VERSION ""

NS_ :

BS_:

BU_: VCM TCM ECM EBS ACM

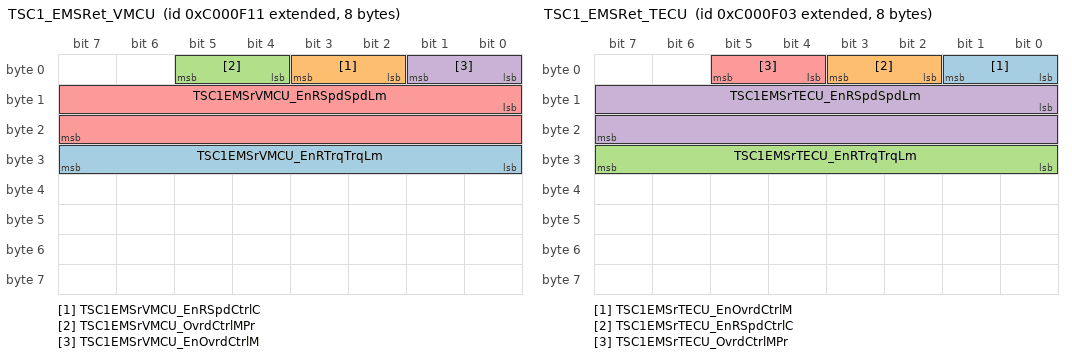
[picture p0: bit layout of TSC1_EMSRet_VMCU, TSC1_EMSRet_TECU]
BO_ 2348814097 TSC1_EMSRet_VMCU: 8 VCM
 SG_ TSC1EMSrVMCU_EnRTrqTrqLm : 24|8@1+ (1,-125) [-125|130] "Percent"  EBS,ECM
 SG_ TSC1EMSrVMCU_EnRSpdCtrlC : 2|2@1+ (1,0) [0|0] ""  EBS,ECM
 SG_ TSC1EMSrVMCU_OvrdCtrlMPr : 4|2@1+ (1,0) [0|0] ""  EBS,ECM
 SG_ TSC1EMSrVMCU_EnOvrdCtrlM : 0|2@1+ (1,0) [0|0] ""  EBS,ECM
 SG_ TSC1EMSrVMCU_EnRSpdSpdLm : 8|16@1+ (0.125,0) [0|8191.875] "rpm"  EBS,ECM

BO_ 2348814083 TSC1_EMSRet_TECU: 8 TCM
 SG_ TSC1EMSrTECU_EnOvrdCtrlM : 0|2@1+ (1,0) [0|0] ""  VCM,ECM
 SG_ TSC1EMSrTECU_EnRSpdCtrlC : 2|2@1+ (1,0) [0|0] ""  VCM,ECM
 SG_ TSC1EMSrTECU_EnRTrqTrqLm : 24|8@1+ (1,-125) [-125|130] "Percent"  VCM,ECM
 SG_ TSC1EMSrTECU_EnRSpdSpdLm : 8|16@1+ (0.125,0) [0|8191.875] "rpm"  ECM,VCM
 SG_ TSC1EMSrTECU_OvrdCtrlMPr : 4|2@1+ (1,0) [0|0] ""  VCM,ECM

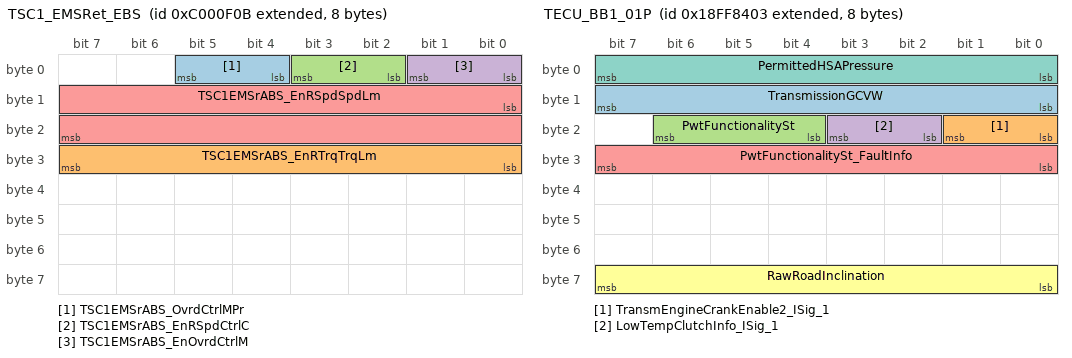
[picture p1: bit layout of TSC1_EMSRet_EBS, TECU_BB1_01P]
BO_ 2348814091 TSC1_EMSRet_EBS: 8 EBS
 SG_ TSC1EMSrABS_OvrdCtrlMPr : 4|2@1+ (1,0) [0|0] ""  TCM,ECM
 SG_ TSC1EMSrABS_EnRTrqTrqLm : 24|8@1+ (1,-125) [-125|130] "Percent"  ECM,TCM
 SG_ TSC1EMSrABS_EnRSpdCtrlC : 2|2@1+ (1,0) [0|0] ""  ECM,TCM
 SG_ TSC1EMSrABS_EnOvrdCtrlM : 0|2@1+ (1,0) [0|0] ""  TCM,ECM
 SG_ TSC1EMSrABS_EnRSpdSpdLm : 8|16@1+ (0.125,0) [0|8191.875] "rpm"  TCM,ECM

BO_ 2566846467 TRF1_X_TECU: 8 TCM
 SG_ TransmissionOilLevel_ISig_1 : 8|8@1+ (0.4,0) [0|102] "Percent"  VCM
 SG_ TransmissionOilTemp_ISig_1 : 32|16@1+ (0.03125,-273) [-273|1774.96875] "DegreeC"  ECM,VCM

BO_ 2565603075 TPDT_X_TCM: 8 TCM
 SG_ TPDT_SeqNo_TCM : 0|8@1+ (1,0) [0|0] ""  VCM

BO_ 2565603088 TPDT_X_RECU: 8 ACM
 SG_ TPDT_SeqNo_RECU : 0|8@1+ (1,0) [0|0] ""  VCM,ECM,EBS,TCM

BO_ 2565603087 TPDT_X_ECMRet: 8 ECM
 SG_ TPDT_SeqNo_ECMret : 0|8@1+ (1,0) [0|0] ""  VCM,EBS,TCM,ACM

BO_ 2565603072 TPDT_X_ECM: 8 ECM
 SG_ TPDT_SeqNo_ECM : 0|8@1+ (1,0) [0|0] ""  EBS,VCM,TCM,ACM

BO_ 2565603083 TPDT_X_EBS: 8 EBS
 SG_ TPDT_SeqNo_EBS : 0|8@1+ (1,0) [0|0] ""  VCM

BO_ 2565603133 TPDT_X_ACM: 8 ACM
 SG_ TPDT_SeqNo_ACM : 0|8@1+ (1,0) [0|0] ""  VCM

BO_ 2565668611 TPCM_X_TCM: 8 TCM
 SG_ TPCM_ControlByte_TCM : 0|8@1+ (1,0) [0|0] ""  VCM

BO_ 2565668624 TPCM_X_RECU: 8 ACM
 SG_ TPCM_ControlByte_RECU : 0|8@1+ (1,0) [0|0] ""  VCM,EBS,ECM,TCM

BO_ 2565668623 TPCM_X_ECMRet: 8 ECM
 SG_ TPCM_ControlByte_ECMret : 0|8@1+ (1,0) [0|0] ""  VCM,EBS,ACM,TCM

BO_ 2565668608 TPCM_X_ECM: 8 ECM
 SG_ TPCM_ControlByte_ECM : 0|8@1+ (1,0) [0|0] ""  VCM,EBS,TCM,ACM

BO_ 2565668619 TPCM_X_EBS: 8 EBS
 SG_ TPCM_ControlByte_EBS : 0|8@1+ (1,0) [0|0] ""  VCM

BO_ 2565668669 TPCM_X_ACM: 8 ACM
 SG_ TPCM_ControlByte_ACM : 0|8@1+ (1,0) [0|0] ""  VCM

BO_ 2566882307 TECU_BB1_01P: 8 TCM
 SG_ TransmissionGCVW : 8|8@1+ (1000,0) [0|255000] "kg"  ECM,VCM
 SG_ TransmEngineCrankEnable2_ISig_1 : 16|2@1+ (1,0) [0|0] ""  VCM
 SG_ PwtFunctionalitySt : 20|3@1+ (1,0) [0|0] ""  VCM
 SG_ LowTempClutchInfo_ISig_1 : 18|2@1+ (1,0) [0|0] ""  VCM
 SG_ PwtFunctionalitySt_FaultInfo : 24|8@1+ (1,0) [0|0] ""  VCM
 SG_ RawRoadInclination : 56|8@1+ (0.2,-25) [-25|26] "Percent"  VCM
 SG_ PermittedHSAPressure : 0|8@1+ (0.4,0) [0|102] "Percent"  EBS,VCM

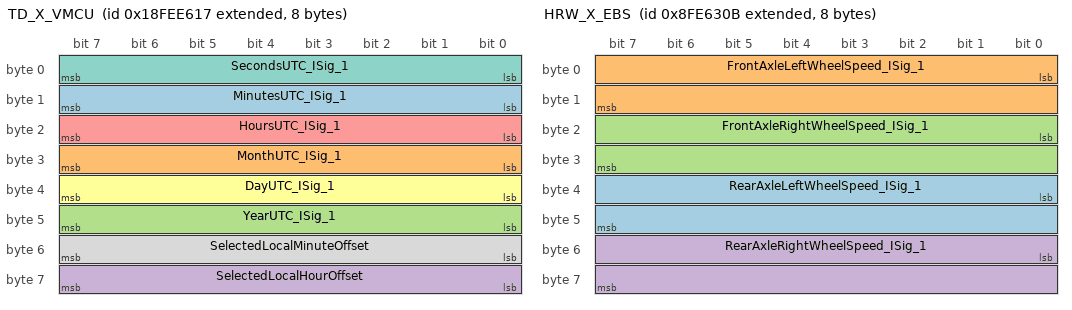
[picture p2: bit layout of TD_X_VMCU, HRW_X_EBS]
BO_ 2566841879 TD_X_VMCU: 8 VCM
 SG_ MinutesUTC_ISig_1 : 8|8@1+ (1,0) [0|255] "min"  ACM,EBS,ECM,TCM
 SG_ MonthUTC_ISig_1 : 24|8@1+ (1,0) [0|255] "Months"  ACM,ECM,EBS,TCM
 SG_ YearUTC_ISig_1 : 40|8@1+ (1,1985) [1985|2240] "Years"  ACM,TCM,ECM,EBS
 SG_ SelectedLocalHourOffset : 56|8@1+ (1,-125) [-125|130] "h"  EBS
 SG_ HoursUTC_ISig_1 : 16|8@1+ (1,0) [0|255] "h"  ECM,TCM,ACM,EBS
 SG_ DayUTC_ISig_1 : 32|8@1+ (0.25,0) [0|63.75] "Days"  EBS,ECM,TCM,ACM
 SG_ SecondsUTC_ISig_1 : 0|8@1+ (0.25,0) [0|63.75] "s"  ECM,ACM,TCM,EBS
 SG_ SelectedLocalMinuteOffset : 48|8@1+ (1,-125) [-125|130] "min"  EBS

BO_ 2365528579 TCM_02P_C01: 8 TCM
 SG_ RoadInclination_ISig_1 : 16|8@1+ (0.2,-25) [-25|26] "Percent"  ECM,VCM,EBS
 SG_ TransmOutputShaftSpeedSigned : 0|16@1+ (0.125,-4000) [-4000|4191.875] "rpm"  EBS,VCM

BO_ 2499792656 RECU_BB1_01P: 8 ACM
 SG_ DrivelineRetarderStat_ISig_1 : 0|2@1+ (1,0) [0|0] ""  VCM

BO_ 2566840592 RC_X_RECU: 19 ACM
 SG_ DrivelineRetarderLocation : 4|4@1+ (1,0) [0|0] ""  EBS,ECM,VCM
 SG_ DrivelineRetarderType : 0|4@1+ (1,0) [0|0] ""  EBS
 SG_ DrivelineRetarderRefTorque : 128|16@1+ (1,0) [0|65535] "Nm"  EBS,ECM,VCM,TCM

BO_ 2566840591 RC_X_EMSRet: 19 ECM
 SG_ EngRetConf_PerTrqAtP3 : 80|8@1+ (1,-125) [-125|130] "Percent"  TCM,EBS,VCM
 SG_ EngRetConf_RetSpeedAtP5 : 112|16@1+ (0.125,0) [0|8191.875] "rpm"  VCM,EBS,TCM
 SG_ EngRetConf_MaxRetSpeedP2 : 40|16@1+ (0.125,0) [0|8191.875] "rpm"  EBS,VCM,TCM
 SG_ EngRetConf_RetSpeedAtP3 : 64|16@1+ (0.125,0) [0|8191.875] "rpm"  TCM,VCM,EBS
 SG_ EngRetConf_PerTrqAtP4 : 104|8@1+ (1,-125) [-125|130] "Percent"  EBS,VCM,TCM
 SG_ EngRetConf_PerTrqAtP5 : 144|8@1+ (1,-125) [-125|130] "Percent"  EBS,TCM,VCM
 SG_ EngRetConf_RetCtrlMethod : 8|8@1+ (1,0) [0|255] "Step"  TCM,VCM,EBS
 SG_ ReferenceEngineRetarderTorque : 128|16@1+ (1,0) [0|65535] "Nm"  EBS,ACM,VCM,TCM
 SG_ EngRetConf_RetSpeedAtP4 : 88|16@1+ (0.125,0) [0|8191.875] "rpm"  VCM,TCM,EBS
 SG_ EngRetConf_PerTrqAtMaxSpeedP2 : 56|8@1+ (1,-125) [-125|130] "Percent"  VCM,EBS,TCM
 SG_ EngRetConf_speedAtIdleP1 : 16|16@1+ (0.125,0) [0|8191.875] "rpm"  VCM,TCM,EBS
 SG_ EngRetConf_PerTrqAtIdleP1 : 32|8@1+ (1,-125) [-125|130] "Percent"  TCM,VCM,EBS

BO_ 2671833640 PhysDiagRespMsg_F2_28_C01: 8 EBS
 SG_ PhysDiagRespSig_F2_28_ISig_1 : 0|64@1+ (1,0) [0|0] ""  VCM

BO_ 2671833617 PhysDiagRespMsg_F2_11_C01: 8 ACM
 SG_ PhysDiagRespSig_F2_11_ISig_1 : 0|64@1+ (1,0) [0|0] ""  VCM

BO_ 2671833361 PhysDiagRespMsg_F1_11_C01: 8 ACM
 SG_ PhysDiagRespSig_F1_11_ISig_1 : 0|64@1+ (1,0) [0|0] ""  VCM

BO_ 2671782130 PhysDiagReqMsg_28_F2_C01: 8 VCM
 SG_ PhysDiagReqSig_28_F2_ISig_1 : 0|64@1+ (1,0) [0|0] ""  EBS

BO_ 2671776242 PhysDiagReqMsg_11_F2_C01: 8 VCM
 SG_ PhysDiagReqSig_11_F2_ISig_1 : 0|64@1+ (1,0) [0|0] ""  ACM

BO_ 2671776241 PhysDiagReqMsg_11_F1_C01: 8 VCM
 SG_ PhysDiagReqSig_11_F1_ISig_1 : 0|64@1+ (1,0) [0|0] ""  ACM

BO_ 2566759457 PTODE_X_VMCU: 8 VCM
 SG_ Pto1EnableSwitch : 6|2@1+ (1,0) [0|0] ""  TCM
 SG_ Pto2EnableSwitch : 4|2@1+ (1,0) [0|0] ""  TCM

BO_ 2566759427 PTODE_X_TECU: 8 TCM
 SG_ Pto2EngagementConsent : 20|2@1+ (1,0) [0|0] ""  VCM
 SG_ Pto1EngagementConsent : 22|2@1+ (1,0) [0|0] ""  VCM

BO_ 2671850481 OBDFuncDiagMsg_C01: 8 VCM
 SG_ FuncDiagDataOBD_ISig_1 : 0|64@1+ (1,0) [0|0] ""  ACM

BO_ 2566844928 LFE_X_EMS: 8 ECM
 SG_ InstantaneousFuelEconomy : 16|16@1+ (0.001953125,0) [0|127.998046875] "km_per_l"  VCM
 SG_ EngineFuelRate_ISig_1 : 0|16@1+ (0.05,0) [0|3276.75] "l_per_h"  VCM

BO_ 2566825472 IMT1_X_EMS: 8 ECM
 SG_ EngineTurbo1BoostPressure_ISig_1 : 0|16@1+ (0.125,0) [0|8191.875] "kPa"  VCM,ACM

BO_ 2298372875 HRW_X_EBS: 8 EBS
 SG_ RearAxleLeftWheelSpeed_ISig_1 : 32|16@1+ (0.00390625,0) [0|255.99609375] "Km_per_h"  VCM,TCM,ECM
 SG_ FrontAxleLeftWheelSpeed_ISig_1 : 0|16@1+ (0.00390625,0) [0|255.99609375] "Km_per_h"  ECM,VCM,TCM
 SG_ FrontAxleRightWheelSpeed_ISig_1 : 16|16@1+ (0.00390625,0) [0|255.99609375] "Km_per_h"  TCM,ECM,VCM
 SG_ RearAxleRightWheelSpeed_ISig_1 : 48|16@1+ (0.00390625,0) [0|255.99609375] "Km_per_h"  VCM,TCM,ECM

BO_ 2566719744 HRLFC_X_EMS: 8 ECM
 SG_ HighResEngineTotalFuelUsed : 32|32@1+ (0.001,0) [0|4294967.295] "l"  VCM

BO_ 2566841600 HOURS_X_EMS: 8 ECM
 SG_ EngineRevolutions : 32|32@1+ (1000,0) [0|4294967295000] "r"  VCM

BO_ 2566801923 ETC7_X_TECU: 8 TCM
 SG_ TransmEngineCrankEnable_ISig_1 : 12|2@1+ (1,0) [0|0] ""  VCM

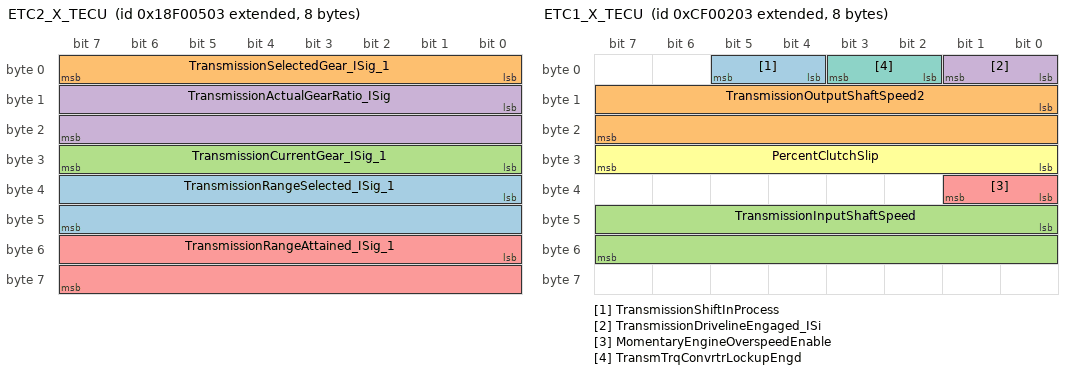
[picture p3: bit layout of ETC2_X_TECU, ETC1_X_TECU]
BO_ 2565866755 ETC2_X_TECU: 8 TCM
 SG_ TransmissionRangeSelected_ISig_1 : 32|16@1+ (1,0) [0|0] ""  VCM
 SG_ TransmissionSelectedGear_ISig_1 : 0|8@1+ (1,-125) [-125|130] "GearValue"  ECM,VCM
 SG_ TransmissionCurrentGear_ISig_1 : 24|8@1+ (1,-125) [-125|130] "GearValue"  VCM,ECM,EBS
 SG_ TransmissionActualGearRatio_ISig : 8|16@1+ (0.001,0) [0|65.535] "NotApplicable"  ECM,VCM
 SG_ TransmissionRangeAttained_ISig_1 : 48|16@1+ (1,0) [0|0] ""  VCM

BO_ 2364539395 ETC1_X_TECU: 8 TCM
 SG_ TransmissionShiftInProcess : 4|2@1+ (1,0) [0|0] ""  ECM,VCM,EBS
 SG_ TransmissionOutputShaftSpeed2 : 8|16@1+ (0.125,0) [0|8191.875] "rpm"  VCM
 SG_ TransmissionInputShaftSpeed : 40|16@1+ (0.125,0) [0|8191.875] "rpm"  EBS,VCM
 SG_ TransmissionDrivelineEngaged_ISi : 0|2@1+ (1,0) [0|0] ""  VCM,ECM,EBS
 SG_ MomentaryEngineOverspeedEnable : 32|2@1+ (1,0) [0|0] ""  VCM,ECM
 SG_ PercentClutchSlip : 24|8@1+ (0.4,0) [0|102] "Percent"  ECM,VCM,EBS
 SG_ TransmTrqConvrtrLockupEngd : 2|2@1+ (1,0) [0|0] ""  ECM,VCM

BO_ 2566843904 ET1_X_EMS: 8 ECM
 SG_ EngineCoolantTemp_stat_ISig_1 : 0|8@1+ (1,-40) [-40|215] "DegreeC"  VCM,ACM,TCM
 SG_ EngineOilTemperature : 16|16@1+ (0.03125,-273) [-273|1774.96875] "DegreeC"  TCM,VCM

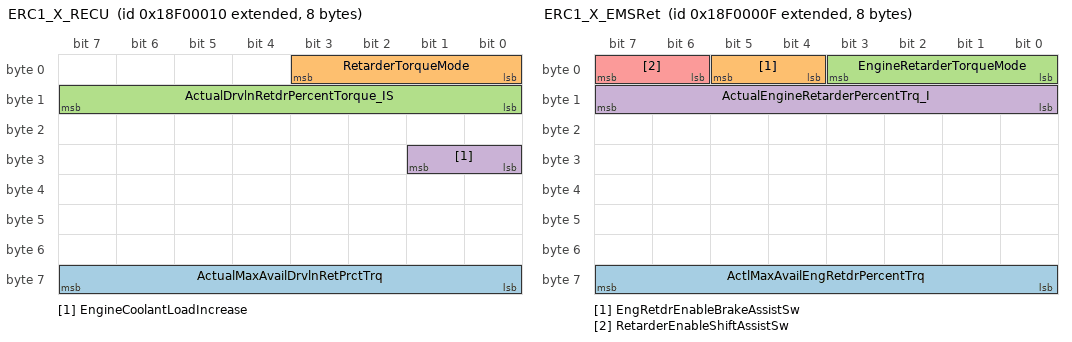
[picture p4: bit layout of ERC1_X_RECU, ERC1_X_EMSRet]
BO_ 2565865488 ERC1_X_RECU: 8 ACM
 SG_ ActualMaxAvailDrvlnRetPrctTrq : 56|8@1+ (1,-125) [-125|130] "Percent"  ECM,TCM,VCM,EBS
 SG_ RetarderTorqueMode : 0|4@1+ (1,0) [0|0] ""  ECM,VCM
 SG_ ActualDrvlnRetdrPercentTorque_IS : 8|8@1+ (1,-125) [-125|130] "Percent"  EBS,VCM,ECM,TCM
 SG_ EngineCoolantLoadIncrease : 24|2@1+ (1,0) [0|0] ""  VCM,ECM

BO_ 2565865487 ERC1_X_EMSRet: 8 ECM
 SG_ ActlMaxAvailEngRetdrPercentTrq : 56|8@1+ (1,-125) [-125|130] "Percent"  VCM,EBS
 SG_ EngRetdrEnableBrakeAssistSw : 4|2@1+ (1,0) [0|0] ""  VCM,TCM
 SG_ EngineRetarderTorqueMode : 0|4@1+ (1,0) [0|0] ""  VCM
 SG_ ActualEngineRetarderPercentTrq_I : 8|8@1+ (1,-125) [-125|130] "Percent"  EBS,TCM,VCM,ACM
 SG_ RetarderEnableShiftAssistSw : 6|2@1+ (1,0) [0|0] ""  TCM,VCM

BO_ 2566864640 EMS_BB1_01P: 8 ECM
 SG_ EngineActiveStatus_ISig_1 : 8|4@1+ (1,0) [0|0] ""  TCM,EBS,VCM
 SG_ DrvrDemandEngRetdrPercentTrq : 0|8@1+ (1,-125) [-125|130] "Percent"  VCM,EBS

BO_ 2364541440 EGF1_X_EMS: 8 ECM
 SG_ EngineIntakeAirRate : 16|16@1+ (0.05,0) [0|3276.75] "Kg_per_h"  VCM

BO_ 2566844160 EFLP1_X_EMS: 8 ECM
 SG_ EngineOilPressure : 24|8@1+ (4,0) [0|1020] "kPa"  VCM
 SG_ EngineOilLevel : 16|8@1+ (0.4,0) [0|102] "Percent"  VCM

BO_ 2566840064 EEC3_X_EMS: 8 ECM
 SG_ NominalFrictionPercentTorque_ISi : 0|8@1+ (1,-125) [-125|130] "Percent"  ACM,TCM,VCM,EBS

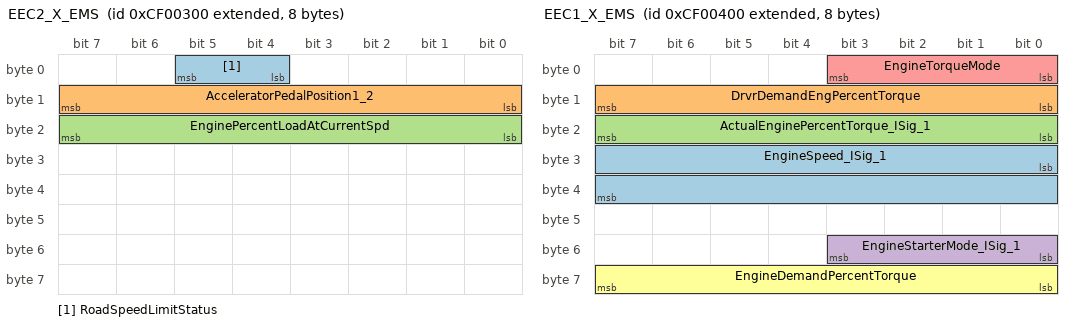
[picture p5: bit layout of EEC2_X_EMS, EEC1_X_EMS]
BO_ 2364539648 EEC2_X_EMS: 8 ECM
 SG_ RoadSpeedLimitStatus : 4|2@1+ (1,0) [0|0] ""  TCM,VCM
 SG_ AcceleratorPedalPosition1_2 : 8|8@1+ (0.4,0) [0|102] "Percent"  TCM,VCM
 SG_ EnginePercentLoadAtCurrentSpd : 16|8@1+ (1,0) [0|255] "Percent"  TCM,ACM,VCM

BO_ 2364539904 EEC1_X_EMS: 8 ECM
 SG_ EngineSpeed_ISig_1 : 24|16@1+ (0.125,0) [0|8191.875] "rpm"  VCM,ACM,TCM,EBS
 SG_ DrvrDemandEngPercentTorque : 8|8@1+ (1,-125) [-125|130] "Percent"  VCM,TCM,EBS
 SG_ ActualEnginePercentTorque_ISig_1 : 16|8@1+ (1,-125) [-125|130] "Percent"  TCM,EBS,VCM
 SG_ EngineStarterMode_ISig_1 : 48|4@1+ (1,0) [0|0] ""  VCM
 SG_ EngineTorqueMode : 0|4@1+ (1,0) [0|0] ""  TCM,EBS,VCM
 SG_ EngineDemandPercentTorque : 56|8@1+ (1,-125) [-125|130] "Percent"  VCM,TCM

BO_ 2566841088 EC1_X_EMS: 39 ECM
 SG_ EngConf_EngSpeedAt_P3 : 48|16@1+ (0.125,0) [0|8191.875] "rpm"  VCM,TCM,EBS
 SG_ EngConf_EngSpeedAtIdle_P1 : 0|16@1+ (0.125,0) [0|8191.875] "rpm"  EBS,VCM,TCM
 SG_ EngConf_EngTorqueAtIdle_P1 : 16|8@1+ (1,-125) [-125|130] "Percent"  VCM,EBS,TCM
 SG_ EngConf_EngSpeedAt_P4 : 72|16@1+ (0.125,0) [0|8191.875] "rpm"  EBS,VCM,TCM
 SG_ EngineReferenceTorque_ISig_1 : 152|16@1+ (1,0) [0|65535] "Nm"  VCM,EBS,TCM,ACM
 SG_ EngConf_EngTorqueAt_P5 : 112|8@1+ (1,-125) [-125|130] "Percent"  EBS,VCM,TCM
 SG_ EngConf_EngSpeedAtHighIdle_P6 : 120|16@1+ (0.125,0) [0|8191.875] "rpm"  EBS,VCM,TCM
 SG_ EngConf_EngTorqueAt_P3 : 64|8@1+ (1,-125) [-125|130] "Percent"  VCM,TCM,EBS
 SG_ EngConf_EngSpeedAt_P5 : 96|16@1+ (0.125,0) [0|8191.875] "rpm"  VCM,EBS,TCM
 SG_ EngConf_EngMaxMomOvSpeed_P7 : 168|16@1+ (0.125,0) [0|8191.875] "rpm"  VCM,TCM,EBS
 SG_ EngConf_EngTorqueAt_P4 : 88|8@1+ (1,-125) [-125|130] "Percent"  EBS,VCM,TCM
 SG_ EngConf_EngTorqueAt_P2 : 40|8@1+ (1,-125) [-125|130] "Percent"  TCM,VCM,EBS
 SG_ EngConf_EngSpeedAt_P2 : 24|16@1+ (0.125,0) [0|8191.875] "rpm"  EBS,VCM,TCM
 SG_ EngConf_MaxMomOverrideTimeLim : 184|8@1+ (0.1,0) [0|25.5] "s"  TCM,EBS,VCM

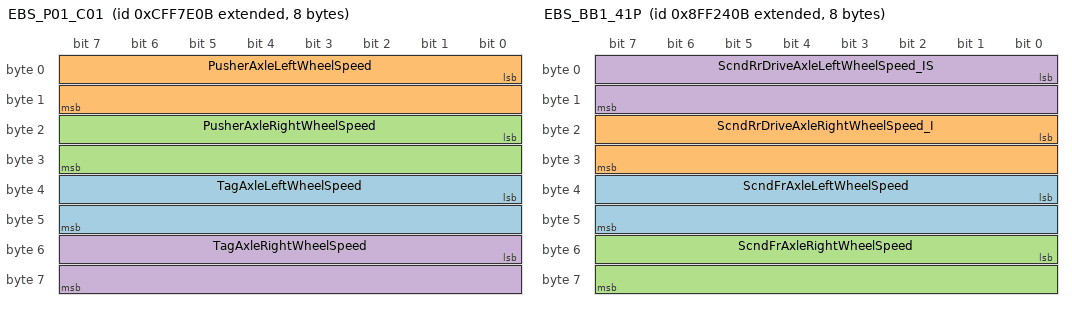
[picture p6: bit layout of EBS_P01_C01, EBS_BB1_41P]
BO_ 2365554187 EBS_P01_C01: 8 EBS
 SG_ TagAxleLeftWheelSpeed : 32|16@1+ (0.00390625,0) [0|255.99609375] "Km_per_h"  VCM
 SG_ PusherAxleLeftWheelSpeed : 0|16@1+ (0.00390625,0) [0|255.99609375] "Km_per_h"  VCM
 SG_ PusherAxleRightWheelSpeed : 16|16@1+ (0.00390625,0) [0|255.99609375] "Km_per_h"  VCM
 SG_ TagAxleRightWheelSpeed : 48|16@1+ (0.00390625,0) [0|255.99609375] "Km_per_h"  VCM

BO_ 2298445579 EBS_BB1_44P: 8 EBS
 SG_ ThrdRrDriveAxLeftWheelSpeed_ISig : 16|16@1+ (0.00390625,0) [0|255.99609375] "Km_per_h"  ECM,TCM,VCM
 SG_ ThrdRrDriveAxRightWheelSpeed_ISi : 0|16@1+ (0.00390625,0) [0|255.99609375] "Km_per_h"  ECM,VCM,TCM

BO_ 2566852619 EBS_BB1_43P: 8 EBS
 SG_ WheelCircumference_TireId : 8|8@1+ (1,0) [0|255] "NotApplicable"  VCM
 SG_ WheelCircumference_Value : 0|8@1+ (0.06,0) [0|15.3] "m"  VCM

BO_ 2298422539 EBS_BB1_42P: 8 EBS
 SG_ ActualPusherWheelAngle : 0|16@1+ (0.01,-50) [-50|605.35] "deg"  VCM
 SG_ ActualTagWheelAngle : 16|16@1+ (0.01,-50) [-50|605.35] "deg"  VCM

BO_ 2298422283 EBS_BB1_41P: 8 EBS
 SG_ ScndFrAxleLeftWheelSpeed : 32|16@1+ (0.00390625,0) [0|255.99609375] "Km_per_h"  ECM,TCM,VCM
 SG_ ScndRrDriveAxleRightWheelSpeed_I : 16|16@1+ (0.00390625,0) [0|255.99609375] "Km_per_h"  VCM,TCM,ECM
 SG_ ScndFrAxleRightWheelSpeed : 48|16@1+ (0.00390625,0) [0|255.99609375] "Km_per_h"  VCM,ECM,TCM
 SG_ ScndRrDriveAxleLeftWheelSpeed_IS : 0|16@1+ (0.00390625,0) [0|255.99609375] "Km_per_h"  VCM,ECM,TCM

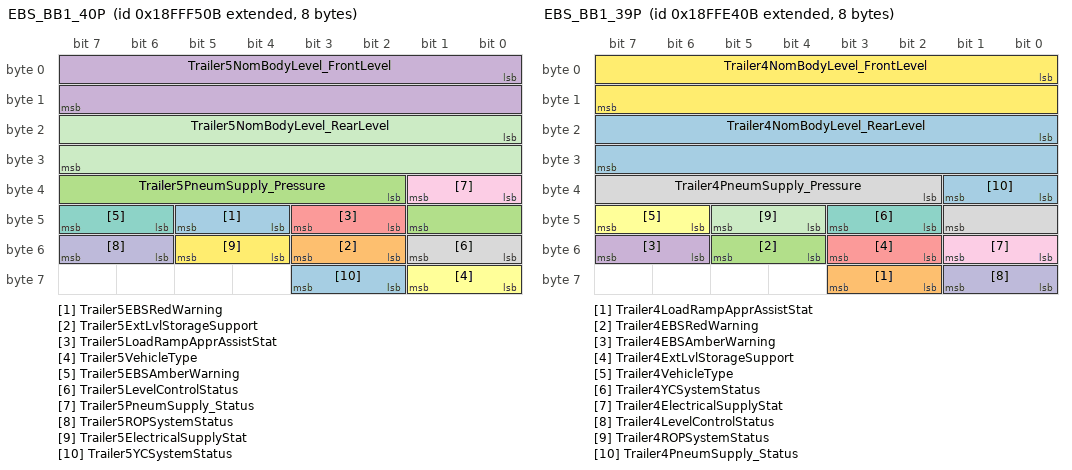
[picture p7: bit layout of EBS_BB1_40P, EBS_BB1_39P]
BO_ 2566911243 EBS_BB1_40P: 8 EBS
 SG_ Trailer5EBSRedWarning : 44|2@1+ (1,0) [0|0] ""  VCM
 SG_ Trailer5ExtLvlStorageSupport : 50|2@1+ (1,0) [0|0] ""  VCM
 SG_ Trailer5PneumSupply_Pressure : 34|8@1+ (5,0) [0|1275] "kPa"  VCM
 SG_ Trailer5NomBodyLevel_FrontLevel : 0|16@1+ (1,0) [0|65535] "mm"  VCM
 SG_ Trailer5LoadRampApprAssistStat : 42|2@1+ (1,0) [0|0] ""  VCM
 SG_ Trailer5VehicleType : 56|2@1+ (1,0) [0|0] ""  VCM
 SG_ Trailer5EBSAmberWarning : 46|2@1+ (1,0) [0|0] ""  VCM
 SG_ Trailer5LevelControlStatus : 48|2@1+ (1,0) [0|0] ""  VCM
 SG_ Trailer5PneumSupply_Status : 32|2@1+ (1,0) [0|0] ""  VCM
 SG_ Trailer5ROPSystemStatus : 54|2@1+ (1,0) [0|0] ""  VCM
 SG_ Trailer5NomBodyLevel_RearLevel : 16|16@1+ (1,0) [0|65535] "mm"  VCM
 SG_ Trailer5ElectricalSupplyStat : 52|2@1+ (1,0) [0|0] ""  VCM
 SG_ Trailer5YCSystemStatus : 58|2@1+ (1,0) [0|0] ""  VCM

BO_ 2566906891 EBS_BB1_39P: 8 EBS
 SG_ Trailer4NomBodyLevel_RearLevel : 16|16@1+ (1,0) [0|65535] "mm"  VCM
 SG_ Trailer4LoadRampApprAssistStat : 58|2@1+ (1,0) [0|0] ""  VCM
 SG_ Trailer4EBSRedWarning : 52|2@1+ (1,0) [0|0] ""  VCM
 SG_ Trailer4EBSAmberWarning : 54|2@1+ (1,0) [0|0] ""  VCM
 SG_ Trailer4ExtLvlStorageSupport : 50|2@1+ (1,0) [0|0] ""  VCM
 SG_ Trailer4VehicleType : 46|2@1+ (1,0) [0|0] ""  VCM
 SG_ Trailer4YCSystemStatus : 42|2@1+ (1,0) [0|0] ""  VCM
 SG_ Trailer4PneumSupply_Pressure : 34|8@1+ (5,0) [0|1275] "kPa"  VCM
 SG_ Trailer4ElectricalSupplyStat : 48|2@1+ (1,0) [0|0] ""  VCM
 SG_ Trailer4LevelControlStatus : 56|2@1+ (1,0) [0|0] ""  VCM
 SG_ Trailer4ROPSystemStatus : 44|2@1+ (1,0) [0|0] ""  VCM
 SG_ Trailer4NomBodyLevel_FrontLevel : 0|16@1+ (1,0) [0|65535] "mm"  VCM
 SG_ Trailer4PneumSupply_Status : 32|2@1+ (1,0) [0|0] ""  VCM

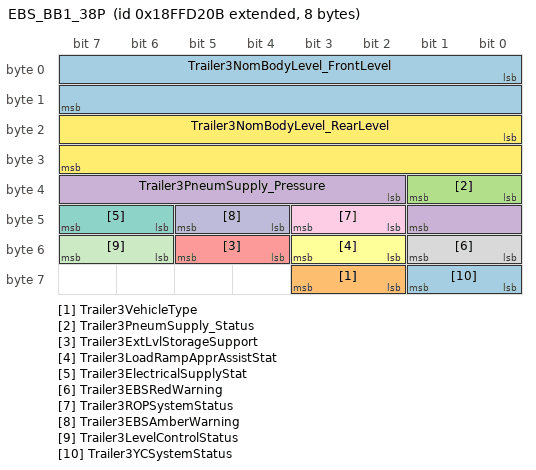
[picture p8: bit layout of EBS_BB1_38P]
BO_ 2566902283 EBS_BB1_38P: 8 EBS
 SG_ Trailer3NomBodyLevel_FrontLevel : 0|16@1+ (1,0) [0|65535] "mm"  VCM
 SG_ Trailer3VehicleType : 58|2@1+ (1,0) [0|0] ""  VCM
 SG_ Trailer3PneumSupply_Status : 32|2@1+ (1,0) [0|0] ""  VCM
 SG_ Trailer3PneumSupply_Pressure : 34|8@1+ (5,0) [0|1275] "kPa"  VCM
 SG_ Trailer3ExtLvlStorageSupport : 52|2@1+ (1,0) [0|0] ""  VCM
 SG_ Trailer3LoadRampApprAssistStat : 50|2@1+ (1,0) [0|0] ""  VCM
 SG_ Trailer3ElectricalSupplyStat : 46|2@1+ (1,0) [0|0] ""  VCM
 SG_ Trailer3EBSRedWarning : 48|2@1+ (1,0) [0|0] ""  VCM
 SG_ Trailer3ROPSystemStatus : 42|2@1+ (1,0) [0|0] ""  VCM
 SG_ Trailer3EBSAmberWarning : 44|2@1+ (1,0) [0|0] ""  VCM
 SG_ Trailer3LevelControlStatus : 54|2@1+ (1,0) [0|0] ""  VCM
 SG_ Trailer3NomBodyLevel_RearLevel : 16|16@1+ (1,0) [0|65535] "mm"  VCM
 SG_ Trailer3YCSystemStatus : 56|2@1+ (1,0) [0|0] ""  VCM

CM_ BO_ 2348814097 "PGN 0 Torque/Speed Control 1, From VMCU to EMS Retarder";
CM_ SG_ 2348814097 TSC1EMSrVMCU_EnRTrqTrqLm "254 Error ; 255 Not available";
CM_ SG_ 2348814097 TSC1EMSrVMCU_EnRSpdSpdLm "65024 - 65279 Error ; 65280 - 65535 Not available";
CM_ BO_ 2348814083 "PGN 0 Torque/Speed Control 1, From TECU to EMS Retarder";
CM_ SG_ 2348814083 TSC1EMSrTECU_EnRTrqTrqLm "254 Error ; 255 Not available";
CM_ SG_ 2348814083 TSC1EMSrTECU_EnRSpdSpdLm "65024 - 65279 Error ; 65280 - 65535 Not available";
CM_ BO_ 2348814091 "PGN 0 Torque/Speed Control 1, From EBS to EMS Retarder";
CM_ SG_ 2348814091 TSC1EMSrABS_EnRTrqTrqLm "254 Error ; 255 Not available";
CM_ SG_ 2348814091 TSC1EMSrABS_EnRSpdSpdLm "65024 - 65279 Error ; 65280 - 65535 Not available";
CM_ BO_ 2566846467 "PGN 65272 Transmission Fluids 1";
CM_ BO_ 2566841879 "PGN 65254 Time/Date, From HMIIOM";
CM_ BO_ 2566840592 "PGN 65249 Retarder Configuration from RECU";
CM_ BO_ 2566840591 "PGN 65249 Retarder Configuration from EMSRetarder";
CM_ BO_ 2566759457 "PGN 64932 PTO Drive Engagement";
CM_ BO_ 2566759427 "PGN 64932 PTO Drive Engagement
";
CM_ BO_ 2566844928 "PGN 65266 Fuel Economy (Liquid)";
CM_ BO_ 2566825472 "PGN 65190 Intake Manifold Information 1";
CM_ BO_ 2298372875 "PGN 65134 High Resolution Wheel Speed";
CM_ BO_ 2566719744 "PGN 64777 High Resolution Fuel Consumption (Liquid)";
CM_ BO_ 2566841600 "PGN 65253 Engine Hours, Revolutions";
CM_ BO_ 2566801923 "PGN 65098 Electronic Transmission Controller 7";
CM_ BO_ 2565866755 "PGN 61445 Electronic Transmission Controller 2";
CM_ BO_ 2364539395 "PGN 61442 Electronic Transmission Controller 1";
CM_ BO_ 2566843904 "PGN 65262 Engine Temperature 1";
CM_ BO_ 2565865488 "PGN 61440 Electronic Retarder Controller 1 from RECU";
CM_ BO_ 2565865487 "PGN 61440 Electronic Retarder Controller 1";
CM_ BO_ 2364541440 "PGN 61450 Flow rates of Air and mixed gasses into the engine cylinders.
Note: SAE recommended rate 50ms, but 500ms set due to current usage only for logging.";
CM_ BO_ 2566844160 "PGN 65263 Engine Fluid Level/Pressure 1";
CM_ BO_ 2566840064 "PGN 65247 Electronic Engine Controller 3";
CM_ BO_ 2364539648 "PGN 61443 Electronic Engine Controller 2";
CM_ BO_ 2364539904 "PGN 61444 Electronic Engine Controller 1";
CM_ BO_ 2566841088 "PGN 65251 Engine Configuration 1";
CM_ SG_ 2566911243 Trailer5PneumSupply_Pressure "254 Error ; 255 Not available";
CM_ SG_ 2566906891 Trailer4PneumSupply_Pressure "254 Error ; 255 Not available";
CM_ SG_ 2566902283 Trailer3PneumSupply_Pressure "254 Error ; 255 Not available";
BA_DEF_ BO_  "GenMsgStartDelayTime" INT 0 0;
BA_DEF_ BO_  "GenMsgDelayTime" INT 0 0;
BA_DEF_ BO_  "GenMsgNrOfRepetition" INT 0 0;
BA_DEF_ BO_  "GenMsgCycleTimeFast" INT 0 0;
BA_DEF_ BO_  "GenMsgCycleTime" INT 0 0;
BA_DEF_ BO_  "GenMsgSendType" ENUM  "Cyclic","NotUsed","NotUsed","NotUsed","NotUsed","NotUsed","NotUsed","IfActive","NoMsgSendType","NotUsed";
BA_DEF_ SG_  "GenSigStartValue" INT 0 0;
BA_DEF_ SG_  "GenSigCycleTimeActive" INT 0 0;
BA_DEF_ SG_  "GenSigCycleTime" INT 0 0;
BA_DEF_ SG_  "GenSigSendType" ENUM  "Cyclic","OnWrite","OnWriteWithRepetition","OnChange","OnChangeWithRepetition","IfActive","IfActiveWithRepetition","NoSigSendType","NotUsed","NotUsed","NotUsed","NotUsed","NotUsed";
BA_DEF_ BO_  "VFrameFormat" ENUM  "StandardCAN","ExtendedCAN","reserved","J1939PG","reserved","reserved","reserved","reserved","reserved","reserved","reserved","reserved","reserved","reserved","StandardCAN_FD","ExtendedCAN_FD";
BA_DEF_ BO_  "TpJ1939VarDlc" ENUM  "No","Yes";
BA_DEF_ SG_  "SigType" ENUM  "Default","Range","RangeSigned","ASCII","Discrete","Control","ReferencePGN","DTC","StringDelimiter","StringLength","StringLengthControl";
BA_DEF_ SG_  "SeToolVersion_SIGNAL" STRING ;
BA_DEF_ SG_  "SeToolUniqueID_SIGNAL" STRING ;
BA_DEF_ SG_  "SeToolOwnerSigGroup_SIGNAL" STRING ;
BA_DEF_ SG_  "SeToolOwnerSigGroupID_SIGNAL" STRING ;
BA_DEF_ SG_  "SeToolName_SIGNAL" STRING ;
BA_DEF_ SG_  "SeToolItemID_SIGNAL" STRING ;
BA_DEF_ SG_  "SeToolAncestorID_SIGNAL" STRING ;
BA_DEF_ SG_  "Platform_VMCU1_Sig" ENUM  "No","Yes";
BA_DEF_ SG_  "NeedsUpdateBit" ENUM  "No","Yes";
BA_DEF_ SG_  "GenSigMaxLatency" INT 0 65535;
BA_DEF_ SG_  "GenSigILSupport" ENUM  "Yes","No";
BA_DEF_ BO_  "GenMsgILSupport" ENUM  "No","Yes";
BA_DEF_ SG_  "E2EProfile" STRING ;
BA_DEF_ SG_  "E2EDataLength" INT 0 65535;
BA_DEF_ SG_  "E2EDataId" INT 0 65535;
BA_DEF_ BO_  "DiagUUDTResponse" ENUM  "No","Yes";
BA_DEF_ BO_  "DiagState" ENUM  "No","Yes";
BA_DEF_ BO_  "DiagResponse" ENUM  "No","Yes";
BA_DEF_ BO_  "DiagRequest" ENUM  "No","Yes";
BA_DEF_ BO_  "DiagConnection" HEX 0 65535;
BA_DEF_ BO_  "CanTpFcFrameId" HEX 0 2147483647;
BA_DEF_ BO_  "CanTpBs" INT 0 255;
BA_DEF_ SG_  "SystemSignalLongSymbol" STRING ;
BA_DEF_REL_ BU_SG_REL_  "GenSigTimeoutTime" INT 0 65535;
BA_DEF_REL_ BU_SG_REL_  "GenSigFirstTimeoutTime" INT 0 65535;
BA_DEF_DEF_  "GenMsgStartDelayTime" 0;
BA_DEF_DEF_  "GenMsgDelayTime" 0;
BA_DEF_DEF_  "GenMsgNrOfRepetition" 0;
BA_DEF_DEF_  "GenMsgCycleTimeFast" 0;
BA_DEF_DEF_  "GenMsgCycleTime" 0;
BA_DEF_DEF_  "GenMsgSendType" "Cyclic";
BA_DEF_DEF_  "GenSigStartValue" 0;
BA_DEF_DEF_  "GenSigCycleTimeActive" 0;
BA_DEF_DEF_  "GenSigCycleTime" 0;
BA_DEF_DEF_  "GenSigSendType" "Cyclic";
BA_DEF_DEF_  "VFrameFormat" "ExtendedCAN";
BA_DEF_DEF_  "TpJ1939VarDlc" "No";
BA_DEF_DEF_  "SigType" "Default";
BA_DEF_DEF_  "SeToolVersion_SIGNAL" "";
BA_DEF_DEF_  "SeToolUniqueID_SIGNAL" "";
BA_DEF_DEF_  "SeToolOwnerSigGroup_SIGNAL" "";
BA_DEF_DEF_  "SeToolOwnerSigGroupID_SIGNAL" "";
BA_DEF_DEF_  "SeToolName_SIGNAL" "";
BA_DEF_DEF_  "SeToolItemID_SIGNAL" "";
BA_DEF_DEF_  "SeToolAncestorID_SIGNAL" "";
BA_DEF_DEF_  "Platform_VMCU1_Sig" "No";
BA_DEF_DEF_  "NeedsUpdateBit" "No";
BA_DEF_DEF_  "GenSigMaxLatency" 0;
BA_DEF_DEF_  "GenSigILSupport" "Yes";
BA_DEF_DEF_  "GenMsgILSupport" "Yes";
BA_DEF_DEF_  "E2EProfile" "none";
BA_DEF_DEF_  "E2EDataLength" 0;
BA_DEF_DEF_  "E2EDataId" 0;
BA_DEF_DEF_  "DiagUUDTResponse" "No";
BA_DEF_DEF_  "DiagState" "No";
BA_DEF_DEF_  "DiagResponse" "No";
BA_DEF_DEF_  "DiagRequest" "No";
BA_DEF_DEF_  "DiagConnection" 0;
BA_DEF_DEF_  "CanTpFcFrameId" 2147483647;
BA_DEF_DEF_  "CanTpBs" 255;
BA_DEF_DEF_REL_ "GenSigTimeoutTime" 0;
BA_DEF_DEF_REL_ "GenSigFirstTimeoutTime" 0;
BA_DEF_DEF_  "SystemSignalLongSymbol" "";
BA_ "GenMsgSendType" BO_ 2348814097 7;
BA_ "GenMsgCycleTimeFast" BO_ 2348814097 50;
BA_ "GenMsgNrOfRepetition" BO_ 2348814097 3;
BA_ "VFrameFormat" BO_ 2348814097 3;
BA_ "GenMsgSendType" BO_ 2348814083 7;
BA_ "GenMsgCycleTimeFast" BO_ 2348814083 50;
BA_ "GenMsgNrOfRepetition" BO_ 2348814083 3;
BA_ "VFrameFormat" BO_ 2348814083 3;
BA_ "GenMsgSendType" BO_ 2348814091 7;
BA_ "GenMsgCycleTimeFast" BO_ 2348814091 50;
BA_ "GenMsgNrOfRepetition" BO_ 2348814091 3;
BA_ "VFrameFormat" BO_ 2348814091 3;
BA_ "GenMsgCycleTime" BO_ 2566846467 1000;
BA_ "GenMsgStartDelayTime" BO_ 2566846467 125;
BA_ "VFrameFormat" BO_ 2566846467 3;
BA_ "GenMsgILSupport" BO_ 2565603075 0;
BA_ "GenMsgSendType" BO_ 2565603075 8;
BA_ "VFrameFormat" BO_ 2565603075 3;
BA_ "GenMsgILSupport" BO_ 2565603088 0;
BA_ "GenMsgSendType" BO_ 2565603088 8;
BA_ "VFrameFormat" BO_ 2565603088 3;
BA_ "GenMsgILSupport" BO_ 2565603087 0;
BA_ "GenMsgSendType" BO_ 2565603087 8;
BA_ "VFrameFormat" BO_ 2565603087 3;
BA_ "GenMsgILSupport" BO_ 2565603072 0;
BA_ "GenMsgSendType" BO_ 2565603072 8;
BA_ "VFrameFormat" BO_ 2565603072 3;
BA_ "GenMsgILSupport" BO_ 2565603083 0;
BA_ "GenMsgSendType" BO_ 2565603083 8;
BA_ "VFrameFormat" BO_ 2565603083 3;
BA_ "GenMsgILSupport" BO_ 2565603133 0;
BA_ "GenMsgSendType" BO_ 2565603133 8;
BA_ "VFrameFormat" BO_ 2565603133 3;
BA_ "GenMsgILSupport" BO_ 2565668611 0;
BA_ "GenMsgSendType" BO_ 2565668611 8;
BA_ "VFrameFormat" BO_ 2565668611 3;
BA_ "GenMsgILSupport" BO_ 2565668624 0;
BA_ "GenMsgSendType" BO_ 2565668624 8;
BA_ "VFrameFormat" BO_ 2565668624 3;
BA_ "GenMsgILSupport" BO_ 2565668623 0;
BA_ "GenMsgSendType" BO_ 2565668623 8;
BA_ "VFrameFormat" BO_ 2565668623 3;
BA_ "GenMsgILSupport" BO_ 2565668608 0;
BA_ "GenMsgSendType" BO_ 2565668608 8;
BA_ "VFrameFormat" BO_ 2565668608 3;
BA_ "GenMsgILSupport" BO_ 2565668619 0;
BA_ "GenMsgSendType" BO_ 2565668619 8;
BA_ "VFrameFormat" BO_ 2565668619 3;
BA_ "GenMsgILSupport" BO_ 2565668669 0;
BA_ "GenMsgSendType" BO_ 2565668669 8;
BA_ "VFrameFormat" BO_ 2565668669 3;
BA_ "GenMsgCycleTime" BO_ 2566882307 100;
BA_ "GenMsgStartDelayTime" BO_ 2566882307 5;
BA_ "VFrameFormat" BO_ 2566882307 3;
BA_ "GenMsgCycleTime" BO_ 2566841879 250;
BA_ "GenMsgStartDelayTime" BO_ 2566841879 125;
BA_ "VFrameFormat" BO_ 2566841879 3;
BA_ "GenMsgCycleTime" BO_ 2365528579 25;
BA_ "VFrameFormat" BO_ 2365528579 3;
BA_ "GenMsgCycleTime" BO_ 2499792656 150;
BA_ "GenMsgStartDelayTime" BO_ 2499792656 15;
BA_ "VFrameFormat" BO_ 2499792656 3;
BA_ "GenMsgCycleTime" BO_ 2566840592 5000;
BA_ "GenMsgStartDelayTime" BO_ 2566840592 150;
BA_ "VFrameFormat" BO_ 2566840592 3;
BA_ "GenMsgCycleTime" BO_ 2566840591 5000;
BA_ "GenMsgDelayTime" BO_ 2566840591 350;
BA_ "GenMsgStartDelayTime" BO_ 2566840591 1555;
BA_ "VFrameFormat" BO_ 2566840591 3;
BA_ "DiagConnection" BO_ 2671833640 61992;
BA_ "DiagResponse" BO_ 2671833640 1;
BA_ "GenMsgILSupport" BO_ 2671833640 0;
BA_ "GenMsgSendType" BO_ 2671833640 8;
BA_ "VFrameFormat" BO_ 2671833640 3;
BA_ "DiagConnection" BO_ 2671833617 61969;
BA_ "DiagResponse" BO_ 2671833617 1;
BA_ "GenMsgILSupport" BO_ 2671833617 0;
BA_ "GenMsgSendType" BO_ 2671833617 8;
BA_ "VFrameFormat" BO_ 2671833617 3;
BA_ "DiagConnection" BO_ 2671833361 61713;
BA_ "DiagResponse" BO_ 2671833361 1;
BA_ "GenMsgILSupport" BO_ 2671833361 0;
BA_ "GenMsgSendType" BO_ 2671833361 8;
BA_ "VFrameFormat" BO_ 2671833361 3;
BA_ "DiagConnection" BO_ 2671782130 61992;
BA_ "DiagRequest" BO_ 2671782130 1;
BA_ "GenMsgILSupport" BO_ 2671782130 0;
BA_ "GenMsgSendType" BO_ 2671782130 8;
BA_ "VFrameFormat" BO_ 2671782130 3;
BA_ "DiagConnection" BO_ 2671776242 61969;
BA_ "DiagRequest" BO_ 2671776242 1;
BA_ "GenMsgILSupport" BO_ 2671776242 0;
BA_ "GenMsgSendType" BO_ 2671776242 8;
BA_ "VFrameFormat" BO_ 2671776242 3;
BA_ "DiagConnection" BO_ 2671776241 61713;
BA_ "DiagRequest" BO_ 2671776241 1;
BA_ "GenMsgILSupport" BO_ 2671776241 0;
BA_ "GenMsgSendType" BO_ 2671776241 8;
BA_ "VFrameFormat" BO_ 2671776241 3;
BA_ "GenMsgCycleTime" BO_ 2566759457 100;
BA_ "GenMsgStartDelayTime" BO_ 2566759457 10;
BA_ "VFrameFormat" BO_ 2566759457 3;
BA_ "GenMsgCycleTime" BO_ 2566759427 100;
BA_ "GenMsgStartDelayTime" BO_ 2566759427 55;
BA_ "VFrameFormat" BO_ 2566759427 3;
BA_ "DiagConnection" BO_ 2671850481 61713;
BA_ "DiagState" BO_ 2671850481 1;
BA_ "GenMsgILSupport" BO_ 2671850481 0;
BA_ "GenMsgSendType" BO_ 2671850481 8;
BA_ "VFrameFormat" BO_ 2671850481 3;
BA_ "GenMsgCycleTime" BO_ 2566844928 100;
BA_ "GenMsgStartDelayTime" BO_ 2566844928 15;
BA_ "VFrameFormat" BO_ 2566844928 3;
BA_ "GenMsgCycleTime" BO_ 2566825472 500;
BA_ "GenMsgStartDelayTime" BO_ 2566825472 50;
BA_ "VFrameFormat" BO_ 2566825472 3;
BA_ "GenMsgCycleTime" BO_ 2298372875 20;
BA_ "VFrameFormat" BO_ 2298372875 3;
BA_ "GenMsgCycleTime" BO_ 2566719744 1000;
BA_ "GenMsgStartDelayTime" BO_ 2566719744 55;
BA_ "VFrameFormat" BO_ 2566719744 3;
BA_ "GenMsgCycleTime" BO_ 2566841600 5000;
BA_ "GenMsgStartDelayTime" BO_ 2566841600 1345;
BA_ "VFrameFormat" BO_ 2566841600 3;
BA_ "GenMsgCycleTime" BO_ 2566801923 100;
BA_ "GenMsgStartDelayTime" BO_ 2566801923 20;
BA_ "VFrameFormat" BO_ 2566801923 3;
BA_ "GenMsgCycleTime" BO_ 2565866755 100;
BA_ "GenMsgStartDelayTime" BO_ 2565866755 15;
BA_ "VFrameFormat" BO_ 2565866755 3;
BA_ "GenMsgCycleTime" BO_ 2364539395 10;
BA_ "VFrameFormat" BO_ 2364539395 3;
BA_ "GenMsgCycleTime" BO_ 2566843904 1000;
BA_ "GenMsgStartDelayTime" BO_ 2566843904 430;
BA_ "VFrameFormat" BO_ 2566843904 3;
BA_ "GenMsgCycleTime" BO_ 2565865488 100;
BA_ "VFrameFormat" BO_ 2565865488 3;
BA_ "GenMsgCycleTime" BO_ 2565865487 100;
BA_ "GenMsgStartDelayTime" BO_ 2565865487 25;
BA_ "VFrameFormat" BO_ 2565865487 3;
BA_ "GenMsgCycleTime" BO_ 2566864640 100;
BA_ "GenMsgDelayTime" BO_ 2566864640 20;
BA_ "GenMsgStartDelayTime" BO_ 2566864640 10;
BA_ "VFrameFormat" BO_ 2566864640 3;
BA_ "GenMsgCycleTime" BO_ 2364541440 500;
BA_ "GenMsgStartDelayTime" BO_ 2364541440 25;
BA_ "VFrameFormat" BO_ 2364541440 3;
BA_ "GenMsgCycleTime" BO_ 2566844160 500;
BA_ "GenMsgStartDelayTime" BO_ 2566844160 125;
BA_ "VFrameFormat" BO_ 2566844160 3;
BA_ "GenMsgCycleTime" BO_ 2566840064 250;
BA_ "GenMsgStartDelayTime" BO_ 2566840064 20;
BA_ "VFrameFormat" BO_ 2566840064 3;
BA_ "GenMsgCycleTime" BO_ 2364539648 50;
BA_ "GenMsgStartDelayTime" BO_ 2364539648 5;
BA_ "VFrameFormat" BO_ 2364539648 3;
BA_ "GenMsgCycleTime" BO_ 2364539904 20;
BA_ "GenMsgStartDelayTime" BO_ 2364539904 5;
BA_ "VFrameFormat" BO_ 2364539904 3;
BA_ "GenMsgCycleTime" BO_ 2566841088 5000;
BA_ "GenMsgDelayTime" BO_ 2566841088 200;
BA_ "GenMsgStartDelayTime" BO_ 2566841088 140;
BA_ "VFrameFormat" BO_ 2566841088 3;
BA_ "GenMsgCycleTime" BO_ 2365554187 20;
BA_ "GenMsgStartDelayTime" BO_ 2365554187 5;
BA_ "VFrameFormat" BO_ 2365554187 3;
BA_ "GenMsgCycleTime" BO_ 2298445579 20;
BA_ "GenMsgStartDelayTime" BO_ 2298445579 15;
BA_ "VFrameFormat" BO_ 2298445579 3;
BA_ "GenMsgCycleTime" BO_ 2566852619 100;
BA_ "VFrameFormat" BO_ 2566852619 3;
BA_ "GenMsgCycleTime" BO_ 2298422539 20;
BA_ "GenMsgStartDelayTime" BO_ 2298422539 10;
BA_ "VFrameFormat" BO_ 2298422539 3;
BA_ "GenMsgCycleTime" BO_ 2298422283 20;
BA_ "GenMsgStartDelayTime" BO_ 2298422283 5;
BA_ "VFrameFormat" BO_ 2298422283 3;
BA_ "GenMsgCycleTime" BO_ 2566911243 1000;
BA_ "GenMsgStartDelayTime" BO_ 2566911243 410;
BA_ "VFrameFormat" BO_ 2566911243 3;
BA_ "GenMsgCycleTime" BO_ 2566906891 1000;
BA_ "GenMsgStartDelayTime" BO_ 2566906891 450;
BA_ "VFrameFormat" BO_ 2566906891 3;
BA_ "GenMsgCycleTime" BO_ 2566902283 1000;
BA_ "GenMsgStartDelayTime" BO_ 2566902283 380;
BA_ "VFrameFormat" BO_ 2566902283 3;
BA_ "GenSigSendType" SG_ 2348814097 TSC1EMSrVMCU_EnRTrqTrqLm 7;
BA_ "GenSigCycleTime" SG_ 2348814097 TSC1EMSrVMCU_EnRTrqTrqLm 100;
BA_ "GenSigCycleTimeActive" SG_ 2348814097 TSC1EMSrVMCU_EnRTrqTrqLm 100;
BA_ "GenSigStartValue" SG_ 2348814097 TSC1EMSrVMCU_EnRTrqTrqLm 255;
BA_ "SeToolAncestorID_SIGNAL" SG_ 2348814097 TSC1EMSrVMCU_EnRTrqTrqLm "x0000001D042564D4";
BA_ "SeToolItemID_SIGNAL" SG_ 2348814097 TSC1EMSrVMCU_EnRTrqTrqLm "x0000001D042564D4";
BA_ "SeToolName_SIGNAL" SG_ 2348814097 TSC1EMSrVMCU_EnRTrqTrqLm "EnRTrqTrqLm";
BA_ "SeToolOwnerSigGroupID_SIGNAL" SG_ 2348814097 TSC1EMSrVMCU_EnRTrqTrqLm "x0000001D043FB6F7";
BA_ "SeToolOwnerSigGroup_SIGNAL" SG_ 2348814097 TSC1EMSrVMCU_EnRTrqTrqLm "TSC1EMSrVMCU";
BA_ "SeToolVersion_SIGNAL" SG_ 2348814097 TSC1EMSrVMCU_EnRTrqTrqLm "1";
BA_ "GenSigSendType" SG_ 2348814097 TSC1EMSrVMCU_EnRSpdCtrlC 7;
BA_ "GenSigCycleTime" SG_ 2348814097 TSC1EMSrVMCU_EnRSpdCtrlC 100;
BA_ "GenSigCycleTimeActive" SG_ 2348814097 TSC1EMSrVMCU_EnRSpdCtrlC 100;
BA_ "SeToolAncestorID_SIGNAL" SG_ 2348814097 TSC1EMSrVMCU_EnRSpdCtrlC "x0000001D042564C9";
BA_ "SeToolItemID_SIGNAL" SG_ 2348814097 TSC1EMSrVMCU_EnRSpdCtrlC "x0000001D042564C9";
BA_ "SeToolName_SIGNAL" SG_ 2348814097 TSC1EMSrVMCU_EnRSpdCtrlC "EnRSpdCtrlC";
BA_ "SeToolOwnerSigGroupID_SIGNAL" SG_ 2348814097 TSC1EMSrVMCU_EnRSpdCtrlC "x0000001D043FB6F7";
BA_ "SeToolOwnerSigGroup_SIGNAL" SG_ 2348814097 TSC1EMSrVMCU_EnRSpdCtrlC "TSC1EMSrVMCU";
BA_ "SeToolVersion_SIGNAL" SG_ 2348814097 TSC1EMSrVMCU_EnRSpdCtrlC "1";
BA_ "GenSigSendType" SG_ 2348814097 TSC1EMSrVMCU_OvrdCtrlMPr 7;
BA_ "GenSigCycleTime" SG_ 2348814097 TSC1EMSrVMCU_OvrdCtrlMPr 100;
BA_ "GenSigCycleTimeActive" SG_ 2348814097 TSC1EMSrVMCU_OvrdCtrlMPr 100;
BA_ "GenSigStartValue" SG_ 2348814097 TSC1EMSrVMCU_OvrdCtrlMPr 3;
BA_ "SeToolAncestorID_SIGNAL" SG_ 2348814097 TSC1EMSrVMCU_OvrdCtrlMPr "x0000001D042564CE";
BA_ "SeToolItemID_SIGNAL" SG_ 2348814097 TSC1EMSrVMCU_OvrdCtrlMPr "x0000001D042564CE";
BA_ "SeToolName_SIGNAL" SG_ 2348814097 TSC1EMSrVMCU_OvrdCtrlMPr "OvrdCtrlMPr";
BA_ "SeToolOwnerSigGroupID_SIGNAL" SG_ 2348814097 TSC1EMSrVMCU_OvrdCtrlMPr "x0000001D043FB6F7";
BA_ "SeToolOwnerSigGroup_SIGNAL" SG_ 2348814097 TSC1EMSrVMCU_OvrdCtrlMPr "TSC1EMSrVMCU";
BA_ "SeToolVersion_SIGNAL" SG_ 2348814097 TSC1EMSrVMCU_OvrdCtrlMPr "1";
BA_ "GenSigSendType" SG_ 2348814097 TSC1EMSrVMCU_EnOvrdCtrlM 6;
BA_ "GenSigCycleTime" SG_ 2348814097 TSC1EMSrVMCU_EnOvrdCtrlM 100;
BA_ "GenSigCycleTimeActive" SG_ 2348814097 TSC1EMSrVMCU_EnOvrdCtrlM 100;
BA_ "SeToolAncestorID_SIGNAL" SG_ 2348814097 TSC1EMSrVMCU_EnOvrdCtrlM "x0000001D042564C7";
BA_ "SeToolItemID_SIGNAL" SG_ 2348814097 TSC1EMSrVMCU_EnOvrdCtrlM "x0000001D042564C7";
BA_ "SeToolName_SIGNAL" SG_ 2348814097 TSC1EMSrVMCU_EnOvrdCtrlM "EnOvrdCtrlM";
BA_ "SeToolOwnerSigGroupID_SIGNAL" SG_ 2348814097 TSC1EMSrVMCU_EnOvrdCtrlM "x0000001D043FB6F7";
BA_ "SeToolOwnerSigGroup_SIGNAL" SG_ 2348814097 TSC1EMSrVMCU_EnOvrdCtrlM "TSC1EMSrVMCU";
BA_ "SeToolVersion_SIGNAL" SG_ 2348814097 TSC1EMSrVMCU_EnOvrdCtrlM "1";
BA_ "GenSigSendType" SG_ 2348814097 TSC1EMSrVMCU_EnRSpdSpdLm 7;
BA_ "GenSigCycleTime" SG_ 2348814097 TSC1EMSrVMCU_EnRSpdSpdLm 100;
BA_ "GenSigCycleTimeActive" SG_ 2348814097 TSC1EMSrVMCU_EnRSpdSpdLm 100;
BA_ "GenSigStartValue" SG_ 2348814097 TSC1EMSrVMCU_EnRSpdSpdLm 65535;
BA_ "SeToolAncestorID_SIGNAL" SG_ 2348814097 TSC1EMSrVMCU_EnRSpdSpdLm "x0000001D042564D1";
BA_ "SeToolItemID_SIGNAL" SG_ 2348814097 TSC1EMSrVMCU_EnRSpdSpdLm "x0000001D042564D1";
BA_ "SeToolName_SIGNAL" SG_ 2348814097 TSC1EMSrVMCU_EnRSpdSpdLm "EnRSpdSpdLm";
BA_ "SeToolOwnerSigGroupID_SIGNAL" SG_ 2348814097 TSC1EMSrVMCU_EnRSpdSpdLm "x0000001D043FB6F7";
BA_ "SeToolOwnerSigGroup_SIGNAL" SG_ 2348814097 TSC1EMSrVMCU_EnRSpdSpdLm "TSC1EMSrVMCU";
BA_ "SeToolVersion_SIGNAL" SG_ 2348814097 TSC1EMSrVMCU_EnRSpdSpdLm "1";
BA_ "GenSigSendType" SG_ 2348814083 TSC1EMSrTECU_EnOvrdCtrlM 6;
BA_ "GenSigCycleTime" SG_ 2348814083 TSC1EMSrTECU_EnOvrdCtrlM 100;
BA_ "GenSigCycleTimeActive" SG_ 2348814083 TSC1EMSrTECU_EnOvrdCtrlM 100;
BA_ "SeToolAncestorID_SIGNAL" SG_ 2348814083 TSC1EMSrTECU_EnOvrdCtrlM "x0000001D042564C7";
BA_ "SeToolItemID_SIGNAL" SG_ 2348814083 TSC1EMSrTECU_EnOvrdCtrlM "x0000001D042564C7";
BA_ "SeToolName_SIGNAL" SG_ 2348814083 TSC1EMSrTECU_EnOvrdCtrlM "EnOvrdCtrlM";
BA_ "SeToolOwnerSigGroupID_SIGNAL" SG_ 2348814083 TSC1EMSrTECU_EnOvrdCtrlM "x0000001D043D766D";
BA_ "SeToolOwnerSigGroup_SIGNAL" SG_ 2348814083 TSC1EMSrTECU_EnOvrdCtrlM "TSC1_TECU_EMS_Ret";
BA_ "SeToolVersion_SIGNAL" SG_ 2348814083 TSC1EMSrTECU_EnOvrdCtrlM "1";
BA_ "GenSigSendType" SG_ 2348814083 TSC1EMSrTECU_EnRSpdCtrlC 7;
BA_ "GenSigCycleTime" SG_ 2348814083 TSC1EMSrTECU_EnRSpdCtrlC 100;
BA_ "GenSigCycleTimeActive" SG_ 2348814083 TSC1EMSrTECU_EnRSpdCtrlC 100;
BA_ "SeToolAncestorID_SIGNAL" SG_ 2348814083 TSC1EMSrTECU_EnRSpdCtrlC "x0000001D042564C9";
BA_ "SeToolItemID_SIGNAL" SG_ 2348814083 TSC1EMSrTECU_EnRSpdCtrlC "x0000001D042564C9";
BA_ "SeToolName_SIGNAL" SG_ 2348814083 TSC1EMSrTECU_EnRSpdCtrlC "EnRSpdCtrlC";
BA_ "SeToolOwnerSigGroupID_SIGNAL" SG_ 2348814083 TSC1EMSrTECU_EnRSpdCtrlC "x0000001D043D766D";
BA_ "SeToolOwnerSigGroup_SIGNAL" SG_ 2348814083 TSC1EMSrTECU_EnRSpdCtrlC "TSC1_TECU_EMS_Ret";
BA_ "SeToolVersion_SIGNAL" SG_ 2348814083 TSC1EMSrTECU_EnRSpdCtrlC "1";
BA_ "GenSigSendType" SG_ 2348814083 TSC1EMSrTECU_EnRTrqTrqLm 7;
BA_ "GenSigCycleTime" SG_ 2348814083 TSC1EMSrTECU_EnRTrqTrqLm 100;
BA_ "GenSigCycleTimeActive" SG_ 2348814083 TSC1EMSrTECU_EnRTrqTrqLm 100;
BA_ "GenSigStartValue" SG_ 2348814083 TSC1EMSrTECU_EnRTrqTrqLm 255;
BA_ "SeToolAncestorID_SIGNAL" SG_ 2348814083 TSC1EMSrTECU_EnRTrqTrqLm "x0000001D042564D4";
BA_ "SeToolItemID_SIGNAL" SG_ 2348814083 TSC1EMSrTECU_EnRTrqTrqLm "x0000001D042564D4";
BA_ "SeToolName_SIGNAL" SG_ 2348814083 TSC1EMSrTECU_EnRTrqTrqLm "EnRTrqTrqLm";
BA_ "SeToolOwnerSigGroupID_SIGNAL" SG_ 2348814083 TSC1EMSrTECU_EnRTrqTrqLm "x0000001D043D766D";
BA_ "SeToolOwnerSigGroup_SIGNAL" SG_ 2348814083 TSC1EMSrTECU_EnRTrqTrqLm "TSC1_TECU_EMS_Ret";
BA_ "SeToolVersion_SIGNAL" SG_ 2348814083 TSC1EMSrTECU_EnRTrqTrqLm "1";
BA_ "GenSigSendType" SG_ 2348814083 TSC1EMSrTECU_EnRSpdSpdLm 7;
BA_ "GenSigCycleTime" SG_ 2348814083 TSC1EMSrTECU_EnRSpdSpdLm 100;
BA_ "GenSigCycleTimeActive" SG_ 2348814083 TSC1EMSrTECU_EnRSpdSpdLm 100;
BA_ "GenSigStartValue" SG_ 2348814083 TSC1EMSrTECU_EnRSpdSpdLm 65535;
BA_ "SeToolAncestorID_SIGNAL" SG_ 2348814083 TSC1EMSrTECU_EnRSpdSpdLm "x0000001D042564D1";
BA_ "SeToolItemID_SIGNAL" SG_ 2348814083 TSC1EMSrTECU_EnRSpdSpdLm "x0000001D042564D1";
BA_ "SeToolName_SIGNAL" SG_ 2348814083 TSC1EMSrTECU_EnRSpdSpdLm "EnRSpdSpdLm";
BA_ "SeToolOwnerSigGroupID_SIGNAL" SG_ 2348814083 TSC1EMSrTECU_EnRSpdSpdLm "x0000001D043D766D";
BA_ "SeToolOwnerSigGroup_SIGNAL" SG_ 2348814083 TSC1EMSrTECU_EnRSpdSpdLm "TSC1_TECU_EMS_Ret";
BA_ "SeToolVersion_SIGNAL" SG_ 2348814083 TSC1EMSrTECU_EnRSpdSpdLm "1";
BA_ "GenSigSendType" SG_ 2348814083 TSC1EMSrTECU_OvrdCtrlMPr 7;
BA_ "GenSigCycleTime" SG_ 2348814083 TSC1EMSrTECU_OvrdCtrlMPr 100;
BA_ "GenSigCycleTimeActive" SG_ 2348814083 TSC1EMSrTECU_OvrdCtrlMPr 100;
BA_ "GenSigStartValue" SG_ 2348814083 TSC1EMSrTECU_OvrdCtrlMPr 3;
BA_ "SeToolAncestorID_SIGNAL" SG_ 2348814083 TSC1EMSrTECU_OvrdCtrlMPr "x0000001D042564CE";
BA_ "SeToolItemID_SIGNAL" SG_ 2348814083 TSC1EMSrTECU_OvrdCtrlMPr "x0000001D042564CE";
BA_ "SeToolName_SIGNAL" SG_ 2348814083 TSC1EMSrTECU_OvrdCtrlMPr "OvrdCtrlMPr";
BA_ "SeToolOwnerSigGroupID_SIGNAL" SG_ 2348814083 TSC1EMSrTECU_OvrdCtrlMPr "x0000001D043D766D";
BA_ "SeToolOwnerSigGroup_SIGNAL" SG_ 2348814083 TSC1EMSrTECU_OvrdCtrlMPr "TSC1_TECU_EMS_Ret";
BA_ "SeToolVersion_SIGNAL" SG_ 2348814083 TSC1EMSrTECU_OvrdCtrlMPr "1";
BA_ "GenSigSendType" SG_ 2348814091 TSC1EMSrABS_OvrdCtrlMPr 7;
BA_ "GenSigCycleTime" SG_ 2348814091 TSC1EMSrABS_OvrdCtrlMPr 100;
BA_ "GenSigCycleTimeActive" SG_ 2348814091 TSC1EMSrABS_OvrdCtrlMPr 100;
BA_ "GenSigStartValue" SG_ 2348814091 TSC1EMSrABS_OvrdCtrlMPr 3;
BA_ "SeToolAncestorID_SIGNAL" SG_ 2348814091 TSC1EMSrABS_OvrdCtrlMPr "x0000001D042564CE";
BA_ "SeToolItemID_SIGNAL" SG_ 2348814091 TSC1EMSrABS_OvrdCtrlMPr "x0000001D042564CE";
BA_ "SeToolName_SIGNAL" SG_ 2348814091 TSC1EMSrABS_OvrdCtrlMPr "OvrdCtrlMPr";
BA_ "SeToolOwnerSigGroupID_SIGNAL" SG_ 2348814091 TSC1EMSrABS_OvrdCtrlMPr "x0000001D043D6A13";
BA_ "SeToolOwnerSigGroup_SIGNAL" SG_ 2348814091 TSC1EMSrABS_OvrdCtrlMPr "TSC1EMSrABS";
BA_ "SeToolVersion_SIGNAL" SG_ 2348814091 TSC1EMSrABS_OvrdCtrlMPr "1";
BA_ "GenSigSendType" SG_ 2348814091 TSC1EMSrABS_EnRTrqTrqLm 7;
BA_ "GenSigCycleTime" SG_ 2348814091 TSC1EMSrABS_EnRTrqTrqLm 100;
BA_ "GenSigCycleTimeActive" SG_ 2348814091 TSC1EMSrABS_EnRTrqTrqLm 100;
BA_ "GenSigStartValue" SG_ 2348814091 TSC1EMSrABS_EnRTrqTrqLm 255;
BA_ "SeToolAncestorID_SIGNAL" SG_ 2348814091 TSC1EMSrABS_EnRTrqTrqLm "x0000001D042564D4";
BA_ "SeToolItemID_SIGNAL" SG_ 2348814091 TSC1EMSrABS_EnRTrqTrqLm "x0000001D042564D4";
BA_ "SeToolName_SIGNAL" SG_ 2348814091 TSC1EMSrABS_EnRTrqTrqLm "EnRTrqTrqLm";
BA_ "SeToolOwnerSigGroupID_SIGNAL" SG_ 2348814091 TSC1EMSrABS_EnRTrqTrqLm "x0000001D043D6A13";
BA_ "SeToolOwnerSigGroup_SIGNAL" SG_ 2348814091 TSC1EMSrABS_EnRTrqTrqLm "TSC1EMSrABS";
BA_ "SeToolVersion_SIGNAL" SG_ 2348814091 TSC1EMSrABS_EnRTrqTrqLm "1";
BA_ "GenSigSendType" SG_ 2348814091 TSC1EMSrABS_EnRSpdCtrlC 7;
BA_ "GenSigCycleTime" SG_ 2348814091 TSC1EMSrABS_EnRSpdCtrlC 100;
BA_ "GenSigCycleTimeActive" SG_ 2348814091 TSC1EMSrABS_EnRSpdCtrlC 100;
BA_ "SeToolAncestorID_SIGNAL" SG_ 2348814091 TSC1EMSrABS_EnRSpdCtrlC "x0000001D042564C9";
BA_ "SeToolItemID_SIGNAL" SG_ 2348814091 TSC1EMSrABS_EnRSpdCtrlC "x0000001D042564C9";
BA_ "SeToolName_SIGNAL" SG_ 2348814091 TSC1EMSrABS_EnRSpdCtrlC "EnRSpdCtrlC";
BA_ "SeToolOwnerSigGroupID_SIGNAL" SG_ 2348814091 TSC1EMSrABS_EnRSpdCtrlC "x0000001D043D6A13";
BA_ "SeToolOwnerSigGroup_SIGNAL" SG_ 2348814091 TSC1EMSrABS_EnRSpdCtrlC "TSC1EMSrABS";
BA_ "SeToolVersion_SIGNAL" SG_ 2348814091 TSC1EMSrABS_EnRSpdCtrlC "1";
BA_ "GenSigSendType" SG_ 2348814091 TSC1EMSrABS_EnOvrdCtrlM 6;
BA_ "GenSigCycleTime" SG_ 2348814091 TSC1EMSrABS_EnOvrdCtrlM 100;
BA_ "GenSigCycleTimeActive" SG_ 2348814091 TSC1EMSrABS_EnOvrdCtrlM 100;
BA_ "SeToolAncestorID_SIGNAL" SG_ 2348814091 TSC1EMSrABS_EnOvrdCtrlM "x0000001D042564C7";
BA_ "SeToolItemID_SIGNAL" SG_ 2348814091 TSC1EMSrABS_EnOvrdCtrlM "x0000001D042564C7";
BA_ "SeToolName_SIGNAL" SG_ 2348814091 TSC1EMSrABS_EnOvrdCtrlM "EnOvrdCtrlM";
BA_ "SeToolOwnerSigGroupID_SIGNAL" SG_ 2348814091 TSC1EMSrABS_EnOvrdCtrlM "x0000001D043D6A13";
BA_ "SeToolOwnerSigGroup_SIGNAL" SG_ 2348814091 TSC1EMSrABS_EnOvrdCtrlM "TSC1EMSrABS";
BA_ "SeToolVersion_SIGNAL" SG_ 2348814091 TSC1EMSrABS_EnOvrdCtrlM "1";
BA_ "GenSigSendType" SG_ 2348814091 TSC1EMSrABS_EnRSpdSpdLm 7;
BA_ "GenSigCycleTime" SG_ 2348814091 TSC1EMSrABS_EnRSpdSpdLm 100;
BA_ "GenSigCycleTimeActive" SG_ 2348814091 TSC1EMSrABS_EnRSpdSpdLm 100;
BA_ "GenSigStartValue" SG_ 2348814091 TSC1EMSrABS_EnRSpdSpdLm 65535;
BA_ "SeToolAncestorID_SIGNAL" SG_ 2348814091 TSC1EMSrABS_EnRSpdSpdLm "x0000001D042564D1";
BA_ "SeToolItemID_SIGNAL" SG_ 2348814091 TSC1EMSrABS_EnRSpdSpdLm "x0000001D042564D1";
BA_ "SeToolName_SIGNAL" SG_ 2348814091 TSC1EMSrABS_EnRSpdSpdLm "EnRSpdSpdLm";
BA_ "SeToolOwnerSigGroupID_SIGNAL" SG_ 2348814091 TSC1EMSrABS_EnRSpdSpdLm "x0000001D043D6A13";
BA_ "SeToolOwnerSigGroup_SIGNAL" SG_ 2348814091 TSC1EMSrABS_EnRSpdSpdLm "TSC1EMSrABS";
BA_ "SeToolVersion_SIGNAL" SG_ 2348814091 TSC1EMSrABS_EnRSpdSpdLm "1";
BA_ "GenSigCycleTime" SG_ 2566846467 TransmissionOilLevel_ISig_1 100;
BA_ "GenSigCycleTimeActive" SG_ 2566846467 TransmissionOilLevel_ISig_1 100;
BA_ "GenSigStartValue" SG_ 2566846467 TransmissionOilLevel_ISig_1 255;
BA_ "GenSigCycleTime" SG_ 2566846467 TransmissionOilTemp_ISig_1 100;
BA_ "GenSigCycleTimeActive" SG_ 2566846467 TransmissionOilTemp_ISig_1 100;
BA_ "GenSigStartValue" SG_ 2566846467 TransmissionOilTemp_ISig_1 65535;
BA_ "GenSigSendType" SG_ 2565603075 TPDT_SeqNo_TCM 7;
BA_ "GenSigSendType" SG_ 2565603088 TPDT_SeqNo_RECU 7;
BA_ "GenSigCycleTime" SG_ 2565603088 TPDT_SeqNo_RECU 100;
BA_ "GenSigCycleTimeActive" SG_ 2565603088 TPDT_SeqNo_RECU 100;
BA_ "GenSigSendType" SG_ 2565603087 TPDT_SeqNo_ECMret 7;
BA_ "GenSigSendType" SG_ 2565603072 TPDT_SeqNo_ECM 7;
BA_ "GenSigSendType" SG_ 2565603083 TPDT_SeqNo_EBS 7;
BA_ "GenSigSendType" SG_ 2565603133 TPDT_SeqNo_ACM 7;
BA_ "GenSigSendType" SG_ 2565668611 TPCM_ControlByte_TCM 7;
BA_ "GenSigSendType" SG_ 2565668624 TPCM_ControlByte_RECU 7;
BA_ "GenSigCycleTime" SG_ 2565668624 TPCM_ControlByte_RECU 100;
BA_ "GenSigCycleTimeActive" SG_ 2565668624 TPCM_ControlByte_RECU 100;
BA_ "GenSigSendType" SG_ 2565668623 TPCM_ControlByte_ECMret 7;
BA_ "GenSigSendType" SG_ 2565668608 TPCM_ControlByte_ECM 7;
BA_ "GenSigSendType" SG_ 2565668619 TPCM_ControlByte_EBS 7;
BA_ "GenSigSendType" SG_ 2565668669 TPCM_ControlByte_ACM 7;
BA_ "GenSigCycleTime" SG_ 2566882307 TransmissionGCVW 100;
BA_ "GenSigCycleTimeActive" SG_ 2566882307 TransmissionGCVW 100;
BA_ "GenSigStartValue" SG_ 2566882307 TransmissionGCVW 255;
BA_ "GenSigCycleTime" SG_ 2566882307 TransmEngineCrankEnable2_ISig_1 100;
BA_ "GenSigCycleTimeActive" SG_ 2566882307 TransmEngineCrankEnable2_ISig_1 100;
BA_ "GenSigStartValue" SG_ 2566882307 TransmEngineCrankEnable2_ISig_1 3;
BA_ "GenSigCycleTime" SG_ 2566882307 PwtFunctionalitySt 100;
BA_ "GenSigCycleTimeActive" SG_ 2566882307 PwtFunctionalitySt 100;
BA_ "GenSigStartValue" SG_ 2566882307 PwtFunctionalitySt 7;
BA_ "GenSigCycleTime" SG_ 2566882307 LowTempClutchInfo_ISig_1 100;
BA_ "GenSigCycleTimeActive" SG_ 2566882307 LowTempClutchInfo_ISig_1 100;
BA_ "GenSigStartValue" SG_ 2566882307 LowTempClutchInfo_ISig_1 3;
BA_ "GenSigCycleTime" SG_ 2566882307 PwtFunctionalitySt_FaultInfo 100;
BA_ "GenSigCycleTimeActive" SG_ 2566882307 PwtFunctionalitySt_FaultInfo 100;
BA_ "GenSigStartValue" SG_ 2566882307 PwtFunctionalitySt_FaultInfo 255;
BA_ "GenSigCycleTime" SG_ 2566882307 RawRoadInclination 100;
BA_ "GenSigCycleTimeActive" SG_ 2566882307 RawRoadInclination 100;
BA_ "GenSigStartValue" SG_ 2566882307 RawRoadInclination 255;
BA_ "GenSigCycleTime" SG_ 2566882307 PermittedHSAPressure 100;
BA_ "GenSigCycleTimeActive" SG_ 2566882307 PermittedHSAPressure 100;
BA_ "GenSigStartValue" SG_ 2566882307 PermittedHSAPressure 255;
BA_ "GenSigCycleTime" SG_ 2566841879 MinutesUTC_ISig_1 100;
BA_ "GenSigCycleTimeActive" SG_ 2566841879 MinutesUTC_ISig_1 100;
BA_ "GenSigStartValue" SG_ 2566841879 MinutesUTC_ISig_1 255;
BA_ "GenSigCycleTime" SG_ 2566841879 MonthUTC_ISig_1 100;
BA_ "GenSigCycleTimeActive" SG_ 2566841879 MonthUTC_ISig_1 100;
BA_ "GenSigStartValue" SG_ 2566841879 MonthUTC_ISig_1 255;
BA_ "GenSigCycleTime" SG_ 2566841879 YearUTC_ISig_1 100;
BA_ "GenSigCycleTimeActive" SG_ 2566841879 YearUTC_ISig_1 100;
BA_ "GenSigStartValue" SG_ 2566841879 YearUTC_ISig_1 255;
BA_ "GenSigCycleTime" SG_ 2566841879 SelectedLocalHourOffset 100;
BA_ "GenSigCycleTimeActive" SG_ 2566841879 SelectedLocalHourOffset 100;
BA_ "GenSigStartValue" SG_ 2566841879 SelectedLocalHourOffset 255;
BA_ "GenSigCycleTime" SG_ 2566841879 HoursUTC_ISig_1 100;
BA_ "GenSigCycleTimeActive" SG_ 2566841879 HoursUTC_ISig_1 100;
BA_ "GenSigStartValue" SG_ 2566841879 HoursUTC_ISig_1 255;
BA_ "GenSigCycleTime" SG_ 2566841879 DayUTC_ISig_1 100;
BA_ "GenSigCycleTimeActive" SG_ 2566841879 DayUTC_ISig_1 100;
BA_ "GenSigStartValue" SG_ 2566841879 DayUTC_ISig_1 255;
BA_ "GenSigCycleTime" SG_ 2566841879 SecondsUTC_ISig_1 100;
BA_ "GenSigCycleTimeActive" SG_ 2566841879 SecondsUTC_ISig_1 100;
BA_ "GenSigStartValue" SG_ 2566841879 SecondsUTC_ISig_1 255;
BA_ "GenSigCycleTime" SG_ 2566841879 SelectedLocalMinuteOffset 100;
BA_ "GenSigCycleTimeActive" SG_ 2566841879 SelectedLocalMinuteOffset 100;
BA_ "GenSigStartValue" SG_ 2566841879 SelectedLocalMinuteOffset 255;
BA_ "GenSigCycleTime" SG_ 2365528579 RoadInclination_ISig_1 100;
BA_ "GenSigCycleTimeActive" SG_ 2365528579 RoadInclination_ISig_1 100;
BA_ "GenSigStartValue" SG_ 2365528579 RoadInclination_ISig_1 255;
BA_ "GenSigMaxLatency" SG_ 2365528579 RoadInclination_ISig_1 25;
BA_ "GenSigCycleTime" SG_ 2365528579 TransmOutputShaftSpeedSigned 100;
BA_ "GenSigCycleTimeActive" SG_ 2365528579 TransmOutputShaftSpeedSigned 100;
BA_ "GenSigStartValue" SG_ 2365528579 TransmOutputShaftSpeedSigned 65535;
BA_ "GenSigMaxLatency" SG_ 2365528579 TransmOutputShaftSpeedSigned 25;
BA_ "GenSigCycleTime" SG_ 2499792656 DrivelineRetarderStat_ISig_1 100;
BA_ "GenSigCycleTimeActive" SG_ 2499792656 DrivelineRetarderStat_ISig_1 100;
BA_ "GenSigStartValue" SG_ 2499792656 DrivelineRetarderStat_ISig_1 3;
BA_ "GenSigSendType" SG_ 2566840592 DrivelineRetarderLocation 3;
BA_ "GenSigCycleTime" SG_ 2566840592 DrivelineRetarderLocation 100;
BA_ "GenSigCycleTimeActive" SG_ 2566840592 DrivelineRetarderLocation 100;
BA_ "GenSigStartValue" SG_ 2566840592 DrivelineRetarderLocation 15;
BA_ "GenSigSendType" SG_ 2566840592 DrivelineRetarderType 3;
BA_ "GenSigCycleTime" SG_ 2566840592 DrivelineRetarderType 100;
BA_ "GenSigCycleTimeActive" SG_ 2566840592 DrivelineRetarderType 100;
BA_ "GenSigStartValue" SG_ 2566840592 DrivelineRetarderType 15;
BA_ "GenSigSendType" SG_ 2566840592 DrivelineRetarderRefTorque 3;
BA_ "GenSigCycleTime" SG_ 2566840592 DrivelineRetarderRefTorque 100;
BA_ "GenSigCycleTimeActive" SG_ 2566840592 DrivelineRetarderRefTorque 100;
BA_ "GenSigStartValue" SG_ 2566840592 DrivelineRetarderRefTorque 65535;
BA_ "GenSigSendType" SG_ 2566840591 EngRetConf_PerTrqAtP3 3;
BA_ "GenSigCycleTime" SG_ 2566840591 EngRetConf_PerTrqAtP3 100;
BA_ "GenSigCycleTimeActive" SG_ 2566840591 EngRetConf_PerTrqAtP3 100;
BA_ "GenSigStartValue" SG_ 2566840591 EngRetConf_PerTrqAtP3 255;
BA_ "GenSigSendType" SG_ 2566840591 EngRetConf_RetSpeedAtP5 3;
BA_ "GenSigCycleTime" SG_ 2566840591 EngRetConf_RetSpeedAtP5 100;
BA_ "GenSigCycleTimeActive" SG_ 2566840591 EngRetConf_RetSpeedAtP5 100;
BA_ "GenSigStartValue" SG_ 2566840591 EngRetConf_RetSpeedAtP5 65535;
BA_ "GenSigSendType" SG_ 2566840591 EngRetConf_MaxRetSpeedP2 3;
BA_ "GenSigCycleTime" SG_ 2566840591 EngRetConf_MaxRetSpeedP2 100;
BA_ "GenSigCycleTimeActive" SG_ 2566840591 EngRetConf_MaxRetSpeedP2 100;
BA_ "GenSigStartValue" SG_ 2566840591 EngRetConf_MaxRetSpeedP2 65535;
BA_ "GenSigSendType" SG_ 2566840591 EngRetConf_RetSpeedAtP3 3;
BA_ "GenSigCycleTime" SG_ 2566840591 EngRetConf_RetSpeedAtP3 100;
BA_ "GenSigCycleTimeActive" SG_ 2566840591 EngRetConf_RetSpeedAtP3 100;
BA_ "GenSigStartValue" SG_ 2566840591 EngRetConf_RetSpeedAtP3 65535;
BA_ "GenSigSendType" SG_ 2566840591 EngRetConf_PerTrqAtP4 3;
BA_ "GenSigCycleTime" SG_ 2566840591 EngRetConf_PerTrqAtP4 100;
BA_ "GenSigCycleTimeActive" SG_ 2566840591 EngRetConf_PerTrqAtP4 100;
BA_ "GenSigStartValue" SG_ 2566840591 EngRetConf_PerTrqAtP4 255;
BA_ "GenSigSendType" SG_ 2566840591 EngRetConf_PerTrqAtP5 3;
BA_ "GenSigCycleTime" SG_ 2566840591 EngRetConf_PerTrqAtP5 100;
BA_ "GenSigCycleTimeActive" SG_ 2566840591 EngRetConf_PerTrqAtP5 100;
BA_ "GenSigStartValue" SG_ 2566840591 EngRetConf_PerTrqAtP5 255;
BA_ "GenSigSendType" SG_ 2566840591 EngRetConf_RetCtrlMethod 3;
BA_ "GenSigCycleTime" SG_ 2566840591 EngRetConf_RetCtrlMethod 100;
BA_ "GenSigCycleTimeActive" SG_ 2566840591 EngRetConf_RetCtrlMethod 100;
BA_ "GenSigStartValue" SG_ 2566840591 EngRetConf_RetCtrlMethod 255;
BA_ "GenSigSendType" SG_ 2566840591 ReferenceEngineRetarderTorque 3;
BA_ "GenSigCycleTime" SG_ 2566840591 ReferenceEngineRetarderTorque 100;
BA_ "GenSigCycleTimeActive" SG_ 2566840591 ReferenceEngineRetarderTorque 100;
BA_ "GenSigStartValue" SG_ 2566840591 ReferenceEngineRetarderTorque 65535;
BA_ "GenSigSendType" SG_ 2566840591 EngRetConf_RetSpeedAtP4 3;
BA_ "GenSigCycleTime" SG_ 2566840591 EngRetConf_RetSpeedAtP4 100;
BA_ "GenSigCycleTimeActive" SG_ 2566840591 EngRetConf_RetSpeedAtP4 100;
BA_ "GenSigStartValue" SG_ 2566840591 EngRetConf_RetSpeedAtP4 65535;
BA_ "GenSigSendType" SG_ 2566840591 EngRetConf_PerTrqAtMaxSpeedP2 3;
BA_ "GenSigCycleTime" SG_ 2566840591 EngRetConf_PerTrqAtMaxSpeedP2 100;
BA_ "GenSigCycleTimeActive" SG_ 2566840591 EngRetConf_PerTrqAtMaxSpeedP2 100;
BA_ "GenSigStartValue" SG_ 2566840591 EngRetConf_PerTrqAtMaxSpeedP2 255;
BA_ "GenSigSendType" SG_ 2566840591 EngRetConf_speedAtIdleP1 3;
BA_ "GenSigCycleTime" SG_ 2566840591 EngRetConf_speedAtIdleP1 100;
BA_ "GenSigCycleTimeActive" SG_ 2566840591 EngRetConf_speedAtIdleP1 100;
BA_ "GenSigStartValue" SG_ 2566840591 EngRetConf_speedAtIdleP1 65535;
BA_ "GenSigSendType" SG_ 2566840591 EngRetConf_PerTrqAtIdleP1 3;
BA_ "GenSigCycleTime" SG_ 2566840591 EngRetConf_PerTrqAtIdleP1 100;
BA_ "GenSigCycleTimeActive" SG_ 2566840591 EngRetConf_PerTrqAtIdleP1 100;
BA_ "GenSigStartValue" SG_ 2566840591 EngRetConf_PerTrqAtIdleP1 255;
BA_ "GenSigSendType" SG_ 2671833640 PhysDiagRespSig_F2_28_ISig_1 7;
BA_ "GenSigSendType" SG_ 2671833617 PhysDiagRespSig_F2_11_ISig_1 7;
BA_ "GenSigSendType" SG_ 2671833361 PhysDiagRespSig_F1_11_ISig_1 7;
BA_ "GenSigSendType" SG_ 2671782130 PhysDiagReqSig_28_F2_ISig_1 7;
BA_ "GenSigSendType" SG_ 2671776242 PhysDiagReqSig_11_F2_ISig_1 7;
BA_ "GenSigSendType" SG_ 2671776241 PhysDiagReqSig_11_F1_ISig_1 7;
BA_ "GenSigCycleTime" SG_ 2566759457 Pto1EnableSwitch 100;
BA_ "GenSigCycleTimeActive" SG_ 2566759457 Pto1EnableSwitch 100;
BA_ "GenSigStartValue" SG_ 2566759457 Pto1EnableSwitch 3;
BA_ "GenSigCycleTime" SG_ 2566759457 Pto2EnableSwitch 100;
BA_ "GenSigCycleTimeActive" SG_ 2566759457 Pto2EnableSwitch 100;
BA_ "GenSigStartValue" SG_ 2566759457 Pto2EnableSwitch 3;
BA_ "GenSigCycleTime" SG_ 2566759427 Pto2EngagementConsent 100;
BA_ "GenSigCycleTimeActive" SG_ 2566759427 Pto2EngagementConsent 100;
BA_ "GenSigStartValue" SG_ 2566759427 Pto2EngagementConsent 3;
BA_ "GenSigCycleTime" SG_ 2566759427 Pto1EngagementConsent 100;
BA_ "GenSigCycleTimeActive" SG_ 2566759427 Pto1EngagementConsent 100;
BA_ "GenSigStartValue" SG_ 2566759427 Pto1EngagementConsent 3;
BA_ "GenSigSendType" SG_ 2671850481 FuncDiagDataOBD_ISig_1 7;
BA_ "GenSigCycleTime" SG_ 2566844928 InstantaneousFuelEconomy 100;
BA_ "GenSigCycleTimeActive" SG_ 2566844928 InstantaneousFuelEconomy 100;
BA_ "GenSigStartValue" SG_ 2566844928 InstantaneousFuelEconomy 65535;
BA_ "GenSigCycleTime" SG_ 2566844928 EngineFuelRate_ISig_1 100;
BA_ "GenSigCycleTimeActive" SG_ 2566844928 EngineFuelRate_ISig_1 100;
BA_ "GenSigStartValue" SG_ 2566844928 EngineFuelRate_ISig_1 65535;
BA_ "GenSigCycleTime" SG_ 2566825472 EngineTurbo1BoostPressure_ISig_1 100;
BA_ "GenSigCycleTimeActive" SG_ 2566825472 EngineTurbo1BoostPressure_ISig_1 100;
BA_ "GenSigStartValue" SG_ 2566825472 EngineTurbo1BoostPressure_ISig_1 65535;
BA_ "GenSigCycleTime" SG_ 2298372875 RearAxleLeftWheelSpeed_ISig_1 100;
BA_ "GenSigCycleTimeActive" SG_ 2298372875 RearAxleLeftWheelSpeed_ISig_1 100;
BA_ "GenSigStartValue" SG_ 2298372875 RearAxleLeftWheelSpeed_ISig_1 65535;
BA_ "GenSigCycleTime" SG_ 2298372875 FrontAxleLeftWheelSpeed_ISig_1 100;
BA_ "GenSigCycleTimeActive" SG_ 2298372875 FrontAxleLeftWheelSpeed_ISig_1 100;
BA_ "GenSigStartValue" SG_ 2298372875 FrontAxleLeftWheelSpeed_ISig_1 65535;
BA_ "GenSigCycleTime" SG_ 2298372875 FrontAxleRightWheelSpeed_ISig_1 100;
BA_ "GenSigCycleTimeActive" SG_ 2298372875 FrontAxleRightWheelSpeed_ISig_1 100;
BA_ "GenSigStartValue" SG_ 2298372875 FrontAxleRightWheelSpeed_ISig_1 65535;
BA_ "GenSigCycleTime" SG_ 2298372875 RearAxleRightWheelSpeed_ISig_1 100;
BA_ "GenSigCycleTimeActive" SG_ 2298372875 RearAxleRightWheelSpeed_ISig_1 100;
BA_ "GenSigStartValue" SG_ 2298372875 RearAxleRightWheelSpeed_ISig_1 65535;
BA_ "GenSigCycleTime" SG_ 2566719744 HighResEngineTotalFuelUsed 100;
BA_ "GenSigCycleTimeActive" SG_ 2566719744 HighResEngineTotalFuelUsed 100;
BA_ "GenSigStartValue" SG_ 2566719744 HighResEngineTotalFuelUsed 4294967295;
BA_ "GenSigCycleTime" SG_ 2566841600 EngineRevolutions 100;
BA_ "GenSigCycleTimeActive" SG_ 2566841600 EngineRevolutions 100;
BA_ "GenSigStartValue" SG_ 2566841600 EngineRevolutions 4294967295;
BA_ "GenSigCycleTime" SG_ 2566801923 TransmEngineCrankEnable_ISig_1 100;
BA_ "GenSigCycleTimeActive" SG_ 2566801923 TransmEngineCrankEnable_ISig_1 100;
BA_ "GenSigStartValue" SG_ 2566801923 TransmEngineCrankEnable_ISig_1 3;
BA_ "GenSigCycleTime" SG_ 2565866755 TransmissionRangeSelected_ISig_1 100;
BA_ "GenSigCycleTimeActive" SG_ 2565866755 TransmissionRangeSelected_ISig_1 100;
BA_ "GenSigCycleTime" SG_ 2565866755 TransmissionSelectedGear_ISig_1 100;
BA_ "GenSigCycleTimeActive" SG_ 2565866755 TransmissionSelectedGear_ISig_1 100;
BA_ "GenSigStartValue" SG_ 2565866755 TransmissionSelectedGear_ISig_1 255;
BA_ "GenSigCycleTime" SG_ 2565866755 TransmissionCurrentGear_ISig_1 100;
BA_ "GenSigCycleTimeActive" SG_ 2565866755 TransmissionCurrentGear_ISig_1 100;
BA_ "GenSigStartValue" SG_ 2565866755 TransmissionCurrentGear_ISig_1 255;
BA_ "GenSigCycleTime" SG_ 2565866755 TransmissionActualGearRatio_ISig 100;
BA_ "GenSigCycleTimeActive" SG_ 2565866755 TransmissionActualGearRatio_ISig 100;
BA_ "GenSigStartValue" SG_ 2565866755 TransmissionActualGearRatio_ISig 65535;
BA_ "SystemSignalLongSymbol" SG_ 2565866755 TransmissionActualGearRatio_ISig "TransmissionActualGearRatio_ISig_1";
BA_ "GenSigCycleTime" SG_ 2565866755 TransmissionRangeAttained_ISig_1 100;
BA_ "GenSigCycleTimeActive" SG_ 2565866755 TransmissionRangeAttained_ISig_1 100;
BA_ "GenSigCycleTime" SG_ 2364539395 TransmissionShiftInProcess 100;
BA_ "GenSigCycleTimeActive" SG_ 2364539395 TransmissionShiftInProcess 100;
BA_ "GenSigStartValue" SG_ 2364539395 TransmissionShiftInProcess 3;
BA_ "GenSigCycleTime" SG_ 2364539395 TransmissionOutputShaftSpeed2 100;
BA_ "GenSigCycleTimeActive" SG_ 2364539395 TransmissionOutputShaftSpeed2 100;
BA_ "GenSigStartValue" SG_ 2364539395 TransmissionOutputShaftSpeed2 65535;
BA_ "GenSigCycleTime" SG_ 2364539395 TransmissionInputShaftSpeed 100;
BA_ "GenSigCycleTimeActive" SG_ 2364539395 TransmissionInputShaftSpeed 100;
BA_ "GenSigStartValue" SG_ 2364539395 TransmissionInputShaftSpeed 65535;
BA_ "GenSigCycleTime" SG_ 2364539395 TransmissionDrivelineEngaged_ISi 100;
BA_ "GenSigCycleTimeActive" SG_ 2364539395 TransmissionDrivelineEngaged_ISi 100;
BA_ "GenSigStartValue" SG_ 2364539395 TransmissionDrivelineEngaged_ISi 3;
BA_ "SystemSignalLongSymbol" SG_ 2364539395 TransmissionDrivelineEngaged_ISi "TransmissionDrivelineEngaged_ISig_1";
BA_ "GenSigCycleTime" SG_ 2364539395 MomentaryEngineOverspeedEnable 100;
BA_ "GenSigCycleTimeActive" SG_ 2364539395 MomentaryEngineOverspeedEnable 100;
BA_ "GenSigStartValue" SG_ 2364539395 MomentaryEngineOverspeedEnable 3;
BA_ "GenSigCycleTime" SG_ 2364539395 PercentClutchSlip 100;
BA_ "GenSigCycleTimeActive" SG_ 2364539395 PercentClutchSlip 100;
BA_ "GenSigStartValue" SG_ 2364539395 PercentClutchSlip 255;
BA_ "GenSigCycleTime" SG_ 2364539395 TransmTrqConvrtrLockupEngd 100;
BA_ "GenSigCycleTimeActive" SG_ 2364539395 TransmTrqConvrtrLockupEngd 100;
BA_ "GenSigStartValue" SG_ 2364539395 TransmTrqConvrtrLockupEngd 3;
BA_ "GenSigCycleTime" SG_ 2566843904 EngineCoolantTemp_stat_ISig_1 100;
BA_ "GenSigCycleTimeActive" SG_ 2566843904 EngineCoolantTemp_stat_ISig_1 100;
BA_ "GenSigStartValue" SG_ 2566843904 EngineCoolantTemp_stat_ISig_1 255;
BA_ "GenSigCycleTime" SG_ 2566843904 EngineOilTemperature 100;
BA_ "GenSigCycleTimeActive" SG_ 2566843904 EngineOilTemperature 100;
BA_ "GenSigStartValue" SG_ 2566843904 EngineOilTemperature 65535;
BA_ "GenSigCycleTime" SG_ 2565865488 ActualMaxAvailDrvlnRetPrctTrq 100;
BA_ "GenSigCycleTimeActive" SG_ 2565865488 ActualMaxAvailDrvlnRetPrctTrq 100;
BA_ "GenSigStartValue" SG_ 2565865488 ActualMaxAvailDrvlnRetPrctTrq 255;
BA_ "GenSigCycleTime" SG_ 2565865488 RetarderTorqueMode 100;
BA_ "GenSigCycleTimeActive" SG_ 2565865488 RetarderTorqueMode 100;
BA_ "GenSigStartValue" SG_ 2565865488 RetarderTorqueMode 15;
BA_ "GenSigCycleTime" SG_ 2565865488 ActualDrvlnRetdrPercentTorque_IS 100;
BA_ "GenSigCycleTimeActive" SG_ 2565865488 ActualDrvlnRetdrPercentTorque_IS 100;
BA_ "GenSigStartValue" SG_ 2565865488 ActualDrvlnRetdrPercentTorque_IS 255;
BA_ "SystemSignalLongSymbol" SG_ 2565865488 ActualDrvlnRetdrPercentTorque_IS "ActualDrvlnRetdrPercentTorque_ISig_1";
BA_ "GenSigCycleTime" SG_ 2565865488 EngineCoolantLoadIncrease 100;
BA_ "GenSigCycleTimeActive" SG_ 2565865488 EngineCoolantLoadIncrease 100;
BA_ "GenSigStartValue" SG_ 2565865488 EngineCoolantLoadIncrease 3;
BA_ "GenSigCycleTime" SG_ 2565865487 ActlMaxAvailEngRetdrPercentTrq 100;
BA_ "GenSigCycleTimeActive" SG_ 2565865487 ActlMaxAvailEngRetdrPercentTrq 100;
BA_ "GenSigStartValue" SG_ 2565865487 ActlMaxAvailEngRetdrPercentTrq 255;
BA_ "GenSigCycleTime" SG_ 2565865487 EngRetdrEnableBrakeAssistSw 100;
BA_ "GenSigCycleTimeActive" SG_ 2565865487 EngRetdrEnableBrakeAssistSw 100;
BA_ "GenSigStartValue" SG_ 2565865487 EngRetdrEnableBrakeAssistSw 3;
BA_ "GenSigCycleTime" SG_ 2565865487 EngineRetarderTorqueMode 100;
BA_ "GenSigCycleTimeActive" SG_ 2565865487 EngineRetarderTorqueMode 100;
BA_ "GenSigStartValue" SG_ 2565865487 EngineRetarderTorqueMode 15;
BA_ "GenSigCycleTime" SG_ 2565865487 ActualEngineRetarderPercentTrq_I 100;
BA_ "GenSigCycleTimeActive" SG_ 2565865487 ActualEngineRetarderPercentTrq_I 100;
BA_ "GenSigStartValue" SG_ 2565865487 ActualEngineRetarderPercentTrq_I 255;
BA_ "SystemSignalLongSymbol" SG_ 2565865487 ActualEngineRetarderPercentTrq_I "ActualEngineRetarderPercentTrq_ISig_1";
BA_ "GenSigCycleTime" SG_ 2565865487 RetarderEnableShiftAssistSw 100;
BA_ "GenSigCycleTimeActive" SG_ 2565865487 RetarderEnableShiftAssistSw 100;
BA_ "GenSigStartValue" SG_ 2565865487 RetarderEnableShiftAssistSw 3;
BA_ "GenSigSendType" SG_ 2566864640 EngineActiveStatus_ISig_1 3;
BA_ "GenSigCycleTime" SG_ 2566864640 EngineActiveStatus_ISig_1 100;
BA_ "GenSigCycleTimeActive" SG_ 2566864640 EngineActiveStatus_ISig_1 100;
BA_ "GenSigStartValue" SG_ 2566864640 EngineActiveStatus_ISig_1 15;
BA_ "GenSigMaxLatency" SG_ 2566864640 EngineActiveStatus_ISig_1 30;
BA_ "GenSigCycleTime" SG_ 2566864640 DrvrDemandEngRetdrPercentTrq 100;
BA_ "GenSigCycleTimeActive" SG_ 2566864640 DrvrDemandEngRetdrPercentTrq 100;
BA_ "GenSigStartValue" SG_ 2566864640 DrvrDemandEngRetdrPercentTrq 255;
BA_ "GenSigMaxLatency" SG_ 2566864640 DrvrDemandEngRetdrPercentTrq 100;
BA_ "GenSigCycleTime" SG_ 2364541440 EngineIntakeAirRate 100;
BA_ "GenSigCycleTimeActive" SG_ 2364541440 EngineIntakeAirRate 100;
BA_ "GenSigStartValue" SG_ 2364541440 EngineIntakeAirRate 65535;
BA_ "GenSigCycleTime" SG_ 2566844160 EngineOilPressure 100;
BA_ "GenSigCycleTimeActive" SG_ 2566844160 EngineOilPressure 100;
BA_ "GenSigStartValue" SG_ 2566844160 EngineOilPressure 255;
BA_ "GenSigCycleTime" SG_ 2566844160 EngineOilLevel 100;
BA_ "GenSigCycleTimeActive" SG_ 2566844160 EngineOilLevel 100;
BA_ "GenSigStartValue" SG_ 2566844160 EngineOilLevel 255;
BA_ "GenSigCycleTime" SG_ 2566840064 NominalFrictionPercentTorque_ISi 100;
BA_ "GenSigCycleTimeActive" SG_ 2566840064 NominalFrictionPercentTorque_ISi 100;
BA_ "GenSigStartValue" SG_ 2566840064 NominalFrictionPercentTorque_ISi 255;
BA_ "SystemSignalLongSymbol" SG_ 2566840064 NominalFrictionPercentTorque_ISi "NominalFrictionPercentTorque_ISig_1";
BA_ "GenSigCycleTime" SG_ 2364539648 RoadSpeedLimitStatus 100;
BA_ "GenSigCycleTimeActive" SG_ 2364539648 RoadSpeedLimitStatus 100;
BA_ "GenSigStartValue" SG_ 2364539648 RoadSpeedLimitStatus 3;
BA_ "GenSigCycleTime" SG_ 2364539648 AcceleratorPedalPosition1_2 100;
BA_ "GenSigCycleTimeActive" SG_ 2364539648 AcceleratorPedalPosition1_2 100;
BA_ "GenSigStartValue" SG_ 2364539648 AcceleratorPedalPosition1_2 255;
BA_ "GenSigCycleTime" SG_ 2364539648 EnginePercentLoadAtCurrentSpd 100;
BA_ "GenSigCycleTimeActive" SG_ 2364539648 EnginePercentLoadAtCurrentSpd 100;
BA_ "GenSigStartValue" SG_ 2364539648 EnginePercentLoadAtCurrentSpd 255;
BA_ "GenSigCycleTime" SG_ 2364539904 EngineSpeed_ISig_1 100;
BA_ "GenSigCycleTimeActive" SG_ 2364539904 EngineSpeed_ISig_1 100;
BA_ "GenSigStartValue" SG_ 2364539904 EngineSpeed_ISig_1 65535;
BA_ "GenSigCycleTime" SG_ 2364539904 DrvrDemandEngPercentTorque 100;
BA_ "GenSigCycleTimeActive" SG_ 2364539904 DrvrDemandEngPercentTorque 100;
BA_ "GenSigStartValue" SG_ 2364539904 DrvrDemandEngPercentTorque 255;
BA_ "GenSigCycleTime" SG_ 2364539904 ActualEnginePercentTorque_ISig_1 100;
BA_ "GenSigCycleTimeActive" SG_ 2364539904 ActualEnginePercentTorque_ISig_1 100;
BA_ "GenSigStartValue" SG_ 2364539904 ActualEnginePercentTorque_ISig_1 255;
BA_ "GenSigCycleTime" SG_ 2364539904 EngineStarterMode_ISig_1 100;
BA_ "GenSigCycleTimeActive" SG_ 2364539904 EngineStarterMode_ISig_1 100;
BA_ "GenSigStartValue" SG_ 2364539904 EngineStarterMode_ISig_1 15;
BA_ "GenSigCycleTime" SG_ 2364539904 EngineTorqueMode 100;
BA_ "GenSigCycleTimeActive" SG_ 2364539904 EngineTorqueMode 100;
BA_ "GenSigStartValue" SG_ 2364539904 EngineTorqueMode 15;
BA_ "GenSigCycleTime" SG_ 2364539904 EngineDemandPercentTorque 100;
BA_ "GenSigCycleTimeActive" SG_ 2364539904 EngineDemandPercentTorque 100;
BA_ "GenSigStartValue" SG_ 2364539904 EngineDemandPercentTorque 255;
BA_ "GenSigSendType" SG_ 2566841088 EngConf_EngSpeedAt_P3 3;
BA_ "GenSigCycleTime" SG_ 2566841088 EngConf_EngSpeedAt_P3 100;
BA_ "GenSigCycleTimeActive" SG_ 2566841088 EngConf_EngSpeedAt_P3 100;
BA_ "GenSigStartValue" SG_ 2566841088 EngConf_EngSpeedAt_P3 65535;
BA_ "GenSigSendType" SG_ 2566841088 EngConf_EngSpeedAtIdle_P1 3;
BA_ "GenSigCycleTime" SG_ 2566841088 EngConf_EngSpeedAtIdle_P1 100;
BA_ "GenSigCycleTimeActive" SG_ 2566841088 EngConf_EngSpeedAtIdle_P1 100;
BA_ "GenSigStartValue" SG_ 2566841088 EngConf_EngSpeedAtIdle_P1 65535;
BA_ "GenSigSendType" SG_ 2566841088 EngConf_EngTorqueAtIdle_P1 3;
BA_ "GenSigCycleTime" SG_ 2566841088 EngConf_EngTorqueAtIdle_P1 100;
BA_ "GenSigCycleTimeActive" SG_ 2566841088 EngConf_EngTorqueAtIdle_P1 100;
BA_ "GenSigStartValue" SG_ 2566841088 EngConf_EngTorqueAtIdle_P1 255;
BA_ "GenSigSendType" SG_ 2566841088 EngConf_EngSpeedAt_P4 3;
BA_ "GenSigCycleTime" SG_ 2566841088 EngConf_EngSpeedAt_P4 100;
BA_ "GenSigCycleTimeActive" SG_ 2566841088 EngConf_EngSpeedAt_P4 100;
BA_ "GenSigStartValue" SG_ 2566841088 EngConf_EngSpeedAt_P4 65535;
BA_ "GenSigSendType" SG_ 2566841088 EngineReferenceTorque_ISig_1 3;
BA_ "GenSigCycleTime" SG_ 2566841088 EngineReferenceTorque_ISig_1 100;
BA_ "GenSigCycleTimeActive" SG_ 2566841088 EngineReferenceTorque_ISig_1 100;
BA_ "GenSigStartValue" SG_ 2566841088 EngineReferenceTorque_ISig_1 65535;
BA_ "GenSigSendType" SG_ 2566841088 EngConf_EngTorqueAt_P5 3;
BA_ "GenSigCycleTime" SG_ 2566841088 EngConf_EngTorqueAt_P5 100;
BA_ "GenSigCycleTimeActive" SG_ 2566841088 EngConf_EngTorqueAt_P5 100;
BA_ "GenSigStartValue" SG_ 2566841088 EngConf_EngTorqueAt_P5 255;
BA_ "GenSigSendType" SG_ 2566841088 EngConf_EngSpeedAtHighIdle_P6 3;
BA_ "GenSigCycleTime" SG_ 2566841088 EngConf_EngSpeedAtHighIdle_P6 100;
BA_ "GenSigCycleTimeActive" SG_ 2566841088 EngConf_EngSpeedAtHighIdle_P6 100;
BA_ "GenSigStartValue" SG_ 2566841088 EngConf_EngSpeedAtHighIdle_P6 65535;
BA_ "GenSigSendType" SG_ 2566841088 EngConf_EngTorqueAt_P3 3;
BA_ "GenSigCycleTime" SG_ 2566841088 EngConf_EngTorqueAt_P3 100;
BA_ "GenSigCycleTimeActive" SG_ 2566841088 EngConf_EngTorqueAt_P3 100;
BA_ "GenSigStartValue" SG_ 2566841088 EngConf_EngTorqueAt_P3 255;
BA_ "GenSigSendType" SG_ 2566841088 EngConf_EngSpeedAt_P5 3;
BA_ "GenSigCycleTime" SG_ 2566841088 EngConf_EngSpeedAt_P5 100;
BA_ "GenSigCycleTimeActive" SG_ 2566841088 EngConf_EngSpeedAt_P5 100;
BA_ "GenSigStartValue" SG_ 2566841088 EngConf_EngSpeedAt_P5 65535;
BA_ "GenSigSendType" SG_ 2566841088 EngConf_EngMaxMomOvSpeed_P7 3;
BA_ "GenSigCycleTime" SG_ 2566841088 EngConf_EngMaxMomOvSpeed_P7 100;
BA_ "GenSigCycleTimeActive" SG_ 2566841088 EngConf_EngMaxMomOvSpeed_P7 100;
BA_ "GenSigStartValue" SG_ 2566841088 EngConf_EngMaxMomOvSpeed_P7 65535;
BA_ "GenSigSendType" SG_ 2566841088 EngConf_EngTorqueAt_P4 3;
BA_ "GenSigCycleTime" SG_ 2566841088 EngConf_EngTorqueAt_P4 100;
BA_ "GenSigCycleTimeActive" SG_ 2566841088 EngConf_EngTorqueAt_P4 100;
BA_ "GenSigStartValue" SG_ 2566841088 EngConf_EngTorqueAt_P4 255;
BA_ "GenSigSendType" SG_ 2566841088 EngConf_EngTorqueAt_P2 3;
BA_ "GenSigCycleTime" SG_ 2566841088 EngConf_EngTorqueAt_P2 100;
BA_ "GenSigCycleTimeActive" SG_ 2566841088 EngConf_EngTorqueAt_P2 100;
BA_ "GenSigStartValue" SG_ 2566841088 EngConf_EngTorqueAt_P2 255;
BA_ "GenSigSendType" SG_ 2566841088 EngConf_EngSpeedAt_P2 3;
BA_ "GenSigCycleTime" SG_ 2566841088 EngConf_EngSpeedAt_P2 100;
BA_ "GenSigCycleTimeActive" SG_ 2566841088 EngConf_EngSpeedAt_P2 100;
BA_ "GenSigStartValue" SG_ 2566841088 EngConf_EngSpeedAt_P2 65535;
BA_ "GenSigSendType" SG_ 2566841088 EngConf_MaxMomOverrideTimeLim 3;
BA_ "GenSigCycleTime" SG_ 2566841088 EngConf_MaxMomOverrideTimeLim 100;
BA_ "GenSigCycleTimeActive" SG_ 2566841088 EngConf_MaxMomOverrideTimeLim 100;
BA_ "GenSigStartValue" SG_ 2566841088 EngConf_MaxMomOverrideTimeLim 255;
BA_ "GenSigCycleTime" SG_ 2365554187 TagAxleLeftWheelSpeed 100;
BA_ "GenSigCycleTimeActive" SG_ 2365554187 TagAxleLeftWheelSpeed 100;
BA_ "GenSigStartValue" SG_ 2365554187 TagAxleLeftWheelSpeed 65535;
BA_ "GenSigCycleTime" SG_ 2365554187 PusherAxleLeftWheelSpeed 100;
BA_ "GenSigCycleTimeActive" SG_ 2365554187 PusherAxleLeftWheelSpeed 100;
BA_ "GenSigStartValue" SG_ 2365554187 PusherAxleLeftWheelSpeed 65535;
BA_ "GenSigCycleTime" SG_ 2365554187 PusherAxleRightWheelSpeed 100;
BA_ "GenSigCycleTimeActive" SG_ 2365554187 PusherAxleRightWheelSpeed 100;
BA_ "GenSigStartValue" SG_ 2365554187 PusherAxleRightWheelSpeed 65535;
BA_ "GenSigCycleTime" SG_ 2365554187 TagAxleRightWheelSpeed 100;
BA_ "GenSigCycleTimeActive" SG_ 2365554187 TagAxleRightWheelSpeed 100;
BA_ "GenSigStartValue" SG_ 2365554187 TagAxleRightWheelSpeed 65535;
BA_ "GenSigCycleTime" SG_ 2298445579 ThrdRrDriveAxLeftWheelSpeed_ISig 100;
BA_ "GenSigCycleTimeActive" SG_ 2298445579 ThrdRrDriveAxLeftWheelSpeed_ISig 100;
BA_ "GenSigStartValue" SG_ 2298445579 ThrdRrDriveAxLeftWheelSpeed_ISig 65535;
BA_ "SystemSignalLongSymbol" SG_ 2298445579 ThrdRrDriveAxLeftWheelSpeed_ISig "ThrdRrDriveAxLeftWheelSpeed_ISig_1";
BA_ "GenSigCycleTime" SG_ 2298445579 ThrdRrDriveAxRightWheelSpeed_ISi 100;
BA_ "GenSigCycleTimeActive" SG_ 2298445579 ThrdRrDriveAxRightWheelSpeed_ISi 100;
BA_ "GenSigStartValue" SG_ 2298445579 ThrdRrDriveAxRightWheelSpeed_ISi 65535;
BA_ "SystemSignalLongSymbol" SG_ 2298445579 ThrdRrDriveAxRightWheelSpeed_ISi "ThrdRrDriveAxRightWheelSpeed_ISig_1";
BA_ "GenSigCycleTime" SG_ 2566852619 WheelCircumference_TireId 100;
BA_ "GenSigCycleTimeActive" SG_ 2566852619 WheelCircumference_TireId 100;
BA_ "GenSigStartValue" SG_ 2566852619 WheelCircumference_TireId 255;
BA_ "GenSigCycleTime" SG_ 2566852619 WheelCircumference_Value 100;
BA_ "GenSigCycleTimeActive" SG_ 2566852619 WheelCircumference_Value 100;
BA_ "GenSigStartValue" SG_ 2566852619 WheelCircumference_Value 255;
BA_ "GenSigCycleTime" SG_ 2298422539 ActualPusherWheelAngle 100;
BA_ "GenSigCycleTimeActive" SG_ 2298422539 ActualPusherWheelAngle 100;
BA_ "GenSigStartValue" SG_ 2298422539 ActualPusherWheelAngle 65535;
BA_ "GenSigCycleTime" SG_ 2298422539 ActualTagWheelAngle 100;
BA_ "GenSigCycleTimeActive" SG_ 2298422539 ActualTagWheelAngle 100;
BA_ "GenSigStartValue" SG_ 2298422539 ActualTagWheelAngle 65535;
BA_ "GenSigCycleTime" SG_ 2298422283 ScndFrAxleLeftWheelSpeed 100;
BA_ "GenSigCycleTimeActive" SG_ 2298422283 ScndFrAxleLeftWheelSpeed 100;
BA_ "GenSigStartValue" SG_ 2298422283 ScndFrAxleLeftWheelSpeed 65535;
BA_ "GenSigCycleTime" SG_ 2298422283 ScndRrDriveAxleRightWheelSpeed_I 100;
BA_ "GenSigCycleTimeActive" SG_ 2298422283 ScndRrDriveAxleRightWheelSpeed_I 100;
BA_ "GenSigStartValue" SG_ 2298422283 ScndRrDriveAxleRightWheelSpeed_I 65535;
BA_ "SystemSignalLongSymbol" SG_ 2298422283 ScndRrDriveAxleRightWheelSpeed_I "ScndRrDriveAxleRightWheelSpeed_ISig_1";
BA_ "GenSigCycleTime" SG_ 2298422283 ScndFrAxleRightWheelSpeed 100;
BA_ "GenSigCycleTimeActive" SG_ 2298422283 ScndFrAxleRightWheelSpeed 100;
BA_ "GenSigStartValue" SG_ 2298422283 ScndFrAxleRightWheelSpeed 65535;
BA_ "GenSigCycleTime" SG_ 2298422283 ScndRrDriveAxleLeftWheelSpeed_IS 100;
BA_ "GenSigCycleTimeActive" SG_ 2298422283 ScndRrDriveAxleLeftWheelSpeed_IS 100;
BA_ "GenSigStartValue" SG_ 2298422283 ScndRrDriveAxleLeftWheelSpeed_IS 65535;
BA_ "SystemSignalLongSymbol" SG_ 2298422283 ScndRrDriveAxleLeftWheelSpeed_IS "ScndRrDriveAxleLeftWheelSpeed_ISig_1";
BA_ "GenSigCycleTime" SG_ 2566911243 Trailer5EBSRedWarning 100;
BA_ "GenSigCycleTimeActive" SG_ 2566911243 Trailer5EBSRedWarning 100;
BA_ "GenSigStartValue" SG_ 2566911243 Trailer5EBSRedWarning 3;
BA_ "GenSigCycleTime" SG_ 2566911243 Trailer5ExtLvlStorageSupport 100;
BA_ "GenSigCycleTimeActive" SG_ 2566911243 Trailer5ExtLvlStorageSupport 100;
BA_ "GenSigStartValue" SG_ 2566911243 Trailer5ExtLvlStorageSupport 3;
BA_ "GenSigCycleTime" SG_ 2566911243 Trailer5PneumSupply_Pressure 100;
BA_ "GenSigCycleTimeActive" SG_ 2566911243 Trailer5PneumSupply_Pressure 100;
BA_ "GenSigStartValue" SG_ 2566911243 Trailer5PneumSupply_Pressure 255;
BA_ "GenSigCycleTime" SG_ 2566911243 Trailer5NomBodyLevel_FrontLevel 100;
BA_ "GenSigCycleTimeActive" SG_ 2566911243 Trailer5NomBodyLevel_FrontLevel 100;
BA_ "GenSigStartValue" SG_ 2566911243 Trailer5NomBodyLevel_FrontLevel 65535;
BA_ "GenSigCycleTime" SG_ 2566911243 Trailer5LoadRampApprAssistStat 100;
BA_ "GenSigCycleTimeActive" SG_ 2566911243 Trailer5LoadRampApprAssistStat 100;
BA_ "GenSigStartValue" SG_ 2566911243 Trailer5LoadRampApprAssistStat 3;
BA_ "GenSigMaxLatency" SG_ 2566911243 Trailer5LoadRampApprAssistStat 1150;
BA_ "Platform_VMCU1_Sig" SG_ 2566911243 Trailer5LoadRampApprAssistStat 1;
BA_ "GenSigCycleTime" SG_ 2566911243 Trailer5VehicleType 100;
BA_ "GenSigCycleTimeActive" SG_ 2566911243 Trailer5VehicleType 100;
BA_ "GenSigStartValue" SG_ 2566911243 Trailer5VehicleType 3;
BA_ "GenSigCycleTime" SG_ 2566911243 Trailer5EBSAmberWarning 100;
BA_ "GenSigCycleTimeActive" SG_ 2566911243 Trailer5EBSAmberWarning 100;
BA_ "GenSigStartValue" SG_ 2566911243 Trailer5EBSAmberWarning 3;
BA_ "GenSigCycleTime" SG_ 2566911243 Trailer5LevelControlStatus 100;
BA_ "GenSigCycleTimeActive" SG_ 2566911243 Trailer5LevelControlStatus 100;
BA_ "GenSigStartValue" SG_ 2566911243 Trailer5LevelControlStatus 3;
BA_ "GenSigCycleTime" SG_ 2566911243 Trailer5PneumSupply_Status 100;
BA_ "GenSigCycleTimeActive" SG_ 2566911243 Trailer5PneumSupply_Status 100;
BA_ "GenSigStartValue" SG_ 2566911243 Trailer5PneumSupply_Status 3;
BA_ "GenSigCycleTime" SG_ 2566911243 Trailer5ROPSystemStatus 100;
BA_ "GenSigCycleTimeActive" SG_ 2566911243 Trailer5ROPSystemStatus 100;
BA_ "GenSigStartValue" SG_ 2566911243 Trailer5ROPSystemStatus 3;
BA_ "GenSigCycleTime" SG_ 2566911243 Trailer5NomBodyLevel_RearLevel 100;
BA_ "GenSigCycleTimeActive" SG_ 2566911243 Trailer5NomBodyLevel_RearLevel 100;
BA_ "GenSigStartValue" SG_ 2566911243 Trailer5NomBodyLevel_RearLevel 65535;
BA_ "GenSigCycleTime" SG_ 2566911243 Trailer5ElectricalSupplyStat 100;
BA_ "GenSigCycleTimeActive" SG_ 2566911243 Trailer5ElectricalSupplyStat 100;
BA_ "GenSigStartValue" SG_ 2566911243 Trailer5ElectricalSupplyStat 3;
BA_ "GenSigCycleTime" SG_ 2566911243 Trailer5YCSystemStatus 100;
BA_ "GenSigCycleTimeActive" SG_ 2566911243 Trailer5YCSystemStatus 100;
BA_ "GenSigStartValue" SG_ 2566911243 Trailer5YCSystemStatus 3;
BA_ "GenSigCycleTime" SG_ 2566906891 Trailer4NomBodyLevel_RearLevel 100;
BA_ "GenSigCycleTimeActive" SG_ 2566906891 Trailer4NomBodyLevel_RearLevel 100;
BA_ "GenSigStartValue" SG_ 2566906891 Trailer4NomBodyLevel_RearLevel 65535;
BA_ "GenSigCycleTime" SG_ 2566906891 Trailer4LoadRampApprAssistStat 100;
BA_ "GenSigCycleTimeActive" SG_ 2566906891 Trailer4LoadRampApprAssistStat 100;
BA_ "GenSigStartValue" SG_ 2566906891 Trailer4LoadRampApprAssistStat 3;
BA_ "GenSigCycleTime" SG_ 2566906891 Trailer4EBSRedWarning 100;
BA_ "GenSigCycleTimeActive" SG_ 2566906891 Trailer4EBSRedWarning 100;
BA_ "GenSigCycleTime" SG_ 2566906891 Trailer4EBSAmberWarning 100;
BA_ "GenSigCycleTimeActive" SG_ 2566906891 Trailer4EBSAmberWarning 100;
BA_ "GenSigStartValue" SG_ 2566906891 Trailer4EBSAmberWarning 3;
BA_ "GenSigCycleTime" SG_ 2566906891 Trailer4ExtLvlStorageSupport 100;
BA_ "GenSigCycleTimeActive" SG_ 2566906891 Trailer4ExtLvlStorageSupport 100;
BA_ "GenSigStartValue" SG_ 2566906891 Trailer4ExtLvlStorageSupport 3;
BA_ "GenSigCycleTime" SG_ 2566906891 Trailer4VehicleType 100;
BA_ "GenSigCycleTimeActive" SG_ 2566906891 Trailer4VehicleType 100;
BA_ "GenSigStartValue" SG_ 2566906891 Trailer4VehicleType 3;
BA_ "GenSigCycleTime" SG_ 2566906891 Trailer4YCSystemStatus 100;
BA_ "GenSigCycleTimeActive" SG_ 2566906891 Trailer4YCSystemStatus 100;
BA_ "GenSigStartValue" SG_ 2566906891 Trailer4YCSystemStatus 3;
BA_ "GenSigCycleTime" SG_ 2566906891 Trailer4PneumSupply_Pressure 100;
BA_ "GenSigCycleTimeActive" SG_ 2566906891 Trailer4PneumSupply_Pressure 100;
BA_ "GenSigStartValue" SG_ 2566906891 Trailer4PneumSupply_Pressure 255;
BA_ "GenSigCycleTime" SG_ 2566906891 Trailer4ElectricalSupplyStat 100;
BA_ "GenSigCycleTimeActive" SG_ 2566906891 Trailer4ElectricalSupplyStat 100;
BA_ "GenSigStartValue" SG_ 2566906891 Trailer4ElectricalSupplyStat 3;
BA_ "GenSigCycleTime" SG_ 2566906891 Trailer4LevelControlStatus 100;
BA_ "GenSigCycleTimeActive" SG_ 2566906891 Trailer4LevelControlStatus 100;
BA_ "GenSigStartValue" SG_ 2566906891 Trailer4LevelControlStatus 3;
BA_ "GenSigCycleTime" SG_ 2566906891 Trailer4ROPSystemStatus 100;
BA_ "GenSigCycleTimeActive" SG_ 2566906891 Trailer4ROPSystemStatus 100;
BA_ "GenSigStartValue" SG_ 2566906891 Trailer4ROPSystemStatus 3;
BA_ "GenSigCycleTime" SG_ 2566906891 Trailer4NomBodyLevel_FrontLevel 100;
BA_ "GenSigCycleTimeActive" SG_ 2566906891 Trailer4NomBodyLevel_FrontLevel 100;
BA_ "GenSigStartValue" SG_ 2566906891 Trailer4NomBodyLevel_FrontLevel 65535;
BA_ "GenSigCycleTime" SG_ 2566906891 Trailer4PneumSupply_Status 100;
BA_ "GenSigCycleTimeActive" SG_ 2566906891 Trailer4PneumSupply_Status 100;
BA_ "GenSigStartValue" SG_ 2566906891 Trailer4PneumSupply_Status 3;
BA_ "GenSigCycleTime" SG_ 2566902283 Trailer3NomBodyLevel_FrontLevel 100;
BA_ "GenSigCycleTimeActive" SG_ 2566902283 Trailer3NomBodyLevel_FrontLevel 100;
BA_ "GenSigStartValue" SG_ 2566902283 Trailer3NomBodyLevel_FrontLevel 65535;
BA_ "GenSigCycleTime" SG_ 2566902283 Trailer3VehicleType 100;
BA_ "GenSigCycleTimeActive" SG_ 2566902283 Trailer3VehicleType 100;
BA_ "GenSigStartValue" SG_ 2566902283 Trailer3VehicleType 3;
BA_ "GenSigCycleTime" SG_ 2566902283 Trailer3PneumSupply_Status 100;
BA_ "GenSigCycleTimeActive" SG_ 2566902283 Trailer3PneumSupply_Status 100;
BA_ "GenSigStartValue" SG_ 2566902283 Trailer3PneumSupply_Status 3;
BA_ "GenSigCycleTime" SG_ 2566902283 Trailer3PneumSupply_Pressure 100;
BA_ "GenSigCycleTimeActive" SG_ 2566902283 Trailer3PneumSupply_Pressure 100;
BA_ "GenSigStartValue" SG_ 2566902283 Trailer3PneumSupply_Pressure 255;
BA_ "GenSigCycleTime" SG_ 2566902283 Trailer3ExtLvlStorageSupport 100;
BA_ "GenSigCycleTimeActive" SG_ 2566902283 Trailer3ExtLvlStorageSupport 100;
BA_ "GenSigStartValue" SG_ 2566902283 Trailer3ExtLvlStorageSupport 3;
BA_ "GenSigCycleTime" SG_ 2566902283 Trailer3LoadRampApprAssistStat 100;
BA_ "GenSigCycleTimeActive" SG_ 2566902283 Trailer3LoadRampApprAssistStat 100;
BA_ "GenSigStartValue" SG_ 2566902283 Trailer3LoadRampApprAssistStat 3;
BA_ "GenSigCycleTime" SG_ 2566902283 Trailer3ElectricalSupplyStat 100;
BA_ "GenSigCycleTimeActive" SG_ 2566902283 Trailer3ElectricalSupplyStat 100;
BA_ "GenSigStartValue" SG_ 2566902283 Trailer3ElectricalSupplyStat 3;
BA_ "GenSigCycleTime" SG_ 2566902283 Trailer3EBSRedWarning 100;
BA_ "GenSigCycleTimeActive" SG_ 2566902283 Trailer3EBSRedWarning 100;
BA_ "GenSigStartValue" SG_ 2566902283 Trailer3EBSRedWarning 3;
BA_ "GenSigCycleTime" SG_ 2566902283 Trailer3ROPSystemStatus 100;
BA_ "GenSigCycleTimeActive" SG_ 2566902283 Trailer3ROPSystemStatus 100;
BA_ "GenSigStartValue" SG_ 2566902283 Trailer3ROPSystemStatus 3;
BA_ "GenSigCycleTime" SG_ 2566902283 Trailer3EBSAmberWarning 100;
BA_ "GenSigCycleTimeActive" SG_ 2566902283 Trailer3EBSAmberWarning 100;
BA_ "GenSigStartValue" SG_ 2566902283 Trailer3EBSAmberWarning 3;
BA_ "GenSigCycleTime" SG_ 2566902283 Trailer3LevelControlStatus 100;
BA_ "GenSigCycleTimeActive" SG_ 2566902283 Trailer3LevelControlStatus 100;
BA_ "GenSigStartValue" SG_ 2566902283 Trailer3LevelControlStatus 3;
BA_ "GenSigCycleTime" SG_ 2566902283 Trailer3NomBodyLevel_RearLevel 100;
BA_ "GenSigCycleTimeActive" SG_ 2566902283 Trailer3NomBodyLevel_RearLevel 100;
BA_ "GenSigStartValue" SG_ 2566902283 Trailer3NomBodyLevel_RearLevel 65535;
BA_ "GenSigCycleTime" SG_ 2566902283 Trailer3YCSystemStatus 100;
BA_ "GenSigCycleTimeActive" SG_ 2566902283 Trailer3YCSystemStatus 100;
BA_ "GenSigStartValue" SG_ 2566902283 Trailer3YCSystemStatus 3;
BA_REL_ "GenSigFirstTimeoutTime" BU_SG_REL_ EBS SG_ 2348814097 TSC1EMSrVMCU_EnRTrqTrqLm 3000;
BA_REL_ "GenSigTimeoutTime" BU_SG_REL_ EBS SG_ 2348814097 TSC1EMSrVMCU_EnRTrqTrqLm 300;
BA_REL_ "GenSigFirstTimeoutTime" BU_SG_REL_ ECM SG_ 2348814097 TSC1EMSrVMCU_EnRTrqTrqLm 3000;
BA_REL_ "GenSigTimeoutTime" BU_SG_REL_ ECM SG_ 2348814097 TSC1EMSrVMCU_EnRTrqTrqLm 300;
BA_REL_ "GenSigFirstTimeoutTime" BU_SG_REL_ EBS SG_ 2348814097 TSC1EMSrVMCU_EnRSpdCtrlC 3000;
BA_REL_ "GenSigTimeoutTime" BU_SG_REL_ EBS SG_ 2348814097 TSC1EMSrVMCU_EnRSpdCtrlC 300;
BA_REL_ "GenSigFirstTimeoutTime" BU_SG_REL_ ECM SG_ 2348814097 TSC1EMSrVMCU_EnRSpdCtrlC 3000;
BA_REL_ "GenSigTimeoutTime" BU_SG_REL_ ECM SG_ 2348814097 TSC1EMSrVMCU_EnRSpdCtrlC 300;
BA_REL_ "GenSigFirstTimeoutTime" BU_SG_REL_ EBS SG_ 2348814097 TSC1EMSrVMCU_OvrdCtrlMPr 3000;
BA_REL_ "GenSigTimeoutTime" BU_SG_REL_ EBS SG_ 2348814097 TSC1EMSrVMCU_OvrdCtrlMPr 300;
BA_REL_ "GenSigFirstTimeoutTime" BU_SG_REL_ ECM SG_ 2348814097 TSC1EMSrVMCU_OvrdCtrlMPr 3000;
BA_REL_ "GenSigTimeoutTime" BU_SG_REL_ ECM SG_ 2348814097 TSC1EMSrVMCU_OvrdCtrlMPr 300;
BA_REL_ "GenSigFirstTimeoutTime" BU_SG_REL_ EBS SG_ 2348814097 TSC1EMSrVMCU_EnOvrdCtrlM 3000;
BA_REL_ "GenSigTimeoutTime" BU_SG_REL_ EBS SG_ 2348814097 TSC1EMSrVMCU_EnOvrdCtrlM 300;
BA_REL_ "GenSigFirstTimeoutTime" BU_SG_REL_ ECM SG_ 2348814097 TSC1EMSrVMCU_EnOvrdCtrlM 3000;
BA_REL_ "GenSigTimeoutTime" BU_SG_REL_ ECM SG_ 2348814097 TSC1EMSrVMCU_EnOvrdCtrlM 300;
BA_REL_ "GenSigFirstTimeoutTime" BU_SG_REL_ EBS SG_ 2348814097 TSC1EMSrVMCU_EnRSpdSpdLm 3000;
BA_REL_ "GenSigTimeoutTime" BU_SG_REL_ EBS SG_ 2348814097 TSC1EMSrVMCU_EnRSpdSpdLm 300;
BA_REL_ "GenSigFirstTimeoutTime" BU_SG_REL_ ECM SG_ 2348814097 TSC1EMSrVMCU_EnRSpdSpdLm 3000;
BA_REL_ "GenSigTimeoutTime" BU_SG_REL_ ECM SG_ 2348814097 TSC1EMSrVMCU_EnRSpdSpdLm 300;
BA_REL_ "GenSigFirstTimeoutTime" BU_SG_REL_ VCM SG_ 2348814083 TSC1EMSrTECU_EnOvrdCtrlM 3000;
BA_REL_ "GenSigTimeoutTime" BU_SG_REL_ VCM SG_ 2348814083 TSC1EMSrTECU_EnOvrdCtrlM 300;
BA_REL_ "GenSigFirstTimeoutTime" BU_SG_REL_ ECM SG_ 2348814083 TSC1EMSrTECU_EnOvrdCtrlM 3000;
BA_REL_ "GenSigTimeoutTime" BU_SG_REL_ ECM SG_ 2348814083 TSC1EMSrTECU_EnOvrdCtrlM 300;
BA_REL_ "GenSigFirstTimeoutTime" BU_SG_REL_ VCM SG_ 2348814083 TSC1EMSrTECU_EnRSpdCtrlC 3000;
BA_REL_ "GenSigTimeoutTime" BU_SG_REL_ VCM SG_ 2348814083 TSC1EMSrTECU_EnRSpdCtrlC 300;
BA_REL_ "GenSigFirstTimeoutTime" BU_SG_REL_ ECM SG_ 2348814083 TSC1EMSrTECU_EnRSpdCtrlC 3000;
BA_REL_ "GenSigTimeoutTime" BU_SG_REL_ ECM SG_ 2348814083 TSC1EMSrTECU_EnRSpdCtrlC 300;
BA_REL_ "GenSigFirstTimeoutTime" BU_SG_REL_ VCM SG_ 2348814083 TSC1EMSrTECU_EnRTrqTrqLm 3000;
BA_REL_ "GenSigTimeoutTime" BU_SG_REL_ VCM SG_ 2348814083 TSC1EMSrTECU_EnRTrqTrqLm 300;
BA_REL_ "GenSigFirstTimeoutTime" BU_SG_REL_ ECM SG_ 2348814083 TSC1EMSrTECU_EnRTrqTrqLm 3000;
BA_REL_ "GenSigTimeoutTime" BU_SG_REL_ ECM SG_ 2348814083 TSC1EMSrTECU_EnRTrqTrqLm 300;
BA_REL_ "GenSigFirstTimeoutTime" BU_SG_REL_ ECM SG_ 2348814083 TSC1EMSrTECU_EnRSpdSpdLm 3000;
BA_REL_ "GenSigTimeoutTime" BU_SG_REL_ ECM SG_ 2348814083 TSC1EMSrTECU_EnRSpdSpdLm 300;
BA_REL_ "GenSigFirstTimeoutTime" BU_SG_REL_ VCM SG_ 2348814083 TSC1EMSrTECU_EnRSpdSpdLm 3000;
BA_REL_ "GenSigTimeoutTime" BU_SG_REL_ VCM SG_ 2348814083 TSC1EMSrTECU_EnRSpdSpdLm 300;
BA_REL_ "GenSigFirstTimeoutTime" BU_SG_REL_ VCM SG_ 2348814083 TSC1EMSrTECU_OvrdCtrlMPr 3000;
BA_REL_ "GenSigTimeoutTime" BU_SG_REL_ VCM SG_ 2348814083 TSC1EMSrTECU_OvrdCtrlMPr 300;
BA_REL_ "GenSigFirstTimeoutTime" BU_SG_REL_ ECM SG_ 2348814083 TSC1EMSrTECU_OvrdCtrlMPr 3000;
BA_REL_ "GenSigTimeoutTime" BU_SG_REL_ ECM SG_ 2348814083 TSC1EMSrTECU_OvrdCtrlMPr 300;
BA_REL_ "GenSigFirstTimeoutTime" BU_SG_REL_ TCM SG_ 2348814091 TSC1EMSrABS_OvrdCtrlMPr 3000;
BA_REL_ "GenSigTimeoutTime" BU_SG_REL_ TCM SG_ 2348814091 TSC1EMSrABS_OvrdCtrlMPr 300;
BA_REL_ "GenSigFirstTimeoutTime" BU_SG_REL_ ECM SG_ 2348814091 TSC1EMSrABS_OvrdCtrlMPr 3000;
BA_REL_ "GenSigTimeoutTime" BU_SG_REL_ ECM SG_ 2348814091 TSC1EMSrABS_OvrdCtrlMPr 300;
BA_REL_ "GenSigFirstTimeoutTime" BU_SG_REL_ ECM SG_ 2348814091 TSC1EMSrABS_EnRTrqTrqLm 3000;
BA_REL_ "GenSigTimeoutTime" BU_SG_REL_ ECM SG_ 2348814091 TSC1EMSrABS_EnRTrqTrqLm 300;
BA_REL_ "GenSigFirstTimeoutTime" BU_SG_REL_ TCM SG_ 2348814091 TSC1EMSrABS_EnRTrqTrqLm 3000;
BA_REL_ "GenSigTimeoutTime" BU_SG_REL_ TCM SG_ 2348814091 TSC1EMSrABS_EnRTrqTrqLm 300;
BA_REL_ "GenSigFirstTimeoutTime" BU_SG_REL_ ECM SG_ 2348814091 TSC1EMSrABS_EnRSpdCtrlC 3000;
BA_REL_ "GenSigTimeoutTime" BU_SG_REL_ ECM SG_ 2348814091 TSC1EMSrABS_EnRSpdCtrlC 300;
BA_REL_ "GenSigFirstTimeoutTime" BU_SG_REL_ TCM SG_ 2348814091 TSC1EMSrABS_EnRSpdCtrlC 3000;
BA_REL_ "GenSigTimeoutTime" BU_SG_REL_ TCM SG_ 2348814091 TSC1EMSrABS_EnRSpdCtrlC 300;
BA_REL_ "GenSigFirstTimeoutTime" BU_SG_REL_ TCM SG_ 2348814091 TSC1EMSrABS_EnOvrdCtrlM 3000;
BA_REL_ "GenSigTimeoutTime" BU_SG_REL_ TCM SG_ 2348814091 TSC1EMSrABS_EnOvrdCtrlM 300;
BA_REL_ "GenSigFirstTimeoutTime" BU_SG_REL_ ECM SG_ 2348814091 TSC1EMSrABS_EnOvrdCtrlM 3000;
BA_REL_ "GenSigTimeoutTime" BU_SG_REL_ ECM SG_ 2348814091 TSC1EMSrABS_EnOvrdCtrlM 300;
BA_REL_ "GenSigFirstTimeoutTime" BU_SG_REL_ TCM SG_ 2348814091 TSC1EMSrABS_EnRSpdSpdLm 3000;
BA_REL_ "GenSigTimeoutTime" BU_SG_REL_ TCM SG_ 2348814091 TSC1EMSrABS_EnRSpdSpdLm 300;
BA_REL_ "GenSigFirstTimeoutTime" BU_SG_REL_ ECM SG_ 2348814091 TSC1EMSrABS_EnRSpdSpdLm 3000;
BA_REL_ "GenSigTimeoutTime" BU_SG_REL_ ECM SG_ 2348814091 TSC1EMSrABS_EnRSpdSpdLm 300;
BA_REL_ "GenSigFirstTimeoutTime" BU_SG_REL_ VCM SG_ 2566846467 TransmissionOilLevel_ISig_1 24000;
BA_REL_ "GenSigTimeoutTime" BU_SG_REL_ VCM SG_ 2566846467 TransmissionOilLevel_ISig_1 6000;
BA_REL_ "GenSigFirstTimeoutTime" BU_SG_REL_ ECM SG_ 2566846467 TransmissionOilTemp_ISig_1 24000;
BA_REL_ "GenSigTimeoutTime" BU_SG_REL_ ECM SG_ 2566846467 TransmissionOilTemp_ISig_1 6000;
BA_REL_ "GenSigFirstTimeoutTime" BU_SG_REL_ VCM SG_ 2566846467 TransmissionOilTemp_ISig_1 24000;
BA_REL_ "GenSigTimeoutTime" BU_SG_REL_ VCM SG_ 2566846467 TransmissionOilTemp_ISig_1 6000;
BA_REL_ "GenSigFirstTimeoutTime" BU_SG_REL_ ECM SG_ 2566882307 TransmissionGCVW 3000;
BA_REL_ "GenSigTimeoutTime" BU_SG_REL_ ECM SG_ 2566882307 TransmissionGCVW 570;
BA_REL_ "GenSigFirstTimeoutTime" BU_SG_REL_ VCM SG_ 2566882307 TransmissionGCVW 3000;
BA_REL_ "GenSigTimeoutTime" BU_SG_REL_ VCM SG_ 2566882307 TransmissionGCVW 600;
BA_REL_ "GenSigFirstTimeoutTime" BU_SG_REL_ VCM SG_ 2566882307 TransmEngineCrankEnable2_ISig_1 3000;
BA_REL_ "GenSigTimeoutTime" BU_SG_REL_ VCM SG_ 2566882307 TransmEngineCrankEnable2_ISig_1 600;
BA_REL_ "GenSigFirstTimeoutTime" BU_SG_REL_ VCM SG_ 2566882307 PwtFunctionalitySt 3000;
BA_REL_ "GenSigTimeoutTime" BU_SG_REL_ VCM SG_ 2566882307 PwtFunctionalitySt 600;
BA_REL_ "GenSigFirstTimeoutTime" BU_SG_REL_ VCM SG_ 2566882307 LowTempClutchInfo_ISig_1 3000;
BA_REL_ "GenSigTimeoutTime" BU_SG_REL_ VCM SG_ 2566882307 LowTempClutchInfo_ISig_1 600;
BA_REL_ "GenSigFirstTimeoutTime" BU_SG_REL_ VCM SG_ 2566882307 PwtFunctionalitySt_FaultInfo 3000;
BA_REL_ "GenSigTimeoutTime" BU_SG_REL_ VCM SG_ 2566882307 PwtFunctionalitySt_FaultInfo 600;
BA_REL_ "GenSigFirstTimeoutTime" BU_SG_REL_ VCM SG_ 2566882307 RawRoadInclination 3000;
BA_REL_ "GenSigTimeoutTime" BU_SG_REL_ VCM SG_ 2566882307 RawRoadInclination 600;
BA_REL_ "GenSigFirstTimeoutTime" BU_SG_REL_ EBS SG_ 2566882307 PermittedHSAPressure 3000;
BA_REL_ "GenSigTimeoutTime" BU_SG_REL_ EBS SG_ 2566882307 PermittedHSAPressure 570;
BA_REL_ "GenSigFirstTimeoutTime" BU_SG_REL_ VCM SG_ 2566882307 PermittedHSAPressure 3000;
BA_REL_ "GenSigTimeoutTime" BU_SG_REL_ VCM SG_ 2566882307 PermittedHSAPressure 600;
BA_REL_ "GenSigFirstTimeoutTime" BU_SG_REL_ ACM SG_ 2566841879 MinutesUTC_ISig_1 6000;
BA_REL_ "GenSigTimeoutTime" BU_SG_REL_ ACM SG_ 2566841879 MinutesUTC_ISig_1 1500;
BA_REL_ "GenSigFirstTimeoutTime" BU_SG_REL_ EBS SG_ 2566841879 MinutesUTC_ISig_1 6000;
BA_REL_ "GenSigTimeoutTime" BU_SG_REL_ EBS SG_ 2566841879 MinutesUTC_ISig_1 1500;
BA_REL_ "GenSigFirstTimeoutTime" BU_SG_REL_ ECM SG_ 2566841879 MinutesUTC_ISig_1 6000;
BA_REL_ "GenSigTimeoutTime" BU_SG_REL_ ECM SG_ 2566841879 MinutesUTC_ISig_1 1500;
BA_REL_ "GenSigFirstTimeoutTime" BU_SG_REL_ TCM SG_ 2566841879 MinutesUTC_ISig_1 6000;
BA_REL_ "GenSigTimeoutTime" BU_SG_REL_ TCM SG_ 2566841879 MinutesUTC_ISig_1 1500;
BA_REL_ "GenSigFirstTimeoutTime" BU_SG_REL_ ACM SG_ 2566841879 MonthUTC_ISig_1 6000;
BA_REL_ "GenSigTimeoutTime" BU_SG_REL_ ACM SG_ 2566841879 MonthUTC_ISig_1 1500;
BA_REL_ "GenSigFirstTimeoutTime" BU_SG_REL_ ECM SG_ 2566841879 MonthUTC_ISig_1 6000;
BA_REL_ "GenSigTimeoutTime" BU_SG_REL_ ECM SG_ 2566841879 MonthUTC_ISig_1 1500;
BA_REL_ "GenSigFirstTimeoutTime" BU_SG_REL_ EBS SG_ 2566841879 MonthUTC_ISig_1 6000;
BA_REL_ "GenSigTimeoutTime" BU_SG_REL_ EBS SG_ 2566841879 MonthUTC_ISig_1 1500;
BA_REL_ "GenSigFirstTimeoutTime" BU_SG_REL_ TCM SG_ 2566841879 MonthUTC_ISig_1 6000;
BA_REL_ "GenSigTimeoutTime" BU_SG_REL_ TCM SG_ 2566841879 MonthUTC_ISig_1 1500;
BA_REL_ "GenSigFirstTimeoutTime" BU_SG_REL_ ACM SG_ 2566841879 YearUTC_ISig_1 6000;
BA_REL_ "GenSigTimeoutTime" BU_SG_REL_ ACM SG_ 2566841879 YearUTC_ISig_1 1500;
BA_REL_ "GenSigFirstTimeoutTime" BU_SG_REL_ TCM SG_ 2566841879 YearUTC_ISig_1 6000;
BA_REL_ "GenSigTimeoutTime" BU_SG_REL_ TCM SG_ 2566841879 YearUTC_ISig_1 1500;
BA_REL_ "GenSigFirstTimeoutTime" BU_SG_REL_ ECM SG_ 2566841879 YearUTC_ISig_1 6000;
BA_REL_ "GenSigTimeoutTime" BU_SG_REL_ ECM SG_ 2566841879 YearUTC_ISig_1 1500;
BA_REL_ "GenSigFirstTimeoutTime" BU_SG_REL_ EBS SG_ 2566841879 YearUTC_ISig_1 6000;
BA_REL_ "GenSigTimeoutTime" BU_SG_REL_ EBS SG_ 2566841879 YearUTC_ISig_1 1500;
BA_REL_ "GenSigFirstTimeoutTime" BU_SG_REL_ EBS SG_ 2566841879 SelectedLocalHourOffset 6000;
BA_REL_ "GenSigTimeoutTime" BU_SG_REL_ EBS SG_ 2566841879 SelectedLocalHourOffset 1500;
BA_REL_ "GenSigFirstTimeoutTime" BU_SG_REL_ ECM SG_ 2566841879 HoursUTC_ISig_1 6000;
BA_REL_ "GenSigTimeoutTime" BU_SG_REL_ ECM SG_ 2566841879 HoursUTC_ISig_1 1500;
BA_REL_ "GenSigFirstTimeoutTime" BU_SG_REL_ TCM SG_ 2566841879 HoursUTC_ISig_1 6000;
BA_REL_ "GenSigTimeoutTime" BU_SG_REL_ TCM SG_ 2566841879 HoursUTC_ISig_1 1500;
BA_REL_ "GenSigFirstTimeoutTime" BU_SG_REL_ ACM SG_ 2566841879 HoursUTC_ISig_1 6000;
BA_REL_ "GenSigTimeoutTime" BU_SG_REL_ ACM SG_ 2566841879 HoursUTC_ISig_1 1500;
BA_REL_ "GenSigFirstTimeoutTime" BU_SG_REL_ EBS SG_ 2566841879 HoursUTC_ISig_1 6000;
BA_REL_ "GenSigTimeoutTime" BU_SG_REL_ EBS SG_ 2566841879 HoursUTC_ISig_1 1500;
BA_REL_ "GenSigFirstTimeoutTime" BU_SG_REL_ EBS SG_ 2566841879 DayUTC_ISig_1 6000;
BA_REL_ "GenSigTimeoutTime" BU_SG_REL_ EBS SG_ 2566841879 DayUTC_ISig_1 1500;
BA_REL_ "GenSigFirstTimeoutTime" BU_SG_REL_ ECM SG_ 2566841879 DayUTC_ISig_1 6000;
BA_REL_ "GenSigTimeoutTime" BU_SG_REL_ ECM SG_ 2566841879 DayUTC_ISig_1 1500;
BA_REL_ "GenSigFirstTimeoutTime" BU_SG_REL_ TCM SG_ 2566841879 DayUTC_ISig_1 6000;
BA_REL_ "GenSigTimeoutTime" BU_SG_REL_ TCM SG_ 2566841879 DayUTC_ISig_1 1500;
BA_REL_ "GenSigFirstTimeoutTime" BU_SG_REL_ ACM SG_ 2566841879 DayUTC_ISig_1 6000;
BA_REL_ "GenSigTimeoutTime" BU_SG_REL_ ACM SG_ 2566841879 DayUTC_ISig_1 1500;
BA_REL_ "GenSigFirstTimeoutTime" BU_SG_REL_ ECM SG_ 2566841879 SecondsUTC_ISig_1 6000;
BA_REL_ "GenSigTimeoutTime" BU_SG_REL_ ECM SG_ 2566841879 SecondsUTC_ISig_1 1500;
BA_REL_ "GenSigFirstTimeoutTime" BU_SG_REL_ ACM SG_ 2566841879 SecondsUTC_ISig_1 6000;
BA_REL_ "GenSigTimeoutTime" BU_SG_REL_ ACM SG_ 2566841879 SecondsUTC_ISig_1 1500;
BA_REL_ "GenSigFirstTimeoutTime" BU_SG_REL_ TCM SG_ 2566841879 SecondsUTC_ISig_1 6000;
BA_REL_ "GenSigTimeoutTime" BU_SG_REL_ TCM SG_ 2566841879 SecondsUTC_ISig_1 1500;
BA_REL_ "GenSigFirstTimeoutTime" BU_SG_REL_ EBS SG_ 2566841879 SecondsUTC_ISig_1 6000;
BA_REL_ "GenSigTimeoutTime" BU_SG_REL_ EBS SG_ 2566841879 SecondsUTC_ISig_1 1500;
BA_REL_ "GenSigFirstTimeoutTime" BU_SG_REL_ EBS SG_ 2566841879 SelectedLocalMinuteOffset 6000;
BA_REL_ "GenSigTimeoutTime" BU_SG_REL_ EBS SG_ 2566841879 SelectedLocalMinuteOffset 1500;
BA_REL_ "GenSigFirstTimeoutTime" BU_SG_REL_ ECM SG_ 2365528579 RoadInclination_ISig_1 3000;
BA_REL_ "GenSigTimeoutTime" BU_SG_REL_ ECM SG_ 2365528579 RoadInclination_ISig_1 150;
BA_REL_ "GenSigFirstTimeoutTime" BU_SG_REL_ VCM SG_ 2365528579 RoadInclination_ISig_1 3000;
BA_REL_ "GenSigTimeoutTime" BU_SG_REL_ VCM SG_ 2365528579 RoadInclination_ISig_1 150;
BA_REL_ "GenSigFirstTimeoutTime" BU_SG_REL_ EBS SG_ 2365528579 RoadInclination_ISig_1 3000;
BA_REL_ "GenSigTimeoutTime" BU_SG_REL_ EBS SG_ 2365528579 RoadInclination_ISig_1 150;
BA_REL_ "GenSigFirstTimeoutTime" BU_SG_REL_ EBS SG_ 2365528579 TransmOutputShaftSpeedSigned 3000;
BA_REL_ "GenSigTimeoutTime" BU_SG_REL_ EBS SG_ 2365528579 TransmOutputShaftSpeedSigned 150;
BA_REL_ "GenSigFirstTimeoutTime" BU_SG_REL_ VCM SG_ 2365528579 TransmOutputShaftSpeedSigned 3000;
BA_REL_ "GenSigTimeoutTime" BU_SG_REL_ VCM SG_ 2365528579 TransmOutputShaftSpeedSigned 150;
BA_REL_ "GenSigFirstTimeoutTime" BU_SG_REL_ VCM SG_ 2499792656 DrivelineRetarderStat_ISig_1 3600;
BA_REL_ "GenSigTimeoutTime" BU_SG_REL_ VCM SG_ 2499792656 DrivelineRetarderStat_ISig_1 900;
BA_REL_ "GenSigFirstTimeoutTime" BU_SG_REL_ EBS SG_ 2566840592 DrivelineRetarderLocation 65000;
BA_REL_ "GenSigTimeoutTime" BU_SG_REL_ EBS SG_ 2566840592 DrivelineRetarderLocation 30000;
BA_REL_ "GenSigFirstTimeoutTime" BU_SG_REL_ ECM SG_ 2566840592 DrivelineRetarderLocation 65000;
BA_REL_ "GenSigTimeoutTime" BU_SG_REL_ ECM SG_ 2566840592 DrivelineRetarderLocation 30000;
BA_REL_ "GenSigFirstTimeoutTime" BU_SG_REL_ VCM SG_ 2566840592 DrivelineRetarderLocation 65000;
BA_REL_ "GenSigTimeoutTime" BU_SG_REL_ VCM SG_ 2566840592 DrivelineRetarderLocation 30000;
BA_REL_ "GenSigFirstTimeoutTime" BU_SG_REL_ EBS SG_ 2566840592 DrivelineRetarderType 65000;
BA_REL_ "GenSigTimeoutTime" BU_SG_REL_ EBS SG_ 2566840592 DrivelineRetarderType 30000;
BA_REL_ "GenSigFirstTimeoutTime" BU_SG_REL_ EBS SG_ 2566840592 DrivelineRetarderRefTorque 65000;
BA_REL_ "GenSigTimeoutTime" BU_SG_REL_ EBS SG_ 2566840592 DrivelineRetarderRefTorque 30000;
BA_REL_ "GenSigFirstTimeoutTime" BU_SG_REL_ ECM SG_ 2566840592 DrivelineRetarderRefTorque 65000;
BA_REL_ "GenSigTimeoutTime" BU_SG_REL_ ECM SG_ 2566840592 DrivelineRetarderRefTorque 30000;
BA_REL_ "GenSigFirstTimeoutTime" BU_SG_REL_ VCM SG_ 2566840592 DrivelineRetarderRefTorque 65000;
BA_REL_ "GenSigTimeoutTime" BU_SG_REL_ VCM SG_ 2566840592 DrivelineRetarderRefTorque 30000;
BA_REL_ "GenSigFirstTimeoutTime" BU_SG_REL_ TCM SG_ 2566840592 DrivelineRetarderRefTorque 60000;
BA_REL_ "GenSigTimeoutTime" BU_SG_REL_ TCM SG_ 2566840592 DrivelineRetarderRefTorque 30000;
BA_REL_ "GenSigFirstTimeoutTime" BU_SG_REL_ TCM SG_ 2566840591 EngRetConf_PerTrqAtP3 65000;
BA_REL_ "GenSigTimeoutTime" BU_SG_REL_ TCM SG_ 2566840591 EngRetConf_PerTrqAtP3 30000;
BA_REL_ "GenSigFirstTimeoutTime" BU_SG_REL_ EBS SG_ 2566840591 EngRetConf_PerTrqAtP3 65000;
BA_REL_ "GenSigTimeoutTime" BU_SG_REL_ EBS SG_ 2566840591 EngRetConf_PerTrqAtP3 30000;
BA_REL_ "GenSigFirstTimeoutTime" BU_SG_REL_ VCM SG_ 2566840591 EngRetConf_PerTrqAtP3 65000;
BA_REL_ "GenSigTimeoutTime" BU_SG_REL_ VCM SG_ 2566840591 EngRetConf_PerTrqAtP3 30000;
BA_REL_ "GenSigFirstTimeoutTime" BU_SG_REL_ VCM SG_ 2566840591 EngRetConf_RetSpeedAtP5 65000;
BA_REL_ "GenSigTimeoutTime" BU_SG_REL_ VCM SG_ 2566840591 EngRetConf_RetSpeedAtP5 30000;
BA_REL_ "GenSigFirstTimeoutTime" BU_SG_REL_ EBS SG_ 2566840591 EngRetConf_RetSpeedAtP5 65000;
BA_REL_ "GenSigTimeoutTime" BU_SG_REL_ EBS SG_ 2566840591 EngRetConf_RetSpeedAtP5 30000;
BA_REL_ "GenSigFirstTimeoutTime" BU_SG_REL_ TCM SG_ 2566840591 EngRetConf_RetSpeedAtP5 65000;
BA_REL_ "GenSigTimeoutTime" BU_SG_REL_ TCM SG_ 2566840591 EngRetConf_RetSpeedAtP5 30000;
BA_REL_ "GenSigFirstTimeoutTime" BU_SG_REL_ EBS SG_ 2566840591 EngRetConf_MaxRetSpeedP2 65000;
BA_REL_ "GenSigTimeoutTime" BU_SG_REL_ EBS SG_ 2566840591 EngRetConf_MaxRetSpeedP2 30000;
BA_REL_ "GenSigFirstTimeoutTime" BU_SG_REL_ VCM SG_ 2566840591 EngRetConf_MaxRetSpeedP2 65000;
BA_REL_ "GenSigTimeoutTime" BU_SG_REL_ VCM SG_ 2566840591 EngRetConf_MaxRetSpeedP2 30000;
BA_REL_ "GenSigFirstTimeoutTime" BU_SG_REL_ TCM SG_ 2566840591 EngRetConf_MaxRetSpeedP2 65000;
BA_REL_ "GenSigTimeoutTime" BU_SG_REL_ TCM SG_ 2566840591 EngRetConf_MaxRetSpeedP2 30000;
BA_REL_ "GenSigFirstTimeoutTime" BU_SG_REL_ TCM SG_ 2566840591 EngRetConf_RetSpeedAtP3 65000;
BA_REL_ "GenSigTimeoutTime" BU_SG_REL_ TCM SG_ 2566840591 EngRetConf_RetSpeedAtP3 30000;
BA_REL_ "GenSigFirstTimeoutTime" BU_SG_REL_ VCM SG_ 2566840591 EngRetConf_RetSpeedAtP3 65000;
BA_REL_ "GenSigTimeoutTime" BU_SG_REL_ VCM SG_ 2566840591 EngRetConf_RetSpeedAtP3 30000;
BA_REL_ "GenSigFirstTimeoutTime" BU_SG_REL_ EBS SG_ 2566840591 EngRetConf_RetSpeedAtP3 65000;
BA_REL_ "GenSigTimeoutTime" BU_SG_REL_ EBS SG_ 2566840591 EngRetConf_RetSpeedAtP3 30000;
BA_REL_ "GenSigFirstTimeoutTime" BU_SG_REL_ EBS SG_ 2566840591 EngRetConf_PerTrqAtP4 65000;
BA_REL_ "GenSigTimeoutTime" BU_SG_REL_ EBS SG_ 2566840591 EngRetConf_PerTrqAtP4 30000;
BA_REL_ "GenSigFirstTimeoutTime" BU_SG_REL_ VCM SG_ 2566840591 EngRetConf_PerTrqAtP4 65000;
BA_REL_ "GenSigTimeoutTime" BU_SG_REL_ VCM SG_ 2566840591 EngRetConf_PerTrqAtP4 30000;
BA_REL_ "GenSigFirstTimeoutTime" BU_SG_REL_ TCM SG_ 2566840591 EngRetConf_PerTrqAtP4 65000;
BA_REL_ "GenSigTimeoutTime" BU_SG_REL_ TCM SG_ 2566840591 EngRetConf_PerTrqAtP4 30000;
BA_REL_ "GenSigFirstTimeoutTime" BU_SG_REL_ EBS SG_ 2566840591 EngRetConf_PerTrqAtP5 65000;
BA_REL_ "GenSigTimeoutTime" BU_SG_REL_ EBS SG_ 2566840591 EngRetConf_PerTrqAtP5 30000;
BA_REL_ "GenSigFirstTimeoutTime" BU_SG_REL_ TCM SG_ 2566840591 EngRetConf_PerTrqAtP5 65000;
BA_REL_ "GenSigTimeoutTime" BU_SG_REL_ TCM SG_ 2566840591 EngRetConf_PerTrqAtP5 30000;
BA_REL_ "GenSigFirstTimeoutTime" BU_SG_REL_ VCM SG_ 2566840591 EngRetConf_PerTrqAtP5 65000;
BA_REL_ "GenSigTimeoutTime" BU_SG_REL_ VCM SG_ 2566840591 EngRetConf_PerTrqAtP5 30000;
BA_REL_ "GenSigFirstTimeoutTime" BU_SG_REL_ TCM SG_ 2566840591 EngRetConf_RetCtrlMethod 65000;
BA_REL_ "GenSigTimeoutTime" BU_SG_REL_ TCM SG_ 2566840591 EngRetConf_RetCtrlMethod 30000;
BA_REL_ "GenSigFirstTimeoutTime" BU_SG_REL_ VCM SG_ 2566840591 EngRetConf_RetCtrlMethod 65000;
BA_REL_ "GenSigTimeoutTime" BU_SG_REL_ VCM SG_ 2566840591 EngRetConf_RetCtrlMethod 30000;
BA_REL_ "GenSigFirstTimeoutTime" BU_SG_REL_ EBS SG_ 2566840591 EngRetConf_RetCtrlMethod 65000;
BA_REL_ "GenSigTimeoutTime" BU_SG_REL_ EBS SG_ 2566840591 EngRetConf_RetCtrlMethod 30000;
BA_REL_ "GenSigFirstTimeoutTime" BU_SG_REL_ EBS SG_ 2566840591 ReferenceEngineRetarderTorque 65000;
BA_REL_ "GenSigTimeoutTime" BU_SG_REL_ EBS SG_ 2566840591 ReferenceEngineRetarderTorque 30000;
BA_REL_ "GenSigFirstTimeoutTime" BU_SG_REL_ ACM SG_ 2566840591 ReferenceEngineRetarderTorque 65000;
BA_REL_ "GenSigTimeoutTime" BU_SG_REL_ ACM SG_ 2566840591 ReferenceEngineRetarderTorque 30000;
BA_REL_ "GenSigFirstTimeoutTime" BU_SG_REL_ VCM SG_ 2566840591 ReferenceEngineRetarderTorque 65000;
BA_REL_ "GenSigTimeoutTime" BU_SG_REL_ VCM SG_ 2566840591 ReferenceEngineRetarderTorque 30000;
BA_REL_ "GenSigFirstTimeoutTime" BU_SG_REL_ TCM SG_ 2566840591 ReferenceEngineRetarderTorque 65000;
BA_REL_ "GenSigTimeoutTime" BU_SG_REL_ TCM SG_ 2566840591 ReferenceEngineRetarderTorque 30000;
BA_REL_ "GenSigFirstTimeoutTime" BU_SG_REL_ VCM SG_ 2566840591 EngRetConf_RetSpeedAtP4 65000;
BA_REL_ "GenSigTimeoutTime" BU_SG_REL_ VCM SG_ 2566840591 EngRetConf_RetSpeedAtP4 30000;
BA_REL_ "GenSigFirstTimeoutTime" BU_SG_REL_ TCM SG_ 2566840591 EngRetConf_RetSpeedAtP4 65000;
BA_REL_ "GenSigTimeoutTime" BU_SG_REL_ TCM SG_ 2566840591 EngRetConf_RetSpeedAtP4 30000;
BA_REL_ "GenSigFirstTimeoutTime" BU_SG_REL_ EBS SG_ 2566840591 EngRetConf_RetSpeedAtP4 65000;
BA_REL_ "GenSigTimeoutTime" BU_SG_REL_ EBS SG_ 2566840591 EngRetConf_RetSpeedAtP4 30000;
BA_REL_ "GenSigFirstTimeoutTime" BU_SG_REL_ VCM SG_ 2566840591 EngRetConf_PerTrqAtMaxSpeedP2 65000;
BA_REL_ "GenSigTimeoutTime" BU_SG_REL_ VCM SG_ 2566840591 EngRetConf_PerTrqAtMaxSpeedP2 30000;
BA_REL_ "GenSigFirstTimeoutTime" BU_SG_REL_ EBS SG_ 2566840591 EngRetConf_PerTrqAtMaxSpeedP2 65000;
BA_REL_ "GenSigTimeoutTime" BU_SG_REL_ EBS SG_ 2566840591 EngRetConf_PerTrqAtMaxSpeedP2 30000;
BA_REL_ "GenSigFirstTimeoutTime" BU_SG_REL_ TCM SG_ 2566840591 EngRetConf_PerTrqAtMaxSpeedP2 65000;
BA_REL_ "GenSigTimeoutTime" BU_SG_REL_ TCM SG_ 2566840591 EngRetConf_PerTrqAtMaxSpeedP2 30000;
BA_REL_ "GenSigFirstTimeoutTime" BU_SG_REL_ VCM SG_ 2566840591 EngRetConf_speedAtIdleP1 65000;
BA_REL_ "GenSigTimeoutTime" BU_SG_REL_ VCM SG_ 2566840591 EngRetConf_speedAtIdleP1 30000;
BA_REL_ "GenSigFirstTimeoutTime" BU_SG_REL_ TCM SG_ 2566840591 EngRetConf_speedAtIdleP1 65000;
BA_REL_ "GenSigTimeoutTime" BU_SG_REL_ TCM SG_ 2566840591 EngRetConf_speedAtIdleP1 30000;
BA_REL_ "GenSigFirstTimeoutTime" BU_SG_REL_ EBS SG_ 2566840591 EngRetConf_speedAtIdleP1 65000;
BA_REL_ "GenSigTimeoutTime" BU_SG_REL_ EBS SG_ 2566840591 EngRetConf_speedAtIdleP1 30000;
BA_REL_ "GenSigFirstTimeoutTime" BU_SG_REL_ TCM SG_ 2566840591 EngRetConf_PerTrqAtIdleP1 65000;
BA_REL_ "GenSigTimeoutTime" BU_SG_REL_ TCM SG_ 2566840591 EngRetConf_PerTrqAtIdleP1 30000;
BA_REL_ "GenSigFirstTimeoutTime" BU_SG_REL_ VCM SG_ 2566840591 EngRetConf_PerTrqAtIdleP1 65000;
BA_REL_ "GenSigTimeoutTime" BU_SG_REL_ VCM SG_ 2566840591 EngRetConf_PerTrqAtIdleP1 30000;
BA_REL_ "GenSigFirstTimeoutTime" BU_SG_REL_ EBS SG_ 2566840591 EngRetConf_PerTrqAtIdleP1 65000;
BA_REL_ "GenSigTimeoutTime" BU_SG_REL_ EBS SG_ 2566840591 EngRetConf_PerTrqAtIdleP1 30000;
BA_REL_ "GenSigFirstTimeoutTime" BU_SG_REL_ TCM SG_ 2566759457 Pto1EnableSwitch 3000;
BA_REL_ "GenSigTimeoutTime" BU_SG_REL_ TCM SG_ 2566759457 Pto1EnableSwitch 600;
BA_REL_ "GenSigFirstTimeoutTime" BU_SG_REL_ TCM SG_ 2566759457 Pto2EnableSwitch 3000;
BA_REL_ "GenSigTimeoutTime" BU_SG_REL_ TCM SG_ 2566759457 Pto2EnableSwitch 600;
BA_REL_ "GenSigFirstTimeoutTime" BU_SG_REL_ VCM SG_ 2566759427 Pto2EngagementConsent 3000;
BA_REL_ "GenSigTimeoutTime" BU_SG_REL_ VCM SG_ 2566759427 Pto2EngagementConsent 600;
BA_REL_ "GenSigFirstTimeoutTime" BU_SG_REL_ VCM SG_ 2566759427 Pto1EngagementConsent 3000;
BA_REL_ "GenSigTimeoutTime" BU_SG_REL_ VCM SG_ 2566759427 Pto1EngagementConsent 600;
BA_REL_ "GenSigFirstTimeoutTime" BU_SG_REL_ VCM SG_ 2566844928 InstantaneousFuelEconomy 3000;
BA_REL_ "GenSigTimeoutTime" BU_SG_REL_ VCM SG_ 2566844928 InstantaneousFuelEconomy 600;
BA_REL_ "GenSigFirstTimeoutTime" BU_SG_REL_ VCM SG_ 2566844928 EngineFuelRate_ISig_1 3000;
BA_REL_ "GenSigTimeoutTime" BU_SG_REL_ VCM SG_ 2566844928 EngineFuelRate_ISig_1 600;
BA_REL_ "GenSigFirstTimeoutTime" BU_SG_REL_ VCM SG_ 2566825472 EngineTurbo1BoostPressure_ISig_1 12000;
BA_REL_ "GenSigTimeoutTime" BU_SG_REL_ VCM SG_ 2566825472 EngineTurbo1BoostPressure_ISig_1 3000;
BA_REL_ "GenSigFirstTimeoutTime" BU_SG_REL_ ACM SG_ 2566825472 EngineTurbo1BoostPressure_ISig_1 12000;
BA_REL_ "GenSigTimeoutTime" BU_SG_REL_ ACM SG_ 2566825472 EngineTurbo1BoostPressure_ISig_1 3000;
BA_REL_ "GenSigFirstTimeoutTime" BU_SG_REL_ VCM SG_ 2298372875 RearAxleLeftWheelSpeed_ISig_1 3000;
BA_REL_ "GenSigTimeoutTime" BU_SG_REL_ VCM SG_ 2298372875 RearAxleLeftWheelSpeed_ISig_1 120;
BA_REL_ "GenSigFirstTimeoutTime" BU_SG_REL_ TCM SG_ 2298372875 RearAxleLeftWheelSpeed_ISig_1 3000;
BA_REL_ "GenSigTimeoutTime" BU_SG_REL_ TCM SG_ 2298372875 RearAxleLeftWheelSpeed_ISig_1 120;
BA_REL_ "GenSigFirstTimeoutTime" BU_SG_REL_ ECM SG_ 2298372875 RearAxleLeftWheelSpeed_ISig_1 3000;
BA_REL_ "GenSigTimeoutTime" BU_SG_REL_ ECM SG_ 2298372875 RearAxleLeftWheelSpeed_ISig_1 120;
BA_REL_ "GenSigFirstTimeoutTime" BU_SG_REL_ ECM SG_ 2298372875 FrontAxleLeftWheelSpeed_ISig_1 3000;
BA_REL_ "GenSigTimeoutTime" BU_SG_REL_ ECM SG_ 2298372875 FrontAxleLeftWheelSpeed_ISig_1 120;
BA_REL_ "GenSigFirstTimeoutTime" BU_SG_REL_ VCM SG_ 2298372875 FrontAxleLeftWheelSpeed_ISig_1 3000;
BA_REL_ "GenSigTimeoutTime" BU_SG_REL_ VCM SG_ 2298372875 FrontAxleLeftWheelSpeed_ISig_1 120;
BA_REL_ "GenSigFirstTimeoutTime" BU_SG_REL_ TCM SG_ 2298372875 FrontAxleLeftWheelSpeed_ISig_1 3000;
BA_REL_ "GenSigTimeoutTime" BU_SG_REL_ TCM SG_ 2298372875 FrontAxleLeftWheelSpeed_ISig_1 120;
BA_REL_ "GenSigFirstTimeoutTime" BU_SG_REL_ TCM SG_ 2298372875 FrontAxleRightWheelSpeed_ISig_1 3000;
BA_REL_ "GenSigTimeoutTime" BU_SG_REL_ TCM SG_ 2298372875 FrontAxleRightWheelSpeed_ISig_1 120;
BA_REL_ "GenSigFirstTimeoutTime" BU_SG_REL_ ECM SG_ 2298372875 FrontAxleRightWheelSpeed_ISig_1 3000;
BA_REL_ "GenSigTimeoutTime" BU_SG_REL_ ECM SG_ 2298372875 FrontAxleRightWheelSpeed_ISig_1 120;
BA_REL_ "GenSigFirstTimeoutTime" BU_SG_REL_ VCM SG_ 2298372875 FrontAxleRightWheelSpeed_ISig_1 3000;
BA_REL_ "GenSigTimeoutTime" BU_SG_REL_ VCM SG_ 2298372875 FrontAxleRightWheelSpeed_ISig_1 120;
BA_REL_ "GenSigFirstTimeoutTime" BU_SG_REL_ VCM SG_ 2298372875 RearAxleRightWheelSpeed_ISig_1 3000;
BA_REL_ "GenSigTimeoutTime" BU_SG_REL_ VCM SG_ 2298372875 RearAxleRightWheelSpeed_ISig_1 120;
BA_REL_ "GenSigFirstTimeoutTime" BU_SG_REL_ TCM SG_ 2298372875 RearAxleRightWheelSpeed_ISig_1 3000;
BA_REL_ "GenSigTimeoutTime" BU_SG_REL_ TCM SG_ 2298372875 RearAxleRightWheelSpeed_ISig_1 120;
BA_REL_ "GenSigFirstTimeoutTime" BU_SG_REL_ ECM SG_ 2298372875 RearAxleRightWheelSpeed_ISig_1 3000;
BA_REL_ "GenSigTimeoutTime" BU_SG_REL_ ECM SG_ 2298372875 RearAxleRightWheelSpeed_ISig_1 120;
BA_REL_ "GenSigFirstTimeoutTime" BU_SG_REL_ VCM SG_ 2566719744 HighResEngineTotalFuelUsed 24000;
BA_REL_ "GenSigTimeoutTime" BU_SG_REL_ VCM SG_ 2566719744 HighResEngineTotalFuelUsed 6000;
BA_REL_ "GenSigFirstTimeoutTime" BU_SG_REL_ VCM SG_ 2566841600 EngineRevolutions 65000;
BA_REL_ "GenSigTimeoutTime" BU_SG_REL_ VCM SG_ 2566841600 EngineRevolutions 30000;
BA_REL_ "GenSigFirstTimeoutTime" BU_SG_REL_ VCM SG_ 2566801923 TransmEngineCrankEnable_ISig_1 3000;
BA_REL_ "GenSigTimeoutTime" BU_SG_REL_ VCM SG_ 2566801923 TransmEngineCrankEnable_ISig_1 600;
BA_REL_ "GenSigFirstTimeoutTime" BU_SG_REL_ VCM SG_ 2565866755 TransmissionRangeSelected_ISig_1 3000;
BA_REL_ "GenSigTimeoutTime" BU_SG_REL_ VCM SG_ 2565866755 TransmissionRangeSelected_ISig_1 600;
BA_REL_ "GenSigFirstTimeoutTime" BU_SG_REL_ ECM SG_ 2565866755 TransmissionSelectedGear_ISig_1 3000;
BA_REL_ "GenSigTimeoutTime" BU_SG_REL_ ECM SG_ 2565866755 TransmissionSelectedGear_ISig_1 600;
BA_REL_ "GenSigFirstTimeoutTime" BU_SG_REL_ VCM SG_ 2565866755 TransmissionSelectedGear_ISig_1 3000;
BA_REL_ "GenSigTimeoutTime" BU_SG_REL_ VCM SG_ 2565866755 TransmissionSelectedGear_ISig_1 600;
BA_REL_ "GenSigFirstTimeoutTime" BU_SG_REL_ VCM SG_ 2565866755 TransmissionCurrentGear_ISig_1 3000;
BA_REL_ "GenSigTimeoutTime" BU_SG_REL_ VCM SG_ 2565866755 TransmissionCurrentGear_ISig_1 600;
BA_REL_ "GenSigFirstTimeoutTime" BU_SG_REL_ ECM SG_ 2565866755 TransmissionCurrentGear_ISig_1 3000;
BA_REL_ "GenSigTimeoutTime" BU_SG_REL_ ECM SG_ 2565866755 TransmissionCurrentGear_ISig_1 600;
BA_REL_ "GenSigFirstTimeoutTime" BU_SG_REL_ EBS SG_ 2565866755 TransmissionCurrentGear_ISig_1 3000;
BA_REL_ "GenSigTimeoutTime" BU_SG_REL_ EBS SG_ 2565866755 TransmissionCurrentGear_ISig_1 600;
BA_REL_ "GenSigFirstTimeoutTime" BU_SG_REL_ ECM SG_ 2565866755 TransmissionActualGearRatio_ISig 3000;
BA_REL_ "GenSigTimeoutTime" BU_SG_REL_ ECM SG_ 2565866755 TransmissionActualGearRatio_ISig 600;
BA_REL_ "GenSigFirstTimeoutTime" BU_SG_REL_ VCM SG_ 2565866755 TransmissionActualGearRatio_ISig 3000;
BA_REL_ "GenSigTimeoutTime" BU_SG_REL_ VCM SG_ 2565866755 TransmissionActualGearRatio_ISig 600;
BA_REL_ "GenSigFirstTimeoutTime" BU_SG_REL_ VCM SG_ 2565866755 TransmissionRangeAttained_ISig_1 3000;
BA_REL_ "GenSigTimeoutTime" BU_SG_REL_ VCM SG_ 2565866755 TransmissionRangeAttained_ISig_1 600;
BA_REL_ "GenSigFirstTimeoutTime" BU_SG_REL_ ECM SG_ 2364539395 TransmissionShiftInProcess 3000;
BA_REL_ "GenSigTimeoutTime" BU_SG_REL_ ECM SG_ 2364539395 TransmissionShiftInProcess 60;
BA_REL_ "GenSigFirstTimeoutTime" BU_SG_REL_ VCM SG_ 2364539395 TransmissionShiftInProcess 3000;
BA_REL_ "GenSigTimeoutTime" BU_SG_REL_ VCM SG_ 2364539395 TransmissionShiftInProcess 60;
BA_REL_ "GenSigFirstTimeoutTime" BU_SG_REL_ EBS SG_ 2364539395 TransmissionShiftInProcess 3000;
BA_REL_ "GenSigTimeoutTime" BU_SG_REL_ EBS SG_ 2364539395 TransmissionShiftInProcess 60;
BA_REL_ "GenSigFirstTimeoutTime" BU_SG_REL_ VCM SG_ 2364539395 TransmissionOutputShaftSpeed2 3000;
BA_REL_ "GenSigTimeoutTime" BU_SG_REL_ VCM SG_ 2364539395 TransmissionOutputShaftSpeed2 60;
BA_REL_ "GenSigFirstTimeoutTime" BU_SG_REL_ EBS SG_ 2364539395 TransmissionInputShaftSpeed 3000;
BA_REL_ "GenSigTimeoutTime" BU_SG_REL_ EBS SG_ 2364539395 TransmissionInputShaftSpeed 60;
BA_REL_ "GenSigFirstTimeoutTime" BU_SG_REL_ VCM SG_ 2364539395 TransmissionInputShaftSpeed 3000;
BA_REL_ "GenSigTimeoutTime" BU_SG_REL_ VCM SG_ 2364539395 TransmissionInputShaftSpeed 60;
BA_REL_ "GenSigFirstTimeoutTime" BU_SG_REL_ VCM SG_ 2364539395 TransmissionDrivelineEngaged_ISi 3000;
BA_REL_ "GenSigTimeoutTime" BU_SG_REL_ VCM SG_ 2364539395 TransmissionDrivelineEngaged_ISi 60;
BA_REL_ "GenSigFirstTimeoutTime" BU_SG_REL_ ECM SG_ 2364539395 TransmissionDrivelineEngaged_ISi 3000;
BA_REL_ "GenSigTimeoutTime" BU_SG_REL_ ECM SG_ 2364539395 TransmissionDrivelineEngaged_ISi 60;
BA_REL_ "GenSigFirstTimeoutTime" BU_SG_REL_ EBS SG_ 2364539395 TransmissionDrivelineEngaged_ISi 3000;
BA_REL_ "GenSigTimeoutTime" BU_SG_REL_ EBS SG_ 2364539395 TransmissionDrivelineEngaged_ISi 60;
BA_REL_ "GenSigFirstTimeoutTime" BU_SG_REL_ VCM SG_ 2364539395 MomentaryEngineOverspeedEnable 3000;
BA_REL_ "GenSigTimeoutTime" BU_SG_REL_ VCM SG_ 2364539395 MomentaryEngineOverspeedEnable 60;
BA_REL_ "GenSigFirstTimeoutTime" BU_SG_REL_ ECM SG_ 2364539395 MomentaryEngineOverspeedEnable 3000;
BA_REL_ "GenSigTimeoutTime" BU_SG_REL_ ECM SG_ 2364539395 MomentaryEngineOverspeedEnable 60;
BA_REL_ "GenSigFirstTimeoutTime" BU_SG_REL_ ECM SG_ 2364539395 PercentClutchSlip 3000;
BA_REL_ "GenSigTimeoutTime" BU_SG_REL_ ECM SG_ 2364539395 PercentClutchSlip 60;
BA_REL_ "GenSigFirstTimeoutTime" BU_SG_REL_ VCM SG_ 2364539395 PercentClutchSlip 3000;
BA_REL_ "GenSigTimeoutTime" BU_SG_REL_ VCM SG_ 2364539395 PercentClutchSlip 60;
BA_REL_ "GenSigFirstTimeoutTime" BU_SG_REL_ EBS SG_ 2364539395 PercentClutchSlip 3000;
BA_REL_ "GenSigTimeoutTime" BU_SG_REL_ EBS SG_ 2364539395 PercentClutchSlip 60;
BA_REL_ "GenSigFirstTimeoutTime" BU_SG_REL_ ECM SG_ 2364539395 TransmTrqConvrtrLockupEngd 3000;
BA_REL_ "GenSigTimeoutTime" BU_SG_REL_ ECM SG_ 2364539395 TransmTrqConvrtrLockupEngd 60;
BA_REL_ "GenSigFirstTimeoutTime" BU_SG_REL_ VCM SG_ 2364539395 TransmTrqConvrtrLockupEngd 3000;
BA_REL_ "GenSigTimeoutTime" BU_SG_REL_ VCM SG_ 2364539395 TransmTrqConvrtrLockupEngd 60;
BA_REL_ "GenSigFirstTimeoutTime" BU_SG_REL_ VCM SG_ 2566843904 EngineCoolantTemp_stat_ISig_1 24000;
BA_REL_ "GenSigTimeoutTime" BU_SG_REL_ VCM SG_ 2566843904 EngineCoolantTemp_stat_ISig_1 6000;
BA_REL_ "GenSigFirstTimeoutTime" BU_SG_REL_ ACM SG_ 2566843904 EngineCoolantTemp_stat_ISig_1 24000;
BA_REL_ "GenSigTimeoutTime" BU_SG_REL_ ACM SG_ 2566843904 EngineCoolantTemp_stat_ISig_1 6000;
BA_REL_ "GenSigFirstTimeoutTime" BU_SG_REL_ TCM SG_ 2566843904 EngineCoolantTemp_stat_ISig_1 24000;
BA_REL_ "GenSigTimeoutTime" BU_SG_REL_ TCM SG_ 2566843904 EngineCoolantTemp_stat_ISig_1 6000;
BA_REL_ "GenSigFirstTimeoutTime" BU_SG_REL_ TCM SG_ 2566843904 EngineOilTemperature 24000;
BA_REL_ "GenSigTimeoutTime" BU_SG_REL_ TCM SG_ 2566843904 EngineOilTemperature 6000;
BA_REL_ "GenSigFirstTimeoutTime" BU_SG_REL_ VCM SG_ 2566843904 EngineOilTemperature 24000;
BA_REL_ "GenSigTimeoutTime" BU_SG_REL_ VCM SG_ 2566843904 EngineOilTemperature 6000;
BA_REL_ "GenSigFirstTimeoutTime" BU_SG_REL_ ECM SG_ 2565865488 ActualMaxAvailDrvlnRetPrctTrq 3000;
BA_REL_ "GenSigTimeoutTime" BU_SG_REL_ ECM SG_ 2565865488 ActualMaxAvailDrvlnRetPrctTrq 600;
BA_REL_ "GenSigFirstTimeoutTime" BU_SG_REL_ TCM SG_ 2565865488 ActualMaxAvailDrvlnRetPrctTrq 3000;
BA_REL_ "GenSigTimeoutTime" BU_SG_REL_ TCM SG_ 2565865488 ActualMaxAvailDrvlnRetPrctTrq 600;
BA_REL_ "GenSigFirstTimeoutTime" BU_SG_REL_ VCM SG_ 2565865488 ActualMaxAvailDrvlnRetPrctTrq 3000;
BA_REL_ "GenSigTimeoutTime" BU_SG_REL_ VCM SG_ 2565865488 ActualMaxAvailDrvlnRetPrctTrq 600;
BA_REL_ "GenSigFirstTimeoutTime" BU_SG_REL_ EBS SG_ 2565865488 ActualMaxAvailDrvlnRetPrctTrq 3000;
BA_REL_ "GenSigTimeoutTime" BU_SG_REL_ EBS SG_ 2565865488 ActualMaxAvailDrvlnRetPrctTrq 600;
BA_REL_ "GenSigFirstTimeoutTime" BU_SG_REL_ ECM SG_ 2565865488 RetarderTorqueMode 3000;
BA_REL_ "GenSigTimeoutTime" BU_SG_REL_ ECM SG_ 2565865488 RetarderTorqueMode 600;
BA_REL_ "GenSigFirstTimeoutTime" BU_SG_REL_ VCM SG_ 2565865488 RetarderTorqueMode 3000;
BA_REL_ "GenSigTimeoutTime" BU_SG_REL_ VCM SG_ 2565865488 RetarderTorqueMode 600;
BA_REL_ "GenSigFirstTimeoutTime" BU_SG_REL_ EBS SG_ 2565865488 ActualDrvlnRetdrPercentTorque_IS 3000;
BA_REL_ "GenSigTimeoutTime" BU_SG_REL_ EBS SG_ 2565865488 ActualDrvlnRetdrPercentTorque_IS 600;
BA_REL_ "GenSigFirstTimeoutTime" BU_SG_REL_ VCM SG_ 2565865488 ActualDrvlnRetdrPercentTorque_IS 3000;
BA_REL_ "GenSigTimeoutTime" BU_SG_REL_ VCM SG_ 2565865488 ActualDrvlnRetdrPercentTorque_IS 600;
BA_REL_ "GenSigFirstTimeoutTime" BU_SG_REL_ ECM SG_ 2565865488 ActualDrvlnRetdrPercentTorque_IS 3000;
BA_REL_ "GenSigTimeoutTime" BU_SG_REL_ ECM SG_ 2565865488 ActualDrvlnRetdrPercentTorque_IS 600;
BA_REL_ "GenSigFirstTimeoutTime" BU_SG_REL_ TCM SG_ 2565865488 ActualDrvlnRetdrPercentTorque_IS 3000;
BA_REL_ "GenSigTimeoutTime" BU_SG_REL_ TCM SG_ 2565865488 ActualDrvlnRetdrPercentTorque_IS 600;
BA_REL_ "GenSigFirstTimeoutTime" BU_SG_REL_ VCM SG_ 2565865488 EngineCoolantLoadIncrease 3000;
BA_REL_ "GenSigTimeoutTime" BU_SG_REL_ VCM SG_ 2565865488 EngineCoolantLoadIncrease 600;
BA_REL_ "GenSigFirstTimeoutTime" BU_SG_REL_ ECM SG_ 2565865488 EngineCoolantLoadIncrease 3000;
BA_REL_ "GenSigTimeoutTime" BU_SG_REL_ ECM SG_ 2565865488 EngineCoolantLoadIncrease 600;
BA_REL_ "GenSigFirstTimeoutTime" BU_SG_REL_ VCM SG_ 2565865487 ActlMaxAvailEngRetdrPercentTrq 3000;
BA_REL_ "GenSigTimeoutTime" BU_SG_REL_ VCM SG_ 2565865487 ActlMaxAvailEngRetdrPercentTrq 600;
BA_REL_ "GenSigFirstTimeoutTime" BU_SG_REL_ EBS SG_ 2565865487 ActlMaxAvailEngRetdrPercentTrq 3000;
BA_REL_ "GenSigTimeoutTime" BU_SG_REL_ EBS SG_ 2565865487 ActlMaxAvailEngRetdrPercentTrq 600;
BA_REL_ "GenSigFirstTimeoutTime" BU_SG_REL_ VCM SG_ 2565865487 EngRetdrEnableBrakeAssistSw 3000;
BA_REL_ "GenSigTimeoutTime" BU_SG_REL_ VCM SG_ 2565865487 EngRetdrEnableBrakeAssistSw 600;
BA_REL_ "GenSigFirstTimeoutTime" BU_SG_REL_ TCM SG_ 2565865487 EngRetdrEnableBrakeAssistSw 3000;
BA_REL_ "GenSigTimeoutTime" BU_SG_REL_ TCM SG_ 2565865487 EngRetdrEnableBrakeAssistSw 600;
BA_REL_ "GenSigFirstTimeoutTime" BU_SG_REL_ VCM SG_ 2565865487 EngineRetarderTorqueMode 3000;
BA_REL_ "GenSigTimeoutTime" BU_SG_REL_ VCM SG_ 2565865487 EngineRetarderTorqueMode 600;
BA_REL_ "GenSigFirstTimeoutTime" BU_SG_REL_ EBS SG_ 2565865487 ActualEngineRetarderPercentTrq_I 3000;
BA_REL_ "GenSigTimeoutTime" BU_SG_REL_ EBS SG_ 2565865487 ActualEngineRetarderPercentTrq_I 600;
BA_REL_ "GenSigFirstTimeoutTime" BU_SG_REL_ TCM SG_ 2565865487 ActualEngineRetarderPercentTrq_I 3000;
BA_REL_ "GenSigTimeoutTime" BU_SG_REL_ TCM SG_ 2565865487 ActualEngineRetarderPercentTrq_I 600;
BA_REL_ "GenSigFirstTimeoutTime" BU_SG_REL_ VCM SG_ 2565865487 ActualEngineRetarderPercentTrq_I 3000;
BA_REL_ "GenSigTimeoutTime" BU_SG_REL_ VCM SG_ 2565865487 ActualEngineRetarderPercentTrq_I 600;
BA_REL_ "GenSigFirstTimeoutTime" BU_SG_REL_ ACM SG_ 2565865487 ActualEngineRetarderPercentTrq_I 3000;
BA_REL_ "GenSigTimeoutTime" BU_SG_REL_ ACM SG_ 2565865487 ActualEngineRetarderPercentTrq_I 600;
BA_REL_ "GenSigFirstTimeoutTime" BU_SG_REL_ TCM SG_ 2565865487 RetarderEnableShiftAssistSw 3000;
BA_REL_ "GenSigTimeoutTime" BU_SG_REL_ TCM SG_ 2565865487 RetarderEnableShiftAssistSw 600;
BA_REL_ "GenSigFirstTimeoutTime" BU_SG_REL_ VCM SG_ 2565865487 RetarderEnableShiftAssistSw 3000;
BA_REL_ "GenSigTimeoutTime" BU_SG_REL_ VCM SG_ 2565865487 RetarderEnableShiftAssistSw 600;
BA_REL_ "GenSigFirstTimeoutTime" BU_SG_REL_ TCM SG_ 2566864640 EngineActiveStatus_ISig_1 3000;
BA_REL_ "GenSigTimeoutTime" BU_SG_REL_ TCM SG_ 2566864640 EngineActiveStatus_ISig_1 600;
BA_REL_ "GenSigFirstTimeoutTime" BU_SG_REL_ EBS SG_ 2566864640 EngineActiveStatus_ISig_1 3000;
BA_REL_ "GenSigTimeoutTime" BU_SG_REL_ EBS SG_ 2566864640 EngineActiveStatus_ISig_1 600;
BA_REL_ "GenSigFirstTimeoutTime" BU_SG_REL_ VCM SG_ 2566864640 EngineActiveStatus_ISig_1 3000;
BA_REL_ "GenSigTimeoutTime" BU_SG_REL_ VCM SG_ 2566864640 EngineActiveStatus_ISig_1 600;
BA_REL_ "GenSigFirstTimeoutTime" BU_SG_REL_ VCM SG_ 2566864640 DrvrDemandEngRetdrPercentTrq 3000;
BA_REL_ "GenSigTimeoutTime" BU_SG_REL_ VCM SG_ 2566864640 DrvrDemandEngRetdrPercentTrq 600;
BA_REL_ "GenSigFirstTimeoutTime" BU_SG_REL_ EBS SG_ 2566864640 DrvrDemandEngRetdrPercentTrq 3000;
BA_REL_ "GenSigTimeoutTime" BU_SG_REL_ EBS SG_ 2566864640 DrvrDemandEngRetdrPercentTrq 600;
BA_REL_ "GenSigFirstTimeoutTime" BU_SG_REL_ VCM SG_ 2364541440 EngineIntakeAirRate 12000;
BA_REL_ "GenSigTimeoutTime" BU_SG_REL_ VCM SG_ 2364541440 EngineIntakeAirRate 3000;
BA_REL_ "GenSigFirstTimeoutTime" BU_SG_REL_ VCM SG_ 2566844160 EngineOilPressure 12000;
BA_REL_ "GenSigTimeoutTime" BU_SG_REL_ VCM SG_ 2566844160 EngineOilPressure 3000;
BA_REL_ "GenSigFirstTimeoutTime" BU_SG_REL_ VCM SG_ 2566844160 EngineOilLevel 12000;
BA_REL_ "GenSigTimeoutTime" BU_SG_REL_ VCM SG_ 2566844160 EngineOilLevel 3000;
BA_REL_ "GenSigFirstTimeoutTime" BU_SG_REL_ ACM SG_ 2566840064 NominalFrictionPercentTorque_ISi 6000;
BA_REL_ "GenSigTimeoutTime" BU_SG_REL_ ACM SG_ 2566840064 NominalFrictionPercentTorque_ISi 1500;
BA_REL_ "GenSigFirstTimeoutTime" BU_SG_REL_ TCM SG_ 2566840064 NominalFrictionPercentTorque_ISi 6000;
BA_REL_ "GenSigTimeoutTime" BU_SG_REL_ TCM SG_ 2566840064 NominalFrictionPercentTorque_ISi 1500;
BA_REL_ "GenSigFirstTimeoutTime" BU_SG_REL_ VCM SG_ 2566840064 NominalFrictionPercentTorque_ISi 6000;
BA_REL_ "GenSigTimeoutTime" BU_SG_REL_ VCM SG_ 2566840064 NominalFrictionPercentTorque_ISi 1500;
BA_REL_ "GenSigFirstTimeoutTime" BU_SG_REL_ EBS SG_ 2566840064 NominalFrictionPercentTorque_ISi 6000;
BA_REL_ "GenSigTimeoutTime" BU_SG_REL_ EBS SG_ 2566840064 NominalFrictionPercentTorque_ISi 1500;
BA_REL_ "GenSigFirstTimeoutTime" BU_SG_REL_ TCM SG_ 2364539648 RoadSpeedLimitStatus 3000;
BA_REL_ "GenSigTimeoutTime" BU_SG_REL_ TCM SG_ 2364539648 RoadSpeedLimitStatus 300;
BA_REL_ "GenSigFirstTimeoutTime" BU_SG_REL_ VCM SG_ 2364539648 RoadSpeedLimitStatus 3000;
BA_REL_ "GenSigTimeoutTime" BU_SG_REL_ VCM SG_ 2364539648 RoadSpeedLimitStatus 300;
BA_REL_ "GenSigFirstTimeoutTime" BU_SG_REL_ TCM SG_ 2364539648 AcceleratorPedalPosition1_2 3000;
BA_REL_ "GenSigTimeoutTime" BU_SG_REL_ TCM SG_ 2364539648 AcceleratorPedalPosition1_2 300;
BA_REL_ "GenSigFirstTimeoutTime" BU_SG_REL_ VCM SG_ 2364539648 AcceleratorPedalPosition1_2 3000;
BA_REL_ "GenSigTimeoutTime" BU_SG_REL_ VCM SG_ 2364539648 AcceleratorPedalPosition1_2 300;
BA_REL_ "GenSigFirstTimeoutTime" BU_SG_REL_ TCM SG_ 2364539648 EnginePercentLoadAtCurrentSpd 3000;
BA_REL_ "GenSigTimeoutTime" BU_SG_REL_ TCM SG_ 2364539648 EnginePercentLoadAtCurrentSpd 300;
BA_REL_ "GenSigFirstTimeoutTime" BU_SG_REL_ ACM SG_ 2364539648 EnginePercentLoadAtCurrentSpd 3000;
BA_REL_ "GenSigTimeoutTime" BU_SG_REL_ ACM SG_ 2364539648 EnginePercentLoadAtCurrentSpd 300;
BA_REL_ "GenSigFirstTimeoutTime" BU_SG_REL_ VCM SG_ 2364539648 EnginePercentLoadAtCurrentSpd 3000;
BA_REL_ "GenSigTimeoutTime" BU_SG_REL_ VCM SG_ 2364539648 EnginePercentLoadAtCurrentSpd 300;
BA_REL_ "GenSigFirstTimeoutTime" BU_SG_REL_ VCM SG_ 2364539904 EngineSpeed_ISig_1 3000;
BA_REL_ "GenSigTimeoutTime" BU_SG_REL_ VCM SG_ 2364539904 EngineSpeed_ISig_1 120;
BA_REL_ "GenSigFirstTimeoutTime" BU_SG_REL_ ACM SG_ 2364539904 EngineSpeed_ISig_1 3000;
BA_REL_ "GenSigTimeoutTime" BU_SG_REL_ ACM SG_ 2364539904 EngineSpeed_ISig_1 120;
BA_REL_ "GenSigFirstTimeoutTime" BU_SG_REL_ TCM SG_ 2364539904 EngineSpeed_ISig_1 3000;
BA_REL_ "GenSigTimeoutTime" BU_SG_REL_ TCM SG_ 2364539904 EngineSpeed_ISig_1 120;
BA_REL_ "GenSigFirstTimeoutTime" BU_SG_REL_ EBS SG_ 2364539904 EngineSpeed_ISig_1 3000;
BA_REL_ "GenSigTimeoutTime" BU_SG_REL_ EBS SG_ 2364539904 EngineSpeed_ISig_1 120;
BA_REL_ "GenSigFirstTimeoutTime" BU_SG_REL_ VCM SG_ 2364539904 DrvrDemandEngPercentTorque 3000;
BA_REL_ "GenSigTimeoutTime" BU_SG_REL_ VCM SG_ 2364539904 DrvrDemandEngPercentTorque 120;
BA_REL_ "GenSigFirstTimeoutTime" BU_SG_REL_ TCM SG_ 2364539904 DrvrDemandEngPercentTorque 3000;
BA_REL_ "GenSigTimeoutTime" BU_SG_REL_ TCM SG_ 2364539904 DrvrDemandEngPercentTorque 120;
BA_REL_ "GenSigFirstTimeoutTime" BU_SG_REL_ EBS SG_ 2364539904 DrvrDemandEngPercentTorque 3000;
BA_REL_ "GenSigTimeoutTime" BU_SG_REL_ EBS SG_ 2364539904 DrvrDemandEngPercentTorque 120;
BA_REL_ "GenSigFirstTimeoutTime" BU_SG_REL_ TCM SG_ 2364539904 ActualEnginePercentTorque_ISig_1 3000;
BA_REL_ "GenSigTimeoutTime" BU_SG_REL_ TCM SG_ 2364539904 ActualEnginePercentTorque_ISig_1 120;
BA_REL_ "GenSigFirstTimeoutTime" BU_SG_REL_ EBS SG_ 2364539904 ActualEnginePercentTorque_ISig_1 3000;
BA_REL_ "GenSigTimeoutTime" BU_SG_REL_ EBS SG_ 2364539904 ActualEnginePercentTorque_ISig_1 120;
BA_REL_ "GenSigFirstTimeoutTime" BU_SG_REL_ VCM SG_ 2364539904 ActualEnginePercentTorque_ISig_1 3000;
BA_REL_ "GenSigTimeoutTime" BU_SG_REL_ VCM SG_ 2364539904 ActualEnginePercentTorque_ISig_1 120;
BA_REL_ "GenSigFirstTimeoutTime" BU_SG_REL_ VCM SG_ 2364539904 EngineStarterMode_ISig_1 3000;
BA_REL_ "GenSigTimeoutTime" BU_SG_REL_ VCM SG_ 2364539904 EngineStarterMode_ISig_1 120;
BA_REL_ "GenSigFirstTimeoutTime" BU_SG_REL_ TCM SG_ 2364539904 EngineTorqueMode 3000;
BA_REL_ "GenSigTimeoutTime" BU_SG_REL_ TCM SG_ 2364539904 EngineTorqueMode 120;
BA_REL_ "GenSigFirstTimeoutTime" BU_SG_REL_ EBS SG_ 2364539904 EngineTorqueMode 3000;
BA_REL_ "GenSigTimeoutTime" BU_SG_REL_ EBS SG_ 2364539904 EngineTorqueMode 120;
BA_REL_ "GenSigFirstTimeoutTime" BU_SG_REL_ VCM SG_ 2364539904 EngineTorqueMode 3000;
BA_REL_ "GenSigTimeoutTime" BU_SG_REL_ VCM SG_ 2364539904 EngineTorqueMode 120;
BA_REL_ "GenSigFirstTimeoutTime" BU_SG_REL_ VCM SG_ 2364539904 EngineDemandPercentTorque 3000;
BA_REL_ "GenSigTimeoutTime" BU_SG_REL_ VCM SG_ 2364539904 EngineDemandPercentTorque 120;
BA_REL_ "GenSigFirstTimeoutTime" BU_SG_REL_ TCM SG_ 2364539904 EngineDemandPercentTorque 3000;
BA_REL_ "GenSigTimeoutTime" BU_SG_REL_ TCM SG_ 2364539904 EngineDemandPercentTorque 120;
BA_REL_ "GenSigFirstTimeoutTime" BU_SG_REL_ VCM SG_ 2566841088 EngConf_EngSpeedAt_P3 65000;
BA_REL_ "GenSigTimeoutTime" BU_SG_REL_ VCM SG_ 2566841088 EngConf_EngSpeedAt_P3 30000;
BA_REL_ "GenSigFirstTimeoutTime" BU_SG_REL_ TCM SG_ 2566841088 EngConf_EngSpeedAt_P3 65000;
BA_REL_ "GenSigTimeoutTime" BU_SG_REL_ TCM SG_ 2566841088 EngConf_EngSpeedAt_P3 30000;
BA_REL_ "GenSigFirstTimeoutTime" BU_SG_REL_ EBS SG_ 2566841088 EngConf_EngSpeedAt_P3 65000;
BA_REL_ "GenSigTimeoutTime" BU_SG_REL_ EBS SG_ 2566841088 EngConf_EngSpeedAt_P3 30000;
BA_REL_ "GenSigFirstTimeoutTime" BU_SG_REL_ EBS SG_ 2566841088 EngConf_EngSpeedAtIdle_P1 65000;
BA_REL_ "GenSigTimeoutTime" BU_SG_REL_ EBS SG_ 2566841088 EngConf_EngSpeedAtIdle_P1 30000;
BA_REL_ "GenSigFirstTimeoutTime" BU_SG_REL_ VCM SG_ 2566841088 EngConf_EngSpeedAtIdle_P1 65000;
BA_REL_ "GenSigTimeoutTime" BU_SG_REL_ VCM SG_ 2566841088 EngConf_EngSpeedAtIdle_P1 30000;
BA_REL_ "GenSigFirstTimeoutTime" BU_SG_REL_ TCM SG_ 2566841088 EngConf_EngSpeedAtIdle_P1 65000;
BA_REL_ "GenSigTimeoutTime" BU_SG_REL_ TCM SG_ 2566841088 EngConf_EngSpeedAtIdle_P1 30000;
BA_REL_ "GenSigFirstTimeoutTime" BU_SG_REL_ VCM SG_ 2566841088 EngConf_EngTorqueAtIdle_P1 65000;
BA_REL_ "GenSigTimeoutTime" BU_SG_REL_ VCM SG_ 2566841088 EngConf_EngTorqueAtIdle_P1 30000;
BA_REL_ "GenSigFirstTimeoutTime" BU_SG_REL_ EBS SG_ 2566841088 EngConf_EngTorqueAtIdle_P1 65000;
BA_REL_ "GenSigTimeoutTime" BU_SG_REL_ EBS SG_ 2566841088 EngConf_EngTorqueAtIdle_P1 30000;
BA_REL_ "GenSigFirstTimeoutTime" BU_SG_REL_ TCM SG_ 2566841088 EngConf_EngTorqueAtIdle_P1 65000;
BA_REL_ "GenSigTimeoutTime" BU_SG_REL_ TCM SG_ 2566841088 EngConf_EngTorqueAtIdle_P1 30000;
BA_REL_ "GenSigFirstTimeoutTime" BU_SG_REL_ EBS SG_ 2566841088 EngConf_EngSpeedAt_P4 65000;
BA_REL_ "GenSigTimeoutTime" BU_SG_REL_ EBS SG_ 2566841088 EngConf_EngSpeedAt_P4 30000;
BA_REL_ "GenSigFirstTimeoutTime" BU_SG_REL_ VCM SG_ 2566841088 EngConf_EngSpeedAt_P4 65000;
BA_REL_ "GenSigTimeoutTime" BU_SG_REL_ VCM SG_ 2566841088 EngConf_EngSpeedAt_P4 30000;
BA_REL_ "GenSigFirstTimeoutTime" BU_SG_REL_ TCM SG_ 2566841088 EngConf_EngSpeedAt_P4 65000;
BA_REL_ "GenSigTimeoutTime" BU_SG_REL_ TCM SG_ 2566841088 EngConf_EngSpeedAt_P4 30000;
BA_REL_ "GenSigFirstTimeoutTime" BU_SG_REL_ VCM SG_ 2566841088 EngineReferenceTorque_ISig_1 65000;
BA_REL_ "GenSigTimeoutTime" BU_SG_REL_ VCM SG_ 2566841088 EngineReferenceTorque_ISig_1 30000;
BA_REL_ "GenSigFirstTimeoutTime" BU_SG_REL_ EBS SG_ 2566841088 EngineReferenceTorque_ISig_1 65000;
BA_REL_ "GenSigTimeoutTime" BU_SG_REL_ EBS SG_ 2566841088 EngineReferenceTorque_ISig_1 30000;
BA_REL_ "GenSigFirstTimeoutTime" BU_SG_REL_ TCM SG_ 2566841088 EngineReferenceTorque_ISig_1 65000;
BA_REL_ "GenSigTimeoutTime" BU_SG_REL_ TCM SG_ 2566841088 EngineReferenceTorque_ISig_1 30000;
BA_REL_ "GenSigFirstTimeoutTime" BU_SG_REL_ ACM SG_ 2566841088 EngineReferenceTorque_ISig_1 65000;
BA_REL_ "GenSigTimeoutTime" BU_SG_REL_ ACM SG_ 2566841088 EngineReferenceTorque_ISig_1 30000;
BA_REL_ "GenSigFirstTimeoutTime" BU_SG_REL_ EBS SG_ 2566841088 EngConf_EngTorqueAt_P5 65000;
BA_REL_ "GenSigTimeoutTime" BU_SG_REL_ EBS SG_ 2566841088 EngConf_EngTorqueAt_P5 30000;
BA_REL_ "GenSigFirstTimeoutTime" BU_SG_REL_ VCM SG_ 2566841088 EngConf_EngTorqueAt_P5 65000;
BA_REL_ "GenSigTimeoutTime" BU_SG_REL_ VCM SG_ 2566841088 EngConf_EngTorqueAt_P5 30000;
BA_REL_ "GenSigFirstTimeoutTime" BU_SG_REL_ TCM SG_ 2566841088 EngConf_EngTorqueAt_P5 65000;
BA_REL_ "GenSigTimeoutTime" BU_SG_REL_ TCM SG_ 2566841088 EngConf_EngTorqueAt_P5 30000;
BA_REL_ "GenSigFirstTimeoutTime" BU_SG_REL_ EBS SG_ 2566841088 EngConf_EngSpeedAtHighIdle_P6 65000;
BA_REL_ "GenSigTimeoutTime" BU_SG_REL_ EBS SG_ 2566841088 EngConf_EngSpeedAtHighIdle_P6 30000;
BA_REL_ "GenSigFirstTimeoutTime" BU_SG_REL_ VCM SG_ 2566841088 EngConf_EngSpeedAtHighIdle_P6 65000;
BA_REL_ "GenSigTimeoutTime" BU_SG_REL_ VCM SG_ 2566841088 EngConf_EngSpeedAtHighIdle_P6 30000;
BA_REL_ "GenSigFirstTimeoutTime" BU_SG_REL_ TCM SG_ 2566841088 EngConf_EngSpeedAtHighIdle_P6 65000;
BA_REL_ "GenSigTimeoutTime" BU_SG_REL_ TCM SG_ 2566841088 EngConf_EngSpeedAtHighIdle_P6 30000;
BA_REL_ "GenSigFirstTimeoutTime" BU_SG_REL_ VCM SG_ 2566841088 EngConf_EngTorqueAt_P3 65000;
BA_REL_ "GenSigTimeoutTime" BU_SG_REL_ VCM SG_ 2566841088 EngConf_EngTorqueAt_P3 30000;
BA_REL_ "GenSigFirstTimeoutTime" BU_SG_REL_ TCM SG_ 2566841088 EngConf_EngTorqueAt_P3 65000;
BA_REL_ "GenSigTimeoutTime" BU_SG_REL_ TCM SG_ 2566841088 EngConf_EngTorqueAt_P3 30000;
BA_REL_ "GenSigFirstTimeoutTime" BU_SG_REL_ EBS SG_ 2566841088 EngConf_EngTorqueAt_P3 65000;
BA_REL_ "GenSigTimeoutTime" BU_SG_REL_ EBS SG_ 2566841088 EngConf_EngTorqueAt_P3 30000;
BA_REL_ "GenSigFirstTimeoutTime" BU_SG_REL_ VCM SG_ 2566841088 EngConf_EngSpeedAt_P5 65000;
BA_REL_ "GenSigTimeoutTime" BU_SG_REL_ VCM SG_ 2566841088 EngConf_EngSpeedAt_P5 30000;
BA_REL_ "GenSigFirstTimeoutTime" BU_SG_REL_ EBS SG_ 2566841088 EngConf_EngSpeedAt_P5 65000;
BA_REL_ "GenSigTimeoutTime" BU_SG_REL_ EBS SG_ 2566841088 EngConf_EngSpeedAt_P5 30000;
BA_REL_ "GenSigFirstTimeoutTime" BU_SG_REL_ TCM SG_ 2566841088 EngConf_EngSpeedAt_P5 65000;
BA_REL_ "GenSigTimeoutTime" BU_SG_REL_ TCM SG_ 2566841088 EngConf_EngSpeedAt_P5 30000;
BA_REL_ "GenSigFirstTimeoutTime" BU_SG_REL_ VCM SG_ 2566841088 EngConf_EngMaxMomOvSpeed_P7 65000;
BA_REL_ "GenSigTimeoutTime" BU_SG_REL_ VCM SG_ 2566841088 EngConf_EngMaxMomOvSpeed_P7 30000;
BA_REL_ "GenSigFirstTimeoutTime" BU_SG_REL_ TCM SG_ 2566841088 EngConf_EngMaxMomOvSpeed_P7 65000;
BA_REL_ "GenSigTimeoutTime" BU_SG_REL_ TCM SG_ 2566841088 EngConf_EngMaxMomOvSpeed_P7 30000;
BA_REL_ "GenSigFirstTimeoutTime" BU_SG_REL_ EBS SG_ 2566841088 EngConf_EngMaxMomOvSpeed_P7 65000;
BA_REL_ "GenSigTimeoutTime" BU_SG_REL_ EBS SG_ 2566841088 EngConf_EngMaxMomOvSpeed_P7 30000;
BA_REL_ "GenSigFirstTimeoutTime" BU_SG_REL_ EBS SG_ 2566841088 EngConf_EngTorqueAt_P4 65000;
BA_REL_ "GenSigTimeoutTime" BU_SG_REL_ EBS SG_ 2566841088 EngConf_EngTorqueAt_P4 30000;
BA_REL_ "GenSigFirstTimeoutTime" BU_SG_REL_ VCM SG_ 2566841088 EngConf_EngTorqueAt_P4 65000;
BA_REL_ "GenSigTimeoutTime" BU_SG_REL_ VCM SG_ 2566841088 EngConf_EngTorqueAt_P4 30000;
BA_REL_ "GenSigFirstTimeoutTime" BU_SG_REL_ TCM SG_ 2566841088 EngConf_EngTorqueAt_P4 65000;
BA_REL_ "GenSigTimeoutTime" BU_SG_REL_ TCM SG_ 2566841088 EngConf_EngTorqueAt_P4 30000;
BA_REL_ "GenSigFirstTimeoutTime" BU_SG_REL_ TCM SG_ 2566841088 EngConf_EngTorqueAt_P2 65000;
BA_REL_ "GenSigTimeoutTime" BU_SG_REL_ TCM SG_ 2566841088 EngConf_EngTorqueAt_P2 30000;
BA_REL_ "GenSigFirstTimeoutTime" BU_SG_REL_ VCM SG_ 2566841088 EngConf_EngTorqueAt_P2 65000;
BA_REL_ "GenSigTimeoutTime" BU_SG_REL_ VCM SG_ 2566841088 EngConf_EngTorqueAt_P2 30000;
BA_REL_ "GenSigFirstTimeoutTime" BU_SG_REL_ EBS SG_ 2566841088 EngConf_EngTorqueAt_P2 65000;
BA_REL_ "GenSigTimeoutTime" BU_SG_REL_ EBS SG_ 2566841088 EngConf_EngTorqueAt_P2 30000;
BA_REL_ "GenSigFirstTimeoutTime" BU_SG_REL_ EBS SG_ 2566841088 EngConf_EngSpeedAt_P2 65000;
BA_REL_ "GenSigTimeoutTime" BU_SG_REL_ EBS SG_ 2566841088 EngConf_EngSpeedAt_P2 30000;
BA_REL_ "GenSigFirstTimeoutTime" BU_SG_REL_ VCM SG_ 2566841088 EngConf_EngSpeedAt_P2 65000;
BA_REL_ "GenSigTimeoutTime" BU_SG_REL_ VCM SG_ 2566841088 EngConf_EngSpeedAt_P2 30000;
BA_REL_ "GenSigFirstTimeoutTime" BU_SG_REL_ TCM SG_ 2566841088 EngConf_EngSpeedAt_P2 65000;
BA_REL_ "GenSigTimeoutTime" BU_SG_REL_ TCM SG_ 2566841088 EngConf_EngSpeedAt_P2 30000;
BA_REL_ "GenSigFirstTimeoutTime" BU_SG_REL_ TCM SG_ 2566841088 EngConf_MaxMomOverrideTimeLim 65000;
BA_REL_ "GenSigTimeoutTime" BU_SG_REL_ TCM SG_ 2566841088 EngConf_MaxMomOverrideTimeLim 30000;
BA_REL_ "GenSigFirstTimeoutTime" BU_SG_REL_ EBS SG_ 2566841088 EngConf_MaxMomOverrideTimeLim 65000;
BA_REL_ "GenSigTimeoutTime" BU_SG_REL_ EBS SG_ 2566841088 EngConf_MaxMomOverrideTimeLim 30000;
BA_REL_ "GenSigFirstTimeoutTime" BU_SG_REL_ VCM SG_ 2566841088 EngConf_MaxMomOverrideTimeLim 65000;
BA_REL_ "GenSigTimeoutTime" BU_SG_REL_ VCM SG_ 2566841088 EngConf_MaxMomOverrideTimeLim 30000;
BA_REL_ "GenSigFirstTimeoutTime" BU_SG_REL_ VCM SG_ 2365554187 TagAxleLeftWheelSpeed 3000;
BA_REL_ "GenSigTimeoutTime" BU_SG_REL_ VCM SG_ 2365554187 TagAxleLeftWheelSpeed 120;
BA_REL_ "GenSigFirstTimeoutTime" BU_SG_REL_ VCM SG_ 2365554187 PusherAxleLeftWheelSpeed 3000;
BA_REL_ "GenSigTimeoutTime" BU_SG_REL_ VCM SG_ 2365554187 PusherAxleLeftWheelSpeed 120;
BA_REL_ "GenSigFirstTimeoutTime" BU_SG_REL_ VCM SG_ 2365554187 PusherAxleRightWheelSpeed 3000;
BA_REL_ "GenSigTimeoutTime" BU_SG_REL_ VCM SG_ 2365554187 PusherAxleRightWheelSpeed 120;
BA_REL_ "GenSigFirstTimeoutTime" BU_SG_REL_ VCM SG_ 2365554187 TagAxleRightWheelSpeed 3000;
BA_REL_ "GenSigTimeoutTime" BU_SG_REL_ VCM SG_ 2365554187 TagAxleRightWheelSpeed 120;
BA_REL_ "GenSigFirstTimeoutTime" BU_SG_REL_ ECM SG_ 2298445579 ThrdRrDriveAxLeftWheelSpeed_ISig 3000;
BA_REL_ "GenSigTimeoutTime" BU_SG_REL_ ECM SG_ 2298445579 ThrdRrDriveAxLeftWheelSpeed_ISig 120;
BA_REL_ "GenSigFirstTimeoutTime" BU_SG_REL_ TCM SG_ 2298445579 ThrdRrDriveAxLeftWheelSpeed_ISig 3000;
BA_REL_ "GenSigTimeoutTime" BU_SG_REL_ TCM SG_ 2298445579 ThrdRrDriveAxLeftWheelSpeed_ISig 120;
BA_REL_ "GenSigFirstTimeoutTime" BU_SG_REL_ VCM SG_ 2298445579 ThrdRrDriveAxLeftWheelSpeed_ISig 3000;
BA_REL_ "GenSigTimeoutTime" BU_SG_REL_ VCM SG_ 2298445579 ThrdRrDriveAxLeftWheelSpeed_ISig 120;
BA_REL_ "GenSigFirstTimeoutTime" BU_SG_REL_ ECM SG_ 2298445579 ThrdRrDriveAxRightWheelSpeed_ISi 3000;
BA_REL_ "GenSigTimeoutTime" BU_SG_REL_ ECM SG_ 2298445579 ThrdRrDriveAxRightWheelSpeed_ISi 120;
BA_REL_ "GenSigFirstTimeoutTime" BU_SG_REL_ VCM SG_ 2298445579 ThrdRrDriveAxRightWheelSpeed_ISi 3000;
BA_REL_ "GenSigTimeoutTime" BU_SG_REL_ VCM SG_ 2298445579 ThrdRrDriveAxRightWheelSpeed_ISi 120;
BA_REL_ "GenSigFirstTimeoutTime" BU_SG_REL_ TCM SG_ 2298445579 ThrdRrDriveAxRightWheelSpeed_ISi 3000;
BA_REL_ "GenSigTimeoutTime" BU_SG_REL_ TCM SG_ 2298445579 ThrdRrDriveAxRightWheelSpeed_ISi 120;
BA_REL_ "GenSigFirstTimeoutTime" BU_SG_REL_ VCM SG_ 2566852619 WheelCircumference_TireId 3000;
BA_REL_ "GenSigTimeoutTime" BU_SG_REL_ VCM SG_ 2566852619 WheelCircumference_TireId 600;
BA_REL_ "GenSigFirstTimeoutTime" BU_SG_REL_ VCM SG_ 2566852619 WheelCircumference_Value 3000;
BA_REL_ "GenSigTimeoutTime" BU_SG_REL_ VCM SG_ 2566852619 WheelCircumference_Value 600;
BA_REL_ "GenSigFirstTimeoutTime" BU_SG_REL_ VCM SG_ 2298422539 ActualPusherWheelAngle 3000;
BA_REL_ "GenSigTimeoutTime" BU_SG_REL_ VCM SG_ 2298422539 ActualPusherWheelAngle 120;
BA_REL_ "GenSigFirstTimeoutTime" BU_SG_REL_ VCM SG_ 2298422539 ActualTagWheelAngle 3000;
BA_REL_ "GenSigTimeoutTime" BU_SG_REL_ VCM SG_ 2298422539 ActualTagWheelAngle 120;
BA_REL_ "GenSigFirstTimeoutTime" BU_SG_REL_ ECM SG_ 2298422283 ScndFrAxleLeftWheelSpeed 3000;
BA_REL_ "GenSigTimeoutTime" BU_SG_REL_ ECM SG_ 2298422283 ScndFrAxleLeftWheelSpeed 120;
BA_REL_ "GenSigFirstTimeoutTime" BU_SG_REL_ TCM SG_ 2298422283 ScndFrAxleLeftWheelSpeed 3000;
BA_REL_ "GenSigTimeoutTime" BU_SG_REL_ TCM SG_ 2298422283 ScndFrAxleLeftWheelSpeed 120;
BA_REL_ "GenSigFirstTimeoutTime" BU_SG_REL_ VCM SG_ 2298422283 ScndFrAxleLeftWheelSpeed 3000;
BA_REL_ "GenSigTimeoutTime" BU_SG_REL_ VCM SG_ 2298422283 ScndFrAxleLeftWheelSpeed 120;
BA_REL_ "GenSigFirstTimeoutTime" BU_SG_REL_ VCM SG_ 2298422283 ScndRrDriveAxleRightWheelSpeed_I 3000;
BA_REL_ "GenSigTimeoutTime" BU_SG_REL_ VCM SG_ 2298422283 ScndRrDriveAxleRightWheelSpeed_I 120;
BA_REL_ "GenSigFirstTimeoutTime" BU_SG_REL_ TCM SG_ 2298422283 ScndRrDriveAxleRightWheelSpeed_I 3000;
BA_REL_ "GenSigTimeoutTime" BU_SG_REL_ TCM SG_ 2298422283 ScndRrDriveAxleRightWheelSpeed_I 120;
BA_REL_ "GenSigFirstTimeoutTime" BU_SG_REL_ ECM SG_ 2298422283 ScndRrDriveAxleRightWheelSpeed_I 3000;
BA_REL_ "GenSigTimeoutTime" BU_SG_REL_ ECM SG_ 2298422283 ScndRrDriveAxleRightWheelSpeed_I 120;
BA_REL_ "GenSigFirstTimeoutTime" BU_SG_REL_ VCM SG_ 2298422283 ScndFrAxleRightWheelSpeed 3000;
BA_REL_ "GenSigTimeoutTime" BU_SG_REL_ VCM SG_ 2298422283 ScndFrAxleRightWheelSpeed 120;
BA_REL_ "GenSigFirstTimeoutTime" BU_SG_REL_ ECM SG_ 2298422283 ScndFrAxleRightWheelSpeed 3000;
BA_REL_ "GenSigTimeoutTime" BU_SG_REL_ ECM SG_ 2298422283 ScndFrAxleRightWheelSpeed 120;
BA_REL_ "GenSigFirstTimeoutTime" BU_SG_REL_ TCM SG_ 2298422283 ScndFrAxleRightWheelSpeed 3000;
BA_REL_ "GenSigTimeoutTime" BU_SG_REL_ TCM SG_ 2298422283 ScndFrAxleRightWheelSpeed 120;
BA_REL_ "GenSigFirstTimeoutTime" BU_SG_REL_ VCM SG_ 2298422283 ScndRrDriveAxleLeftWheelSpeed_IS 3000;
BA_REL_ "GenSigTimeoutTime" BU_SG_REL_ VCM SG_ 2298422283 ScndRrDriveAxleLeftWheelSpeed_IS 120;
BA_REL_ "GenSigFirstTimeoutTime" BU_SG_REL_ ECM SG_ 2298422283 ScndRrDriveAxleLeftWheelSpeed_IS 3000;
BA_REL_ "GenSigTimeoutTime" BU_SG_REL_ ECM SG_ 2298422283 ScndRrDriveAxleLeftWheelSpeed_IS 120;
BA_REL_ "GenSigFirstTimeoutTime" BU_SG_REL_ TCM SG_ 2298422283 ScndRrDriveAxleLeftWheelSpeed_IS 3000;
BA_REL_ "GenSigTimeoutTime" BU_SG_REL_ TCM SG_ 2298422283 ScndRrDriveAxleLeftWheelSpeed_IS 120;
BA_REL_ "GenSigFirstTimeoutTime" BU_SG_REL_ VCM SG_ 2566911243 Trailer5EBSRedWarning 24000;
BA_REL_ "GenSigTimeoutTime" BU_SG_REL_ VCM SG_ 2566911243 Trailer5EBSRedWarning 6000;
BA_REL_ "GenSigFirstTimeoutTime" BU_SG_REL_ VCM SG_ 2566911243 Trailer5ExtLvlStorageSupport 24000;
BA_REL_ "GenSigTimeoutTime" BU_SG_REL_ VCM SG_ 2566911243 Trailer5ExtLvlStorageSupport 6000;
BA_REL_ "GenSigFirstTimeoutTime" BU_SG_REL_ VCM SG_ 2566911243 Trailer5PneumSupply_Pressure 24000;
BA_REL_ "GenSigTimeoutTime" BU_SG_REL_ VCM SG_ 2566911243 Trailer5PneumSupply_Pressure 6000;
BA_REL_ "GenSigFirstTimeoutTime" BU_SG_REL_ VCM SG_ 2566911243 Trailer5NomBodyLevel_FrontLevel 24000;
BA_REL_ "GenSigTimeoutTime" BU_SG_REL_ VCM SG_ 2566911243 Trailer5NomBodyLevel_FrontLevel 6000;
BA_REL_ "GenSigFirstTimeoutTime" BU_SG_REL_ VCM SG_ 2566911243 Trailer5LoadRampApprAssistStat 24000;
BA_REL_ "GenSigTimeoutTime" BU_SG_REL_ VCM SG_ 2566911243 Trailer5LoadRampApprAssistStat 6000;
BA_REL_ "GenSigFirstTimeoutTime" BU_SG_REL_ VCM SG_ 2566911243 Trailer5VehicleType 24000;
BA_REL_ "GenSigTimeoutTime" BU_SG_REL_ VCM SG_ 2566911243 Trailer5VehicleType 6000;
BA_REL_ "GenSigFirstTimeoutTime" BU_SG_REL_ VCM SG_ 2566911243 Trailer5EBSAmberWarning 24000;
BA_REL_ "GenSigTimeoutTime" BU_SG_REL_ VCM SG_ 2566911243 Trailer5EBSAmberWarning 6000;
BA_REL_ "GenSigFirstTimeoutTime" BU_SG_REL_ VCM SG_ 2566911243 Trailer5LevelControlStatus 24000;
BA_REL_ "GenSigTimeoutTime" BU_SG_REL_ VCM SG_ 2566911243 Trailer5LevelControlStatus 6000;
BA_REL_ "GenSigFirstTimeoutTime" BU_SG_REL_ VCM SG_ 2566911243 Trailer5PneumSupply_Status 24000;
BA_REL_ "GenSigTimeoutTime" BU_SG_REL_ VCM SG_ 2566911243 Trailer5PneumSupply_Status 6000;
BA_REL_ "GenSigFirstTimeoutTime" BU_SG_REL_ VCM SG_ 2566911243 Trailer5ROPSystemStatus 24000;
BA_REL_ "GenSigTimeoutTime" BU_SG_REL_ VCM SG_ 2566911243 Trailer5ROPSystemStatus 6000;
BA_REL_ "GenSigFirstTimeoutTime" BU_SG_REL_ VCM SG_ 2566911243 Trailer5NomBodyLevel_RearLevel 24000;
BA_REL_ "GenSigTimeoutTime" BU_SG_REL_ VCM SG_ 2566911243 Trailer5NomBodyLevel_RearLevel 6000;
BA_REL_ "GenSigFirstTimeoutTime" BU_SG_REL_ VCM SG_ 2566911243 Trailer5ElectricalSupplyStat 24000;
BA_REL_ "GenSigTimeoutTime" BU_SG_REL_ VCM SG_ 2566911243 Trailer5ElectricalSupplyStat 6000;
BA_REL_ "GenSigFirstTimeoutTime" BU_SG_REL_ VCM SG_ 2566911243 Trailer5YCSystemStatus 24000;
BA_REL_ "GenSigTimeoutTime" BU_SG_REL_ VCM SG_ 2566911243 Trailer5YCSystemStatus 6000;
BA_REL_ "GenSigFirstTimeoutTime" BU_SG_REL_ VCM SG_ 2566906891 Trailer4NomBodyLevel_RearLevel 24000;
BA_REL_ "GenSigTimeoutTime" BU_SG_REL_ VCM SG_ 2566906891 Trailer4NomBodyLevel_RearLevel 6000;
BA_REL_ "GenSigFirstTimeoutTime" BU_SG_REL_ VCM SG_ 2566906891 Trailer4LoadRampApprAssistStat 24000;
BA_REL_ "GenSigTimeoutTime" BU_SG_REL_ VCM SG_ 2566906891 Trailer4LoadRampApprAssistStat 6000;
BA_REL_ "GenSigFirstTimeoutTime" BU_SG_REL_ VCM SG_ 2566906891 Trailer4EBSRedWarning 24000;
BA_REL_ "GenSigTimeoutTime" BU_SG_REL_ VCM SG_ 2566906891 Trailer4EBSRedWarning 6000;
BA_REL_ "GenSigFirstTimeoutTime" BU_SG_REL_ VCM SG_ 2566906891 Trailer4EBSAmberWarning 24000;
BA_REL_ "GenSigTimeoutTime" BU_SG_REL_ VCM SG_ 2566906891 Trailer4EBSAmberWarning 6000;
BA_REL_ "GenSigFirstTimeoutTime" BU_SG_REL_ VCM SG_ 2566906891 Trailer4ExtLvlStorageSupport 24000;
BA_REL_ "GenSigTimeoutTime" BU_SG_REL_ VCM SG_ 2566906891 Trailer4ExtLvlStorageSupport 6000;
BA_REL_ "GenSigFirstTimeoutTime" BU_SG_REL_ VCM SG_ 2566906891 Trailer4VehicleType 24000;
BA_REL_ "GenSigTimeoutTime" BU_SG_REL_ VCM SG_ 2566906891 Trailer4VehicleType 6000;
BA_REL_ "GenSigFirstTimeoutTime" BU_SG_REL_ VCM SG_ 2566906891 Trailer4YCSystemStatus 24000;
BA_REL_ "GenSigTimeoutTime" BU_SG_REL_ VCM SG_ 2566906891 Trailer4YCSystemStatus 6000;
BA_REL_ "GenSigFirstTimeoutTime" BU_SG_REL_ VCM SG_ 2566906891 Trailer4PneumSupply_Pressure 24000;
BA_REL_ "GenSigTimeoutTime" BU_SG_REL_ VCM SG_ 2566906891 Trailer4PneumSupply_Pressure 6000;
BA_REL_ "GenSigFirstTimeoutTime" BU_SG_REL_ VCM SG_ 2566906891 Trailer4ElectricalSupplyStat 24000;
BA_REL_ "GenSigTimeoutTime" BU_SG_REL_ VCM SG_ 2566906891 Trailer4ElectricalSupplyStat 6000;
BA_REL_ "GenSigFirstTimeoutTime" BU_SG_REL_ VCM SG_ 2566906891 Trailer4LevelControlStatus 24000;
BA_REL_ "GenSigTimeoutTime" BU_SG_REL_ VCM SG_ 2566906891 Trailer4LevelControlStatus 6000;
BA_REL_ "GenSigFirstTimeoutTime" BU_SG_REL_ VCM SG_ 2566906891 Trailer4ROPSystemStatus 24000;
BA_REL_ "GenSigTimeoutTime" BU_SG_REL_ VCM SG_ 2566906891 Trailer4ROPSystemStatus 6000;
BA_REL_ "GenSigFirstTimeoutTime" BU_SG_REL_ VCM SG_ 2566906891 Trailer4NomBodyLevel_FrontLevel 24000;
BA_REL_ "GenSigTimeoutTime" BU_SG_REL_ VCM SG_ 2566906891 Trailer4NomBodyLevel_FrontLevel 6000;
BA_REL_ "GenSigFirstTimeoutTime" BU_SG_REL_ VCM SG_ 2566906891 Trailer4PneumSupply_Status 24000;
BA_REL_ "GenSigTimeoutTime" BU_SG_REL_ VCM SG_ 2566906891 Trailer4PneumSupply_Status 6000;
BA_REL_ "GenSigFirstTimeoutTime" BU_SG_REL_ VCM SG_ 2566902283 Trailer3NomBodyLevel_FrontLevel 24000;
BA_REL_ "GenSigTimeoutTime" BU_SG_REL_ VCM SG_ 2566902283 Trailer3NomBodyLevel_FrontLevel 6000;
BA_REL_ "GenSigFirstTimeoutTime" BU_SG_REL_ VCM SG_ 2566902283 Trailer3VehicleType 24000;
BA_REL_ "GenSigTimeoutTime" BU_SG_REL_ VCM SG_ 2566902283 Trailer3VehicleType 6000;
BA_REL_ "GenSigFirstTimeoutTime" BU_SG_REL_ VCM SG_ 2566902283 Trailer3PneumSupply_Status 24000;
BA_REL_ "GenSigTimeoutTime" BU_SG_REL_ VCM SG_ 2566902283 Trailer3PneumSupply_Status 6000;
BA_REL_ "GenSigFirstTimeoutTime" BU_SG_REL_ VCM SG_ 2566902283 Trailer3PneumSupply_Pressure 24000;
BA_REL_ "GenSigTimeoutTime" BU_SG_REL_ VCM SG_ 2566902283 Trailer3PneumSupply_Pressure 6000;
BA_REL_ "GenSigFirstTimeoutTime" BU_SG_REL_ VCM SG_ 2566902283 Trailer3ExtLvlStorageSupport 24000;
BA_REL_ "GenSigTimeoutTime" BU_SG_REL_ VCM SG_ 2566902283 Trailer3ExtLvlStorageSupport 6000;
BA_REL_ "GenSigFirstTimeoutTime" BU_SG_REL_ VCM SG_ 2566902283 Trailer3LoadRampApprAssistStat 24000;
BA_REL_ "GenSigTimeoutTime" BU_SG_REL_ VCM SG_ 2566902283 Trailer3LoadRampApprAssistStat 6000;
BA_REL_ "GenSigFirstTimeoutTime" BU_SG_REL_ VCM SG_ 2566902283 Trailer3ElectricalSupplyStat 24000;
BA_REL_ "GenSigTimeoutTime" BU_SG_REL_ VCM SG_ 2566902283 Trailer3ElectricalSupplyStat 6000;
BA_REL_ "GenSigFirstTimeoutTime" BU_SG_REL_ VCM SG_ 2566902283 Trailer3EBSRedWarning 24000;
BA_REL_ "GenSigTimeoutTime" BU_SG_REL_ VCM SG_ 2566902283 Trailer3EBSRedWarning 6000;
BA_REL_ "GenSigFirstTimeoutTime" BU_SG_REL_ VCM SG_ 2566902283 Trailer3ROPSystemStatus 24000;
BA_REL_ "GenSigTimeoutTime" BU_SG_REL_ VCM SG_ 2566902283 Trailer3ROPSystemStatus 6000;
BA_REL_ "GenSigFirstTimeoutTime" BU_SG_REL_ VCM SG_ 2566902283 Trailer3EBSAmberWarning 24000;
BA_REL_ "GenSigTimeoutTime" BU_SG_REL_ VCM SG_ 2566902283 Trailer3EBSAmberWarning 6000;
BA_REL_ "GenSigFirstTimeoutTime" BU_SG_REL_ VCM SG_ 2566902283 Trailer3LevelControlStatus 24000;
BA_REL_ "GenSigTimeoutTime" BU_SG_REL_ VCM SG_ 2566902283 Trailer3LevelControlStatus 6000;
BA_REL_ "GenSigFirstTimeoutTime" BU_SG_REL_ VCM SG_ 2566902283 Trailer3NomBodyLevel_RearLevel 24000;
BA_REL_ "GenSigTimeoutTime" BU_SG_REL_ VCM SG_ 2566902283 Trailer3NomBodyLevel_RearLevel 6000;
BA_REL_ "GenSigFirstTimeoutTime" BU_SG_REL_ VCM SG_ 2566902283 Trailer3YCSystemStatus 24000;
BA_REL_ "GenSigTimeoutTime" BU_SG_REL_ VCM SG_ 2566902283 Trailer3YCSystemStatus 6000;
VAL_ 2348814097 TSC1EMSrVMCU_EnRSpdCtrlC 3 "TSC1EngReqSpeedCtrlCond_StabilityOptDrvlnEngLockup2" 2 "TSC1EngReqSpeedCtrlCond_StabilityOptDrvlnEngLockup1" 1 "TSC1EngReqSpeedCtrlCond_StabilityOptDrvlnDisengNonLockup" 0 "TSC1EngReqSpeedCtrlCond_TransientOptimized" ;
VAL_ 2348814097 TSC1EMSrVMCU_OvrdCtrlMPr 3 "Priority_LowPriority" 2 "Priority_MediumPriority" 1 "Priority_HighPriority" 0 "Priority_HighestPriority" ;
VAL_ 2348814097 TSC1EMSrVMCU_EnOvrdCtrlM 3 "TSC1EngOverrideCtrlMode_SpeedTorqueLimitControl" 2 "TSC1EngOverrideCtrlMode_TorqueControl" 1 "TSC1EngOverrideCtrlMode_SpeedControl" 0 "TSC1EngOverrideCtrlMode_OverrideDisabled" ;
VAL_ 2348814083 TSC1EMSrTECU_EnOvrdCtrlM 3 "TSC1EngOverrideCtrlMode_SpeedTorqueLimitControl" 2 "TSC1EngOverrideCtrlMode_TorqueControl" 1 "TSC1EngOverrideCtrlMode_SpeedControl" 0 "TSC1EngOverrideCtrlMode_OverrideDisabled" ;
VAL_ 2348814083 TSC1EMSrTECU_EnRSpdCtrlC 3 "TSC1EngReqSpeedCtrlCond_StabilityOptDrvlnEngLockup2" 2 "TSC1EngReqSpeedCtrlCond_StabilityOptDrvlnEngLockup1" 1 "TSC1EngReqSpeedCtrlCond_StabilityOptDrvlnDisengNonLockup" 0 "TSC1EngReqSpeedCtrlCond_TransientOptimized" ;
VAL_ 2348814083 TSC1EMSrTECU_OvrdCtrlMPr 3 "Priority_LowPriority" 2 "Priority_MediumPriority" 1 "Priority_HighPriority" 0 "Priority_HighestPriority" ;
VAL_ 2348814091 TSC1EMSrABS_OvrdCtrlMPr 3 "Priority_LowPriority" 2 "Priority_MediumPriority" 1 "Priority_HighPriority" 0 "Priority_HighestPriority" ;
VAL_ 2348814091 TSC1EMSrABS_EnRSpdCtrlC 3 "TSC1EngReqSpeedCtrlCond_StabilityOptDrvlnEngLockup2" 2 "TSC1EngReqSpeedCtrlCond_StabilityOptDrvlnEngLockup1" 1 "TSC1EngReqSpeedCtrlCond_StabilityOptDrvlnDisengNonLockup" 0 "TSC1EngReqSpeedCtrlCond_TransientOptimized" ;
VAL_ 2348814091 TSC1EMSrABS_EnOvrdCtrlM 3 "TSC1EngOverrideCtrlMode_SpeedTorqueLimitControl" 2 "TSC1EngOverrideCtrlMode_TorqueControl" 1 "TSC1EngOverrideCtrlMode_SpeedControl" 0 "TSC1EngOverrideCtrlMode_OverrideDisabled" ;
VAL_ 2566882307 TransmEngineCrankEnable2_ISig_1 3 "DisableEnable_NotAvailable" 2 "DisableEnable_Error" 1 "DisableEnable_Enable" 0 "DisableEnable_Disable" ;
VAL_ 2566882307 PwtFunctionalitySt 7 "PwtFunctionalitySt_NotAvailable" 6 "PwtFunctionalitySt_Error" 5 "PwtFunctionalitySt_NotFullyOperational_Level_4" 4 "PwtFunctionalitySt_NotFullyOperational_Level_3" 3 "PwtFunctionalitySt_NotFullyOperational_Level_2" 2 "PwtFunctionalitySt_NotFullyOperational_Level_1" 1 "PwtFunctionalitySt_FullyOperational" 0 "PwtFunctionalitySt_NotSupported" ;
VAL_ 2566882307 LowTempClutchInfo_ISig_1 3 "Warning_NotAvailable" 2 "Warning_Error" 1 "Warning_Warning" 0 "Warning_NoWarning" ;
VAL_ 2566882307 PwtFunctionalitySt_FaultInfo 255 "Autonomous_PT_FaultMode_NotAvailable" 254 "Autonomous_PT_FaultMode_Error" 253 "Autonomous_PT_FaultMode_Spare198" 252 "Autonomous_PT_FaultMode_Spare197" 251 "Autonomous_PT_FaultMode_Spare196" 250 "Autonomous_PT_FaultMode_Spare195" 249 "Autonomous_PT_FaultMode_Spare194" 248 "Autonomous_PT_FaultMode_Spare193" 247 "Autonomous_PT_FaultMode_Spare192" 246 "Autonomous_PT_FaultMode_Spare191" 245 "Autonomous_PT_FaultMode_Spare190" 244 "Autonomous_PT_FaultMode_Spare189" 243 "Autonomous_PT_FaultMode_Spare188" 242 "Autonomous_PT_FaultMode_Spare187" 241 "Autonomous_PT_FaultMode_Spare186" 240 "Autonomous_PT_FaultMode_Spare185" 239 "Autonomous_PT_FaultMode_Spare184" 238 "Autonomous_PT_FaultMode_Spare183" 237 "Autonomous_PT_FaultMode_Spare182" 236 "Autonomous_PT_FaultMode_Spare181" 235 "Autonomous_PT_FaultMode_Spare180" 234 "Autonomous_PT_FaultMode_Spare179" 233 "Autonomous_PT_FaultMode_Spare178" 232 "Autonomous_PT_FaultMode_Spare177" 231 "Autonomous_PT_FaultMode_Spare176" 230 "Autonomous_PT_FaultMode_Spare175" 229 "Autonomous_PT_FaultMode_Spare174" 228 "Autonomous_PT_FaultMode_Spare173" 227 "Autonomous_PT_FaultMode_Spare172" 226 "Autonomous_PT_FaultMode_Spare171" 225 "Autonomous_PT_FaultMode_Spare170" 224 "Autonomous_PT_FaultMode_Spare169" 223 "Autonomous_PT_FaultMode_Spare168" 222 "Autonomous_PT_FaultMode_Spare167" 221 "Autonomous_PT_FaultMode_Spare166" 220 "Autonomous_PT_FaultMode_Spare165" 219 "Autonomous_PT_FaultMode_Spare164" 218 "Autonomous_PT_FaultMode_Spare163" 217 "Autonomous_PT_FaultMode_Spare162" 216 "Autonomous_PT_FaultMode_Spare161" 215 "Autonomous_PT_FaultMode_Spare160" 214 "Autonomous_PT_FaultMode_Spare159" 213 "Autonomous_PT_FaultMode_Spare158" 212 "Autonomous_PT_FaultMode_Spare157" 211 "Autonomous_PT_FaultMode_Spare156" 210 "Autonomous_PT_FaultMode_Spare155" 209 "Autonomous_PT_FaultMode_Spare154" 208 "Autonomous_PT_FaultMode_Spare153" 207 "Autonomous_PT_FaultMode_Spare152" 206 "Autonomous_PT_FaultMode_Spare151" 205 "Autonomous_PT_FaultMode_Spare150" 204 "Autonomous_PT_FaultMode_Spare149" 203 "Autonomous_PT_FaultMode_Spare148" 202 "Autonomous_PT_FaultMode_Spare147" 201 "Autonomous_PT_FaultMode_Spare146" 200 "Autonomous_PT_FaultMode_Spare145" 199 "Autonomous_PT_FaultMode_Spare144" 198 "Autonomous_PT_FaultMode_Spare143" 197 "Autonomous_PT_FaultMode_Spare142" 196 "Autonomous_PT_FaultMode_Spare141" 195 "Autonomous_PT_FaultMode_Spare140" 194 "Autonomous_PT_FaultMode_Spare139" 193 "Autonomous_PT_FaultMode_Spare138" 192 "Autonomous_PT_FaultMode_Spare137" 191 "Autonomous_PT_FaultMode_Spare136" 190 "Autonomous_PT_FaultMode_Spare135" 189 "Autonomous_PT_FaultMode_Spare134" 188 "Autonomous_PT_FaultMode_Spare133" 187 "Autonomous_PT_FaultMode_Spare132" 186 "Autonomous_PT_FaultMode_Spare131" 185 "Autonomous_PT_FaultMode_Spare130" 184 "Autonomous_PT_FaultMode_Spare129" 183 "Autonomous_PT_FaultMode_Spare128" 182 "Autonomous_PT_FaultMode_Spare127" 181 "Autonomous_PT_FaultMode_Spare126" 180 "Autonomous_PT_FaultMode_Spare125" 179 "Autonomous_PT_FaultMode_Spare124" 178 "Autonomous_PT_FaultMode_Spare123" 177 "Autonomous_PT_FaultMode_Spare122" 176 "Autonomous_PT_FaultMode_Spare121" 175 "Autonomous_PT_FaultMode_Spare120" 174 "Autonomous_PT_FaultMode_Spare119" 173 "Autonomous_PT_FaultMode_Spare118" 172 "Autonomous_PT_FaultMode_Spare117" 171 "Autonomous_PT_FaultMode_Spare116" 170 "Autonomous_PT_FaultMode_Spare115" 169 "Autonomous_PT_FaultMode_Spare114" 168 "Autonomous_PT_FaultMode_Spare113" 167 "Autonomous_PT_FaultMode_Spare112" 166 "Autonomous_PT_FaultMode_Spare111" 165 "Autonomous_PT_FaultMode_Spare110" 164 "Autonomous_PT_FaultMode_Spare109" 163 "Autonomous_PT_FaultMode_Spare108" 162 "Autonomous_PT_FaultMode_Spare107" 161 "Autonomous_PT_FaultMode_Spare106" 160 "Autonomous_PT_FaultMode_Spare105" 159 "Autonomous_PT_FaultMode_Spare104" 158 "Autonomous_PT_FaultMode_Spare103" 157 "Autonomous_PT_FaultMode_Spare102" 156 "Autonomous_PT_FaultMode_Spare101" 155 "Autonomous_PT_FaultMode_Spare100" 154 "Autonomous_PT_FaultMode_Spare99" 153 "Autonomous_PT_FaultMode_Spare98" 152 "Autonomous_PT_FaultMode_Spare97" 151 "Autonomous_PT_FaultMode_Spare96" 150 "Autonomous_PT_FaultMode_Spare95" 149 "Autonomous_PT_FaultMode_Spare94" 148 "Autonomous_PT_FaultMode_Spare93" 147 "Autonomous_PT_FaultMode_Spare92" 146 "Autonomous_PT_FaultMode_Spare91" 145 "Autonomous_PT_FaultMode_Spare90" 144 "Autonomous_PT_FaultMode_Spare89" 143 "Autonomous_PT_FaultMode_Spare88" 142 "Autonomous_PT_FaultMode_Spare87" 141 "Autonomous_PT_FaultMode_Spare86" 140 "Autonomous_PT_FaultMode_Spare85" 139 "Autonomous_PT_FaultMode_Spare84" 138 "Autonomous_PT_FaultMode_Spare83" 137 "Autonomous_PT_FaultMode_Spare82" 136 "Autonomous_PT_FaultMode_Spare81" 135 "Autonomous_PT_FaultMode_Spare80" 134 "Autonomous_PT_FaultMode_Spare79" 133 "Autonomous_PT_FaultMode_Spare78" 132 "Autonomous_PT_FaultMode_Spare77" 131 "Autonomous_PT_FaultMode_Spare76" 130 "Autonomous_PT_FaultMode_Spare75" 129 "Autonomous_PT_FaultMode_Spare74" 128 "Autonomous_PT_FaultMode_Spare73" 127 "Autonomous_PT_FaultMode_Spare72" 126 "Autonomous_PT_FaultMode_Spare71" 125 "Autonomous_PT_FaultMode_Spare70" 124 "Autonomous_PT_FaultMode_Spare69" 123 "Autonomous_PT_FaultMode_Spare68" 122 "Autonomous_PT_FaultMode_Spare67" 121 "Autonomous_PT_FaultMode_Spare66" 120 "Autonomous_PT_FaultMode_Spare65" 119 "Autonomous_PT_FaultMode_Spare64" 118 "Autonomous_PT_FaultMode_Spare63" 117 "Autonomous_PT_FaultMode_Spare62" 116 "Autonomous_PT_FaultMode_Spare61" 115 "Autonomous_PT_FaultMode_Spare60" 114 "Autonomous_PT_FaultMode_Spare59" 113 "Autonomous_PT_FaultMode_Spare58" 112 "Autonomous_PT_FaultMode_Spare57" 111 "Autonomous_PT_FaultMode_Spare56" 110 "Autonomous_PT_FaultMode_Spare55" 109 "Autonomous_PT_FaultMode_Spare54" 108 "Autonomous_PT_FaultMode_Spare53" 107 "Autonomous_PT_FaultMode_Spare52" 106 "Autonomous_PT_FaultMode_Spare51" 105 "Autonomous_PT_FaultMode_Spare50" 104 "Autonomous_PT_FaultMode_Spare49" 103 "Autonomous_PT_FaultMode_Spare48" 102 "Autonomous_PT_FaultMode_Spare47" 101 "Autonomous_PT_FaultMode_Spare46" 100 "Autonomous_PT_FaultMode_Spare45" 99 "Autonomous_PT_FaultMode_Spare44" 98 "Autonomous_PT_FaultMode_Spare43" 97 "Autonomous_PT_FaultMode_Spare42" 96 "Autonomous_PT_FaultMode_Spare41" 95 "Autonomous_PT_FaultMode_Spare40" 94 "Autonomous_PT_FaultMode_Spare39" 93 "Autonomous_PT_FaultMode_Spare38" 92 "Autonomous_PT_FaultMode_Spare37" 91 "Autonomous_PT_FaultMode_Spare36" 90 "Autonomous_PT_FaultMode_Spare35" 89 "Autonomous_PT_FaultMode_Spare34" 88 "Autonomous_PT_FaultMode_Spare33" 87 "Autonomous_PT_FaultMode_Spare32" 86 "Autonomous_PT_FaultMode_Spare31" 85 "Autonomous_PT_FaultMode_Spare30" 84 "Autonomous_PT_FaultMode_Spare29" 83 "Autonomous_PT_FaultMode_Spare28" 82 "Autonomous_PT_FaultMode_Spare27" 81 "Autonomous_PT_FaultMode_Spare26" 80 "Autonomous_PT_FaultMode_Spare25" 79 "Autonomous_PT_FaultMode_Spare24" 78 "Autonomous_PT_FaultMode_Spare23" 77 "Autonomous_PT_FaultMode_Spare22" 76 "Autonomous_PT_FaultMode_Spare21" 75 "Autonomous_PT_FaultMode_Spare20" 74 "Autonomous_PT_FaultMode_Spare19" 73 "Autonomous_PT_FaultMode_Spare18" 72 "Autonomous_PT_FaultMode_Spare17" 71 "Autonomous_PT_FaultMode_Spare16" 70 "Autonomous_PT_FaultMode_Spare15" 69 "Autonomous_PT_FaultMode_Spare14" 68 "Autonomous_PT_FaultMode_Spare13" 67 "Autonomous_PT_FaultMode_Spare12" 66 "Autonomous_PT_FaultMode_Spare11" 65 "Autonomous_PT_FaultMode_Spare10" 64 "Autonomous_PT_FaultMode_Spare9" 63 "Autonomous_PT_FaultMode_Spare8" 62 "Autonomous_PT_FaultMode_Spare7" 61 "Autonomous_PT_FaultMode_Spare6" 60 "Autonomous_PT_FaultMode_Spare5" 59 "Autonomous_PT_FaultMode_Spare4" 58 "Autonomous_PT_FaultMode_Spare3" 57 "Autonomous_PT_FaultMode_Spare2" 56 "Autonomous_PT_FaultMode_Spare1" 55 "Autonomous_PT_FaultMode_Spare0" 54 "Autonomous_PT_FaultMode_Eng_XrslbInterfaceNotAvl" 53 "Autonomous_PT_FaultMode_Eng_GcvwNotReliable" 52 "Autonomous_PT_FaultMode_Eng_KFactorNotAvl" 51 "Autonomous_PT_FaultMode_Eng_RoadIncNotAvl" 50 "Autonomous_PT_FaultMode_Eng_GbxGearInfoNotAvl" 49 "Autonomous_PT_FaultMode_Eng_BrkPdlNotAvl" 48 "Autonomous_PT_FaultMode_Eng_ParkBrkNotAvl" 47 "Autonomous_PT_FaultMode_Eng_VehSpdSignalsNotAvl" 46 "Autonomous_PT_FaultMode_Eng_XarInterfaceNotAvl" 45 "Autonomous_PT_FaultMode_Eng_AutoStateNotAvl" 44 "Autonomous_PT_FaultMode_Eng_SevereFaultActv" 43 "Autonomous_PT_FaultMode_Eng_FdnBrkCapacityNotAvl" 42 "Autonomous_PT_FaultMode_Eng_XbrInterfaceNotAvl" 41 "Autonomous_PT_FaultMode_Eng_AbsNotOperational" 40 "Autonomous_PT_FaultMode_Eng_TrailerAbsNotAvl" 39 "Autonomous_PT_FaultMode_Eng_AirGasSystem" 38 "Autonomous_PT_FaultMode_Eng_EatsInducement" 37 "Autonomous_PT_FaultMode_Eng_FuelInjSystem" 36 "Autonomous_PT_FaultMode_Eng_ColdStart" 35 "Autonomous_PT_FaultMode_Eng_CrankDampersProt" 34 "Autonomous_PT_FaultMode_Eng_Electrical" 33 "Autonomous_PT_FaultMode_Eng_DrivelineProt" 32 "Autonomous_PT_FaultMode_Eng_FuelEco" 31 "Autonomous_PT_FaultMode_Eng_RodMode" 30 "Autonomous_PT_FaultMode_Eng_SuperCharger" 29 "Autonomous_PT_FaultMode_Eng_ExhManProt" 28 "Autonomous_PT_FaultMode_Eng_SigCalc" 27 "Autonomous_PT_FaultMode_Eng_CatTemp" 26 "Autonomous_PT_FaultMode_Eng_EngProt" 25 "Autonomous_PT_FaultMode_Eng_Altitude" 24 "Autonomous_PT_FaultMode_Eng_HiHeat" 23 "Autonomous_PT_FaultMode_Eng_Egr" 22 "Autonomous_PT_FaultMode_Eng_AmbTemp" 21 "Autonomous_PT_FaultMode_Eng_AmbTempAlt" 20 "Autonomous_PT_FaultMode_Gbx_AbsNotOperational" 19 "Autonomous_PT_FaultMode_Gbx_FallbackMode" 18 "Autonomous_PT_FaultMode_Gbx_AbsInterfaceNotAvl" 17 "Autonomous_PT_FaultMode_Gbx_AdasisInterfaceNotAvl" 16 "Autonomous_PT_FaultMode_Gbx_AutoEngineStatusNotAvl" 15 "Autonomous_PT_FaultMode_Gbx_OutputSpeedVecuNotAvl" 14 "Autonomous_PT_FaultMode_Gbx_EngineSpeedNotAvl" 13 "Autonomous_PT_FaultMode_Gbx_FrontSpeedNotAvl" 12 "Autonomous_PT_FaultMode_Gbx_BrkPdlNotAvl" 11 "Autonomous_PT_FaultMode_Gbx_AccSgoNotAvl" 10 "Autonomous_PT_FaultMode_Gbx_DisengageDrivelineRequestNotAvl" 9 "Autonomous_PT_FaultMode_Gbx_WheelDistStopInterfaceNotAvl" 8 "Autonomous_PT_FaultMode_Gbx_XarInterfaceNotAvl" 7 "Autonomous_PT_FaultMode_Gbx_ReqDrivingDirectionNotAvl" 6 "Autonomous_PT_FaultMode_Gbx_AutoStateNotAvl" 5 "Autonomous_PT_FaultMode_Gbx_AutoDriveModeNotAvl" 4 "Autonomous_PT_FaultMode_Gbx_PreviewSpeedUnreliable" 3 "Autonomous_PT_FaultMode_Gbx_PreviewSlopeUnreliable" 2 "Autonomous_PT_FaultMode_Gbx_ClutchOverheated" 1 "Autonomous_PT_FaultMode_Gbx_LowAirPressure" 0 "Autonomous_PT_FaultMode_Pwt_FullyOperational" ;
VAL_ 2499792656 DrivelineRetarderStat_ISig_1 3 "DrivelineRetarderStat_NotAvailable" 2 "DrivelineRetarderStat_Error" 1 "DrivelineRetarderStat_RetarderCapacityDerated" 0 "DrivelineRetarderStat_RetarderCapacityNotDerated" ;
VAL_ 2566840592 DrivelineRetarderLocation 15 "DrivelineRetarderLocation_NotAvailable" 14 "DrivelineRetarderLocation_Other" 13 "DrivelineRetarderLocation_NotDefined_07" 12 "DrivelineRetarderLocation_NotDefined_06" 11 "DrivelineRetarderLocation_NotDefined_05" 10 "DrivelineRetarderLocation_NotDefined_04" 9 "DrivelineRetarderLocation_NotDefined_03" 8 "DrivelineRetarderLocation_NotDefined_02" 7 "DrivelineRetarderLocation_NotDefined_01" 6 "DrivelineRetarderLocation_NotDefined" 5 "DrivelineRetarderLocation_TrailerVehicleSpeed" 4 "DrivelineRetarderLocation_SecondaryDrivelineOutputShaftRpm" 3 "DrivelineRetarderLocation_SecondaryTransmissionOutput" 2 "DrivelineRetarderLocation_PrimaryTransmissionInputEngineRpm" 1 "DrivelineRetarderLocation_PrimaryEngineExhaustBrake" 0 "DrivelineRetarderLocation_PrimaryEngineCompressionReleaseBrake" ;
VAL_ 2566840592 DrivelineRetarderType 15 "DrivelineRetarderType_NotAvailable" 14 "DrivelineRetarderType_Other" 13 "DrivelineRetarderType_NotDefined_08" 12 "DrivelineRetarderType_NotDefined_07" 11 "DrivelineRetarderType_NotDefined_06" 10 "DrivelineRetarderType_NotDefined_05" 9 "DrivelineRetarderType_NotDefined_04" 8 "DrivelineRetarderType_NotDefined_03" 7 "DrivelineRetarderType_NotDefined_02" 6 "DrivelineRetarderType_NotDefined_01" 5 "DrivelineRetarderType_NotDefined" 4 "DrivelineRetarderType_Exhaust" 3 "DrivelineRetarderType_CompressionRelease" 2 "DrivelineRetarderType_CooledFriction" 1 "DrivelineRetarderType_Hydraulic" 0 "DrivelineRetarderType_ElectricMagnetic" ;
VAL_ 2566759457 Pto1EnableSwitch 3 "OffOn_NotAvailable" 2 "OffOn_Error" 1 "OffOn_On" 0 "OffOn_Off" ;
VAL_ 2566759457 Pto2EnableSwitch 3 "OffOn_NotAvailable" 2 "OffOn_Error" 1 "OffOn_On" 0 "OffOn_Off" ;
VAL_ 2566759427 Pto2EngagementConsent 3 "PtoConsent_NotAvailable" 2 "PtoConsent_Error" 1 "PtoConsent_ConsentGivenPTODriveMayBeEngaged" 0 "PtoConsent_ConsentNotGivenPTODriveShouldNotBeEngaged" ;
VAL_ 2566759427 Pto1EngagementConsent 3 "PtoConsent_NotAvailable" 2 "PtoConsent_Error" 1 "PtoConsent_ConsentGivenPTODriveMayBeEngaged" 0 "PtoConsent_ConsentNotGivenPTODriveShouldNotBeEngaged" ;
VAL_ 2566801923 TransmEngineCrankEnable_ISig_1 3 "DisableEnable_NotAvailable" 2 "DisableEnable_Error" 1 "DisableEnable_Enable" 0 "DisableEnable_Disable" ;
VAL_ 2364539395 TransmissionShiftInProcess 3 "TransmissionShiftInProcess_NotAvailable" 2 "TransmissionShiftInProcess_Error" 1 "TransmissionShiftInProcess_ShiftInProcess" 0 "TransmissionShiftInProcess_ShiftNotInProcess" ;
VAL_ 2364539395 TransmissionDrivelineEngaged_ISi 3 "DisengageEngage_NotAvailable" 2 "DisengageEngage_Error" 1 "DisengageEngage_Engage" 0 "DisengageEngage_Disengage" ;
VAL_ 2364539395 MomentaryEngineOverspeedEnable 3 "DisableEnable_NotAvailable" 2 "DisableEnable_Error" 1 "DisableEnable_Enable" 0 "DisableEnable_Disable" ;
VAL_ 2364539395 TransmTrqConvrtrLockupEngd 3 "DisengageEngage_NotAvailable" 2 "DisengageEngage_Error" 1 "DisengageEngage_Engage" 0 "DisengageEngage_Disengage" ;
VAL_ 2565865488 RetarderTorqueMode 15 "RetarderTorqueMode_NotAvailable" 14 "RetarderTorqueMode_Other" 13 "RetarderTorqueMode_NotDefined" 12 "RetarderTorqueMode_ServiceProcedure" 11 "RetarderTorqueMode_RemoteAccelerator" 10 "RetarderTorqueMode_BrakingSystem" 9 "RetarderTorqueMode_HighSpeedGovernor" 8 "RetarderTorqueMode_TorqueLimiting" 7 "RetarderTorqueMode_ABSControl" 6 "RetarderTorqueMode_TransmissionControl" 5 "RetarderTorqueMode_ASRControl" 4 "RetarderTorqueMode_RoadSpeedGovernor" 3 "RetarderTorqueMode_PTOGovernor" 2 "RetarderTorqueMode_CruiseControl" 1 "RetarderTorqueMode_AcceleratorPedalOperatorSelection" 0 "RetarderTorqueMode_LowIdleGovernorNoRequestDefaultMode" ;
VAL_ 2565865488 EngineCoolantLoadIncrease 3 "EngineCoolantLoadIncrease_NotAvailable" 2 "EngineCoolantLoadIncrease_Error" 1 "EngineCoolantLoadIncrease_CoolantLoadIncreasePossible" 0 "EngineCoolantLoadIncrease_NoCoolantLoadIncrease" ;
VAL_ 2565865487 EngRetdrEnableBrakeAssistSw 3 "DisableEnable_NotAvailable" 2 "DisableEnable_Error" 1 "DisableEnable_Enable" 0 "DisableEnable_Disable" ;
VAL_ 2565865487 EngineRetarderTorqueMode 15 "EngineRetarderTorqueMode_NotAvailable" 14 "EngineRetarderTorqueMode_Other" 13 "EngineRetarderTorqueMode_NotDefined" 12 "EngineRetarderTorqueMode_ServiceProcedure" 11 "EngineRetarderTorqueMode_RemoteAccelerator" 10 "EngineRetarderTorqueMode_BrakingSystem" 9 "EngineRetarderTorqueMode_HighSpeedGovernor" 8 "EngineRetarderTorqueMode_TorqueLimiting" 7 "EngineRetarderTorqueMode_ABSControl" 6 "EngineRetarderTorqueMode_TransmissionControl" 5 "EngineRetarderTorqueMode_ASRControl" 4 "EngineRetarderTorqueMode_RoadSpeedGovernor" 3 "EngineRetarderTorqueMode_PTOGovernor" 2 "EngineRetarderTorqueMode_CruiseControl" 1 "EngineRetarderTorqueMode_AcceleratorPedalOperatorSelection" 0 "EngineRetarderTorqueMode_LowIdleGovernorNoRequestDefaultMode" ;
VAL_ 2565865487 RetarderEnableShiftAssistSw 3 "DisableEnable_NotAvailable" 2 "DisableEnable_Error" 1 "DisableEnable_Enable" 0 "DisableEnable_Disable" ;
VAL_ 2566864640 EngineActiveStatus_ISig_1 15 "EngineActiveStatus_NotAvailable" 14 "EngineActiveStatus_Error" 13 "EngineActiveStatus_Spare_10" 12 "EngineActiveStatus_Spare_09" 11 "EngineActiveStatus_Spare_08" 10 "EngineActiveStatus_Spare_07" 9 "EngineActiveStatus_Spare_06" 8 "EngineActiveStatus_Spare_05" 7 "EngineActiveStatus_Spare_04" 6 "EngineActiveStatus_Spare_03" 5 "EngineActiveStatus_Spare_02" 4 "EngineActiveStatus_Spare_01" 3 "EngineActiveStatus_EngineStandby" 2 "EngineActiveStatus_ElectricPropulsionSystemRunning" 1 "EngineActiveStatus_InternalCombustionEngineRunning" 0 "EngineActiveStatus_DrivelineNotActive" ;
VAL_ 2364539648 RoadSpeedLimitStatus 3 "ActiveNotActive_NotAvailable" 2 "ActiveNotActive_Error" 1 "ActiveNotActive_NotActive" 0 "ActiveNotActive_Active" ;
VAL_ 2364539904 EngineStarterMode_ISig_1 15 "EngineStarterMode_NotAvailable" 14 "EngineStarterMode_Error" 13 "EngineStarterMode_NotToBeUsed" 12 "EngineStarterMode_StarterInhibitedReasonUnknown" 11 "EngineStarterMode_Reserved_02" 10 "EngineStarterMode_Reserved_01" 9 "EngineStarterMode_Reserved" 8 "EngineStarterMode_StarterInhibitedDueToStarterOverTemp" 7 "EngineStarterMode_StarterInhibitedDueToActiveImmobilizer" 6 "EngineStarterMode_StarterInhibitedDueToDrivelineEngagedOrOther" 5 "EngineStarterMode_StarterInhibitedDueToEngineNotReadyForStart" 4 "EngineStarterMode_StarterInhibitedDueToEngineAlreadyRunning" 3 "EngineStarterMode_StartFinishedStarterNotActiveAfterHavingBe" 2 "EngineStarterMode_StarterActiveGearEngaged" 1 "EngineStarterMode_StarterActiveGearNotEngaged" 0 "EngineStarterMode_StartNotRequested" ;
VAL_ 2364539904 EngineTorqueMode 15 "EngineTorqueMode_NotAvailable" 14 "EngineTorqueMode_Other" 13 "EngineTorqueMode_AirManagement" 12 "EngineTorqueMode_ServiceProcedure" 11 "EngineTorqueMode_RemoteAccelerator" 10 "EngineTorqueMode_BrakingSystem" 9 "EngineTorqueMode_HighSpeedGovernor" 8 "EngineTorqueMode_TorqueLimiting" 7 "EngineTorqueMode_ABSControl" 6 "EngineTorqueMode_TransmissionControl" 5 "EngineTorqueMode_ASRControl" 4 "EngineTorqueMode_RoadSpeedGovernor" 3 "EngineTorqueMode_PTOGovernor" 2 "EngineTorqueMode_CruiseControl" 1 "EngineTorqueMode_AcceleratorPedalOperatorSelection" 0 "EngineTorqueMode_LowIdleGovernorNoRequestDefaultMode" ;
VAL_ 2566911243 Trailer5EBSRedWarning 3 "OffOn_NotAvailable" 2 "OffOn_Error" 1 "OffOn_On" 0 "OffOn_Off" ;
VAL_ 2566911243 Trailer5ExtLvlStorageSupport 3 "TrailerExtLvlStorageSupport_NotSupported" 2 "TrailerExtLvlStorageSupport_Error" 1 "TrailerExtLvlStorageSupport_SupportedIn2ExtendedSets" 0 "TrailerExtLvlStorageSupport_SupportedInAll3Sets" ;
VAL_ 2566911243 Trailer5LoadRampApprAssistStat 3 "ActiveStatus_NotAvailable" 2 "ActiveStatus_Error" 1 "ActiveStatus_Active" 0 "ActiveStatus_NotActive" ;
VAL_ 2566911243 Trailer5VehicleType 3 "TrailerVehicleType_NotAvailable" 2 "TrailerVehicleType_Error" 1 "TrailerVehicleType_ConverterDollyAxle" 0 "TrailerVehicleType_TowingOrTowedVehicle" ;
VAL_ 2566911243 Trailer5EBSAmberWarning 3 "WarningIndicator_NotAvailable" 2 "WarningIndicator_Flashing" 1 "WarningIndicator_OnContinuously" 0 "WarningIndicator_Off" ;
VAL_ 2566911243 Trailer5LevelControlStatus 3 "DisableEnable_NotAvailable" 2 "DisableEnable_Error" 1 "DisableEnable_Enable" 0 "DisableEnable_Disable" ;
VAL_ 2566911243 Trailer5PneumSupply_Status 3 "InsufficientSufficient_NotAvailable" 2 "InsufficientSufficient_Error" 1 "InsufficientSufficient_Sufficient" 0 "InsufficientSufficient_Insufficient" ;
VAL_ 2566911243 Trailer5ROPSystemStatus 3 "DisableEnable_NotAvailable" 2 "DisableEnable_Error" 1 "DisableEnable_Enable" 0 "DisableEnable_Disable" ;
VAL_ 2566911243 Trailer5ElectricalSupplyStat 3 "InsufficientSufficient_NotAvailable" 2 "InsufficientSufficient_Error" 1 "InsufficientSufficient_Sufficient" 0 "InsufficientSufficient_Insufficient" ;
VAL_ 2566911243 Trailer5YCSystemStatus 3 "DisableEnable_NotAvailable" 2 "DisableEnable_Error" 1 "DisableEnable_Enable" 0 "DisableEnable_Disable" ;
VAL_ 2566906891 Trailer4LoadRampApprAssistStat 3 "ActiveStatus_NotAvailable" 2 "ActiveStatus_Error" 1 "ActiveStatus_Active" 0 "ActiveStatus_NotActive" ;
VAL_ 2566906891 Trailer4EBSRedWarning 3 "OffOn_NotAvailable" 2 "OffOn_Error" 1 "OffOn_On" 0 "OffOn_Off" ;
VAL_ 2566906891 Trailer4EBSAmberWarning 3 "WarningIndicator_NotAvailable" 2 "WarningIndicator_Flashing" 1 "WarningIndicator_OnContinuously" 0 "WarningIndicator_Off" ;
VAL_ 2566906891 Trailer4ExtLvlStorageSupport 3 "TrailerExtLvlStorageSupport_NotSupported" 2 "TrailerExtLvlStorageSupport_Error" 1 "TrailerExtLvlStorageSupport_SupportedIn2ExtendedSets" 0 "TrailerExtLvlStorageSupport_SupportedInAll3Sets" ;
VAL_ 2566906891 Trailer4VehicleType 3 "TrailerVehicleType_NotAvailable" 2 "TrailerVehicleType_Error" 1 "TrailerVehicleType_ConverterDollyAxle" 0 "TrailerVehicleType_TowingOrTowedVehicle" ;
VAL_ 2566906891 Trailer4YCSystemStatus 3 "DisableEnable_NotAvailable" 2 "DisableEnable_Error" 1 "DisableEnable_Enable" 0 "DisableEnable_Disable" ;
VAL_ 2566906891 Trailer4ElectricalSupplyStat 3 "InsufficientSufficient_NotAvailable" 2 "InsufficientSufficient_Error" 1 "InsufficientSufficient_Sufficient" 0 "InsufficientSufficient_Insufficient" ;
VAL_ 2566906891 Trailer4LevelControlStatus 3 "DisableEnable_NotAvailable" 2 "DisableEnable_Error" 1 "DisableEnable_Enable" 0 "DisableEnable_Disable" ;
VAL_ 2566906891 Trailer4ROPSystemStatus 3 "DisableEnable_NotAvailable" 2 "DisableEnable_Error" 1 "DisableEnable_Enable" 0 "DisableEnable_Disable" ;
VAL_ 2566906891 Trailer4PneumSupply_Status 3 "InsufficientSufficient_NotAvailable" 2 "InsufficientSufficient_Error" 1 "InsufficientSufficient_Sufficient" 0 "InsufficientSufficient_Insufficient" ;
VAL_ 2566902283 Trailer3VehicleType 3 "TrailerVehicleType_NotAvailable" 2 "TrailerVehicleType_Error" 1 "TrailerVehicleType_ConverterDollyAxle" 0 "TrailerVehicleType_TowingOrTowedVehicle" ;
VAL_ 2566902283 Trailer3PneumSupply_Status 3 "InsufficientSufficient_NotAvailable" 2 "InsufficientSufficient_Error" 1 "InsufficientSufficient_Sufficient" 0 "InsufficientSufficient_Insufficient" ;
VAL_ 2566902283 Trailer3ExtLvlStorageSupport 3 "TrailerExtLvlStorageSupport_NotSupported" 2 "TrailerExtLvlStorageSupport_Error" 1 "TrailerExtLvlStorageSupport_SupportedIn2ExtendedSets" 0 "TrailerExtLvlStorageSupport_SupportedInAll3Sets" ;
VAL_ 2566902283 Trailer3LoadRampApprAssistStat 3 "ActiveStatus_NotAvailable" 2 "ActiveStatus_Error" 1 "ActiveStatus_Active" 0 "ActiveStatus_NotActive" ;
VAL_ 2566902283 Trailer3ElectricalSupplyStat 3 "InsufficientSufficient_NotAvailable" 2 "InsufficientSufficient_Error" 1 "InsufficientSufficient_Sufficient" 0 "InsufficientSufficient_Insufficient" ;
VAL_ 2566902283 Trailer3EBSRedWarning 3 "OffOn_NotAvailable" 2 "OffOn_Error" 1 "OffOn_On" 0 "OffOn_Off" ;
VAL_ 2566902283 Trailer3ROPSystemStatus 3 "DisableEnable_NotAvailable" 2 "DisableEnable_Error" 1 "DisableEnable_Enable" 0 "DisableEnable_Disable" ;
VAL_ 2566902283 Trailer3EBSAmberWarning 3 "WarningIndicator_NotAvailable" 2 "WarningIndicator_Flashing" 1 "WarningIndicator_OnContinuously" 0 "WarningIndicator_Off" ;
VAL_ 2566902283 Trailer3LevelControlStatus 3 "DisableEnable_NotAvailable" 2 "DisableEnable_Error" 1 "DisableEnable_Enable" 0 "DisableEnable_Disable" ;
VAL_ 2566902283 Trailer3YCSystemStatus 3 "DisableEnable_NotAvailable" 2 "DisableEnable_Error" 1 "DisableEnable_Enable" 0 "DisableEnable_Disable" ;
SIG_GROUP_ 2348814097 TSC1EMSrVMCU_sg 1 : TSC1EMSrVMCU_EnRTrqTrqLm TSC1EMSrVMCU_EnRSpdCtrlC TSC1EMSrVMCU_OvrdCtrlMPr TSC1EMSrVMCU_EnOvrdCtrlM TSC1EMSrVMCU_EnRSpdSpdLm;
SIG_GROUP_ 2348814083 TSC1EMSrTECU_sg 1 : TSC1EMSrTECU_EnOvrdCtrlM TSC1EMSrTECU_EnRSpdCtrlC TSC1EMSrTECU_EnRTrqTrqLm TSC1EMSrTECU_EnRSpdSpdLm TSC1EMSrTECU_OvrdCtrlMPr;
SIG_GROUP_ 2348814091 TSC1EMSrABS_sg 1 : TSC1EMSrABS_OvrdCtrlMPr TSC1EMSrABS_EnRTrqTrqLm TSC1EMSrABS_EnRSpdCtrlC TSC1EMSrABS_EnOvrdCtrlM TSC1EMSrABS_EnRSpdSpdLm;
SIG_GROUP_ 2566852619 WheelCircumference_sg 1 : WheelCircumference_TireId WheelCircumference_Value;
SIG_GROUP_ 2566911243 Trailer5NomBodyLevel_sg 1 : Trailer5NomBodyLevel_FrontLevel Trailer5NomBodyLevel_RearLevel;
SIG_GROUP_ 2566911243 Trailer5PneumSupply_sg 1 : Trailer5PneumSupply_Pressure Trailer5PneumSupply_Status;
SIG_GROUP_ 2566906891 Trailer4PneumSupply_sg 1 : Trailer4PneumSupply_Pressure Trailer4PneumSupply_Status;
SIG_GROUP_ 2566906891 Trailer4NomBodyLevel_sg 1 : Trailer4NomBodyLevel_RearLevel Trailer4NomBodyLevel_FrontLevel;
SIG_GROUP_ 2566902283 Trailer3PneumSupply_sg 1 : Trailer3PneumSupply_Status Trailer3PneumSupply_Pressure;
SIG_GROUP_ 2566902283 Trailer3NomBodyLevel_sg 1 : Trailer3NomBodyLevel_FrontLevel Trailer3NomBodyLevel_RearLevel;
